VERSION ""

NS_ :

BS_:

BU_: ETH

BO_ 691 VCRIGHT_logging1Hz: 8 Vector__XXX
 SG_ VCRIGHT_logging1HzIndex M : 0|5@1+ (1,0) [0|0] "" Vector__XXX
 SG_ VCRIGHT_cabinOverheatProtectNotRunningReasonRaw m15 : 5|14@1+ (1,0) [0|0] "" Vector__XXX
 SG_ VCRIGHT_convectionTargetLeft m4 : 5|9@1+ (4,-1000) [0|0] "" Vector__XXX
 SG_ VCRIGHT_hvacCabOvrheatProtActive m8 : 5|1@1+ (1,0) [0|0] "" Vector__XXX
 SG_ VCRIGHT_hvacFoggingRiskLevelFeedforwardConservativeEst m5 : 5|6@1+ (1.6,0) [0|0] "" Vector__XXX
 SG_ VCRIGHT_hvacMassflowTargetLeft m12 : 5|8@1+ (1,0) [0|0] "" Vector__XXX
 SG_ VCRIGHT_leftHeatOvertempProtect m9 : 5|1@1+ (1,0) [0|0] "" Vector__XXX
 SG_ VCRIGHT_lumbarCurrent m10 : 5|4@1+ (0.2,0) [0|0] "" Vector__XXX
 SG_ VCRIGHT_maxMassflowScalar m13 : 5|6@1+ (1,60) [0|0] "" Vector__XXX
 SG_ VCRIGHT_pcbaTemperature m2 : 5|11@1+ (0.125,-40) [0|0] "" Vector__XXX
 SG_ VCRIGHT_steeringWheelSurfaceTempEst m14 : 5|10@1+ (0.1,-35) [0|0] "" Vector__XXX
 SG_ VCRIGHT_hvacCabinPurgeAllowed m8 : 6|1@1+ (1,0) [0|0] "" Vector__XXX
 SG_ VCRIGHT_rightHeatOvertempProtect m9 : 6|1@1+ (1,0) [0|0] "" Vector__XXX
 SG_ VCRIGHT_CO2ppm m9 : 7|10@1+ (5,0) [0|0] "" Vector__XXX
 SG_ VCRIGHT_hvacCabOvrheatProtAllowed m8 : 7|1@1+ (1,0) [0|0] "" Vector__XXX
 SG_ VCRIGHT_cabinTempBreathLevelFHeating m7 : 8|8@1+ (0.5,-40) [0|0] "" Vector__XXX
 SG_ VCRIGHT_cabinTempGlassRoof m1 : 8|8@1+ (0.5,-40) [0|0] "" Vector__XXX
 SG_ VCRIGHT_filterLifeBlowerTorque m8 : 8|10@1+ (0.006,-1.5) [0|0] "" Vector__XXX
 SG_ VCRIGHT_hvacEstimatedCameraWindshieldRH m16 : 8|8@1+ (1,0) [0|0] "" Vector__XXX
 SG_ VCRIGHT_hvacLHBleedVoltage m6 : 8|8@1+ (0.02,0) [0|0] "" Vector__XXX
 SG_ VCRIGHT_hvacSetTempActualLeft m3 : 8|8@1+ (0.1,15) [0|0] "" Vector__XXX
 SG_ VCRIGHT_tempIncarCabinProbe m0 : 8|8@1+ (0.5,-40) [0|0] "" Vector__XXX
 SG_ VCRIGHT_trunkInteriorLEDCurrent m11 : 8|4@1+ (5,0) [0|0] "" Vector__XXX
 SG_ VCRIGHT_ocsCurrent m10 : 9|3@1+ (0.01,0) [0|0] "" Vector__XXX
 SG_ VCRIGHT_hvacFoggingRiskLevelFeedforwardConservativeTar m5 : 11|6@1+ (1.6,0) [0|0] "" Vector__XXX
 SG_ VCRIGHT_massflowTargetAutoInManualMode m13 : 11|8@1+ (1,0) [0|0] "" Vector__XXX
 SG_ VCRIGHT_mapPocketLEDsCurrent m11 : 12|4@1+ (5,0) [0|0] "" Vector__XXX
 SG_ VCRIGHT_rcmCurrent m10 : 12|5@1+ (0.1,0) [0|0] "" Vector__XXX
 SG_ VCRIGHT_hvacMassflowTargetRight m12 : 13|8@1+ (1,0) [0|0] "" Vector__XXX
 SG_ VCRIGHT_convectionTargetRight m4 : 14|9@1+ (4,-1000) [0|0] "" Vector__XXX
 SG_ VCRIGHT_cabinTempBreathLevelFCooling m7 : 16|8@1+ (0.5,-40) [0|0] "" Vector__XXX
 SG_ VCRIGHT_cabinTempInteriorL2 m0 : 16|8@1+ (0.5,-40) [0|0] "" Vector__XXX
 SG_ VCRIGHT_cabinTempWindshield m1 : 16|8@1+ (0.5,-40) [0|0] "" Vector__XXX
 SG_ VCRIGHT_hvacRHBleedVoltage m6 : 16|8@1+ (0.02,0) [0|0] "" Vector__XXX
 SG_ VCRIGHT_hvacSetTempActualRight m3 : 16|8@1+ (0.1,15) [0|0] "" Vector__XXX
 SG_ VCRIGHT_miscEFuseCurrent m11 : 16|5@1+ (0.05,0) [0|0] "" Vector__XXX
 SG_ VCRIGHT_steeringWheelSurfaceTempTgt m14 : 16|10@1+ (0.1,-35) [0|0] "" Vector__XXX
 SG_ VCRIGHT_wattsHeaterLeftTotal m2 : 16|10@1+ (5,0) [0|0] "" Vector__XXX
 SG_ VCRIGHT_hvacFoggingRiskLevelConservativeTar m5 : 17|6@1+ (1.6,0) [0|0] "" Vector__XXX
 SG_ VCRIGHT_radioTunerCurrent m10 : 17|4@1+ (0.1,0) [0|0] "" Vector__XXX
 SG_ VCRIGHT_timeLeftToCabinModelInit m9 : 17|7@1+ (1,0) [0|0] "" Vector__XXX
 SG_ VCRIGHT_cabinTempFanCurrent m8 : 18|6@1+ (0.001,-0.01) [0|0] "" Vector__XXX
 SG_ VCRIGHT_airflowReasonAutoInManualMode m13 : 19|5@1+ (1,0) [0|0] "" Vector__XXX
 SG_ VCRIGHT_hvacIntakeReason m15 : 19|5@1+ (1,0) [0|0] "" Vector__XXX
 SG_ VCRIGHT_interiorHandleLEDCurrent m11 : 21|4@1+ (2,0) [0|0] "" Vector__XXX
 SG_ VCRIGHT_rearOilPumpCurrent m10 : 21|5@1+ (0.5,0) [0|0] "" Vector__XXX
 SG_ VCRIGHT_solarLoadLeftOccupantFilt m12 : 21|7@1+ (2,0) [0|0] "" Vector__XXX
 SG_ VCRIGHT_convectionDeliveredLeft m4 : 23|9@1+ (4,-1000) [0|0] "" Vector__XXX
 SG_ VCRIGHT_ptcHeaterTempDuctHigh m5 : 23|1@1+ (1,0) [0|0] "" Vector__XXX
 SG_ VCRIGHT_airflowReasonAutoInManualModeLeft m13 : 24|5@1+ (1,0) [0|0] "" Vector__XXX
 SG_ VCRIGHT_cabinTempFanOutput m8 : 24|1@1+ (1,0) [0|0] "" Vector__XXX
 SG_ VCRIGHT_cabinTempInterior m1 : 24|8@1+ (0.5,-40) [0|0] "" Vector__XXX
 SG_ VCRIGHT_cabinTempInteriorFHeating m7 : 24|8@1+ (0.5,-40) [0|0] "" Vector__XXX
 SG_ VCRIGHT_cabinTempInteriorSunnyL2 m0 : 24|8@1+ (0.6,-40) [0|0] "" Vector__XXX
 SG_ VCRIGHT_cabinTempRoofL2 m16 : 24|8@1+ (0.5,-40) [0|0] "" Vector__XXX
 SG_ VCRIGHT_hvacAutoTransitionReason m3 : 24|5@1+ (1,0) [0|0] "" Vector__XXX
 SG_ VCRIGHT_hvacCabinPurgeActive m15 : 24|1@1+ (1,0) [0|0] "" Vector__XXX
 SG_ VCRIGHT_hvacEstimateWindshieldRH m9 : 24|8@1+ (1,0) [0|0] "" Vector__XXX
 SG_ VCRIGHT_hvacLHVaneVoltage m6 : 24|8@1+ (0.02,0) [0|0] "" Vector__XXX
 SG_ VCRIGHT_ptcHeaterTempDuctFault m5 : 24|1@1+ (1,0) [0|0] "" Vector__XXX
 SG_ VCRIGHT_cloudinessEstimatedPct m8 : 25|7@1+ (1,0) [0|0] "" Vector__XXX
 SG_ VCRIGHT_miscInteriorLightsCurrent m11 : 25|3@1+ (5,0) [0|0] "" Vector__XXX
 SG_ VCRIGHT_ptcHeaterNoAirflow m5 : 25|1@1+ (1,0) [0|0] "" Vector__XXX
 SG_ VCRIGHT_solarAzimuthCarRef m15 : 25|11@1- (0.5,0) [0|0] "" Vector__XXX
 SG_ VCRIGHT_ptcHeaterHvacActNotReady m5 : 26|1@1+ (1,0) [0|0] "" Vector__XXX
 SG_ VCRIGHT_rearDefrostCurrent m10 : 26|5@1+ (2,0) [0|0] "" Vector__XXX
 SG_ VCRIGHT_timeToComfortHeating m14 : 26|6@1+ (15,-15) [0|0] "" Vector__XXX
 SG_ VCRIGHT_wattsHeaterRightTotal m2 : 26|10@1+ (5,0) [0|0] "" Vector__XXX
 SG_ VCRIGHT_ptcHeaterNoUiRequest m5 : 27|1@1+ (1,0) [0|0] "" Vector__XXX
 SG_ VCRIGHT_frontPuddleLEDCurrent m11 : 28|3@1+ (0.05,0) [0|0] "" Vector__XXX
 SG_ VCRIGHT_ptcHeaterNoHighVoltage m5 : 28|1@1+ (1,0) [0|0] "" Vector__XXX
 SG_ VCRIGHT_solarLoadRightOccupantFilt m12 : 28|7@1+ (2,0) [0|0] "" Vector__XXX
 SG_ VCRIGHT_airflowReasonAutoInManualModeRight m13 : 29|5@1+ (1,0) [0|0] "" Vector__XXX
 SG_ VCRIGHT_hvacMassflowTarget m3 : 29|8@1+ (1,0) [0|0] "" Vector__XXX
 SG_ VCRIGHT_ptcHeaterLAirPathBlocked m5 : 29|1@1+ (1,0) [0|0] "" Vector__XXX
 SG_ VCRIGHT_ptcHeaterRAirPathBlocked m5 : 30|1@1+ (1,0) [0|0] "" Vector__XXX
 SG_ VCRIGHT_ptcHeaterReqAirpathBlocked m5 : 31|1@1+ (1,0) [0|0] "" Vector__XXX
 SG_ VCRIGHT_rearPuddleLEDCurrent m11 : 31|3@1+ (0.05,0) [0|0] "" Vector__XXX
 SG_ VCRIGHT_tailLightCurrent m10 : 31|4@1+ (0.1,0) [0|0] "" Vector__XXX
 SG_ VCRIGHT_cabinTempInteriorSunny m1 : 32|8@1+ (0.6,-40) [0|0] "" Vector__XXX
 SG_ VCRIGHT_cabinTempRoofL3 m16 : 32|8@1+ (0.5,-40) [0|0] "" Vector__XXX
 SG_ VCRIGHT_convectionDeliveredRight m4 : 32|9@1+ (4,-1000) [0|0] "" Vector__XXX
 SG_ VCRIGHT_hvacFoggingRiskLevel m9 : 32|7@1+ (1,0) [0|0] "" Vector__XXX
 SG_ VCRIGHT_hvacFoggingRiskLevelConservativeEst m7 : 32|6@1+ (1.6,0) [0|0] "" Vector__XXX
 SG_ VCRIGHT_hvacQdotFeedforward m5 : 32|16@1+ (1,-32767) [0|0] "" Vector__XXX
 SG_ VCRIGHT_hvacRHVaneVoltage m6 : 32|8@1+ (0.02,0) [0|0] "" Vector__XXX
 SG_ VCRIGHT_solarLoadOnVehFiltered m8 : 32|8@1+ (4,0) [0|0] "" Vector__XXX
 SG_ VCRIGHT_tempIncarCabinMid m0 : 32|8@1+ (0.5,-40) [0|0] "" Vector__XXX
 SG_ VCRIGHT_timeToComfortCooling m14 : 32|6@1+ (15,-15) [0|0] "" Vector__XXX
 SG_ VCRIGHT_cabinTempInteriorFCooling m13 : 34|8@1+ (0.5,-40) [0|0] "" Vector__XXX
 SG_ VCRIGHT_liftgateShutfaceLEDCurrent m11 : 34|3@1+ (5,0) [0|0] "" Vector__XXX
 SG_ VCRIGHT_turnTailStopLightCurrent m10 : 35|4@1+ (0.1,0) [0|0] "" Vector__XXX
 SG_ VCRIGHT_windshieldRHCapped m12 : 35|8@1+ (1,0) [0|0] "" Vector__XXX
 SG_ VCRIGHT_massflowPulldownBias m15 : 36|4@1+ (7,0) [0|0] "" Vector__XXX
 SG_ VCRIGHT_qdotLeftFFUnsat m2 : 36|9@1- (10,0) [0|0] "" Vector__XXX
 SG_ VCRIGHT_3rSeatTOSCurrent m11 : 37|4@1+ (5,0) [0|0] "" Vector__XXX
 SG_ VCRIGHT_hvacQdotLimitedLeft m3 : 37|1@1+ (1,0) [0|0] "" Vector__XXX
 SG_ VCRIGHT_hvacQdotLimitedRight m3 : 38|1@1+ (1,0) [0|0] "" Vector__XXX
 SG_ VCRIGHT_hvacWindshieldRHConservativeEst m7 : 38|6@1+ (2,0) [0|0] "" Vector__XXX
 SG_ VCRIGHT_LHPanelAirflowBlocked m3 : 39|1@1+ (1,0) [0|0] "" Vector__XXX
 SG_ VCRIGHT_hvacCabinHumidityLevel m9 : 39|7@1+ (1,0) [0|0] "" Vector__XXX
 SG_ VCRIGHT_reverseFogLightsCurrent m10 : 39|4@1+ (0.1,0) [0|0] "" Vector__XXX
 SG_ VCRIGHT_RHPanelAirflowBlocked m3 : 40|1@1+ (1,0) [0|0] "" Vector__XXX
 SG_ VCRIGHT_cabinTempInteriorL3 m0 : 40|8@1+ (0.5,-40) [0|0] "" Vector__XXX
 SG_ VCRIGHT_cabinTempProbeEstimate m8 : 40|8@1+ (0.5,-40) [0|0] "" Vector__XXX
 SG_ VCRIGHT_cabinTempSideGlassLeft m1 : 40|8@1+ (0.5,-40) [0|0] "" Vector__XXX
 SG_ VCRIGHT_cabinWaterMassRaw m14 : 40|8@1+ (0.1,0) [0|0] "" Vector__XXX
 SG_ VCRIGHT_evapPulldownBias m15 : 40|4@1+ (7,0) [0|0] "" Vector__XXX
 SG_ VCRIGHT_hvacUpperModeVoltage m6 : 40|8@1+ (0.02,0) [0|0] "" Vector__XXX
 SG_ VCRIGHT_floorAirflowBlocked m3 : 41|1@1+ (1,0) [0|0] "" Vector__XXX
 SG_ VCRIGHT_solarLoadRightOccupant m4 : 41|7@1+ (2,0) [0|0] "" Vector__XXX
 SG_ VCRIGHT_vbatFusedCurrent m11 : 41|4@1+ (0.1,0) [0|0] "" Vector__XXX
 SG_ VCRIGHT_averageDuctTempFHeating m13 : 42|8@1+ (0.5,-40) [0|0] "" Vector__XXX
 SG_ VCRIGHT_defrostAirflowBlocked m3 : 42|1@1+ (1,0) [0|0] "" Vector__XXX
 SG_ VCRIGHT_feedbackWarmUpScalar m12 : 43|2@1+ (16,84) [0|0] "" Vector__XXX
 SG_ VCRIGHT_hvacFilterLifeDetectActive m3 : 43|1@1+ (1,0) [0|0] "" Vector__XXX
 SG_ VCRIGHT_stopReverseTurnLightCurrent m10 : 43|4@1+ (0.1,0) [0|0] "" Vector__XXX
 SG_ VCRIGHT_hvacFoggingRiskLevelFeedback m7 : 44|7@1- (1.6,0) [0|0] "" Vector__XXX
 SG_ VCRIGHT_hvacLHBleedOperationMode m3 : 44|1@1+ (1,0) [0|0] "" Vector__XXX
 SG_ VCRIGHT_modeledMassflowFresh m15 : 44|8@1+ (1,0) [0|0] "" Vector__XXX
 SG_ VCRIGHT_cabinTempGlassGridHeater m11 : 45|8@1+ (0.5,-40) [0|0] "" Vector__XXX
 SG_ VCRIGHT_hvacRHBleedOperationMode m3 : 45|1@1+ (1,0) [0|0] "" Vector__XXX
 SG_ VCRIGHT_maxMassflowScalarWarmUp m12 : 45|5@1+ (1,74) [0|0] "" Vector__XXX
 SG_ VCRIGHT_qdotRightFFUnsat m2 : 45|9@1- (10,0) [0|0] "" Vector__XXX
 SG_ VCRIGHT_hvacLHVaneOperationMode m3 : 46|1@1+ (1,0) [0|0] "" Vector__XXX
 SG_ VCRIGHT_hvacFlashFoggingDetected m9 : 47|1@1+ (1,0) [0|0] "" Vector__XXX
 SG_ VCRIGHT_hvacRHVaneOperationMode m3 : 47|1@1+ (1,0) [0|0] "" Vector__XXX
 SG_ VCRIGHT_sideMirrorCurrent m10 : 47|5@1+ (0.2,0) [0|0] "" Vector__XXX
 SG_ VCRIGHT_cabinTempInteriorSunnyL3 m0 : 48|8@1+ (0.6,-40) [0|0] "" Vector__XXX
 SG_ VCRIGHT_cabinTempSideGlassRight m1 : 48|8@1+ (0.5,-40) [0|0] "" Vector__XXX
 SG_ VCRIGHT_cabinTempThs m8 : 48|8@1+ (0.5,-40) [0|0] "" Vector__XXX
 SG_ VCRIGHT_cabinTempWshldDefog m5 : 48|8@1+ (0.5,-40) [0|0] "" Vector__XXX
 SG_ VCRIGHT_hvacLowerModeVoltage m6 : 48|8@1+ (0.02,0) [0|0] "" Vector__XXX
 SG_ VCRIGHT_hvacUpperModeOpMode m3 : 48|1@1+ (1,0) [0|0] "" Vector__XXX
 SG_ VCRIGHT_massflowSingleZoneSplit m14 : 48|7@1+ (1,0) [0|0] "" Vector__XXX
 SG_ VCRIGHT_solarLoadLeftOccupant m4 : 48|7@1+ (2,0) [0|0] "" Vector__XXX
 SG_ VCRIGHT_solarSensitivityInfr m9 : 48|7@1+ (1,0) [0|0] "" Vector__XXX
 SG_ VCRIGHT_hvacLowerModeOpMode m3 : 49|1@1+ (1,0) [0|0] "" Vector__XXX
 SG_ VCRIGHT_averageDuctTempFCooling m13 : 50|8@1+ (0.5,-40) [0|0] "" Vector__XXX
 SG_ VCRIGHT_feedforwardWarmUpScalar m12 : 50|6@1+ (1,80) [0|0] "" Vector__XXX
 SG_ VCRIGHT_hvacIntakeOperationMode m3 : 50|1@1+ (1,0) [0|0] "" Vector__XXX
 SG_ VCRIGHT_hvacFoggingRiskLevelIntegral m7 : 51|7@1- (1.6,0) [0|0] "" Vector__XXX
 SG_ VCRIGHT_isProbeFeedbackApplied m3 : 52|3@1+ (1,0) [0|0] "" Vector__XXX
 SG_ VCRIGHT_modeledMassflowRecirc m15 : 52|8@1+ (1,0) [0|0] "" Vector__XXX
 SG_ VCRIGHT_sideMirrorHeaterCurrent m10 : 52|5@1+ (0.2,0) [0|0] "" Vector__XXX
 SG_ VCRIGHT_hvacAirflowReasonRight m11 : 53|5@1+ (1,0) [0|0] "" Vector__XXX
 SG_ VCRIGHT_nvhLevelDb m2 : 54|9@1+ (0.1,30) [0|0] "" Vector__XXX
 SG_ VCRIGHT_feedbackPullDownScalar m3 : 55|2@1+ (30,70) [0|0] "" Vector__XXX
 SG_ VCRIGHT_ptcShutOutletMitigationActive m4 : 55|1@1+ (1,0) [0|0] "" Vector__XXX
 SG_ VCRIGHT_solarSensitivityInfrCorr m9 : 55|7@1+ (1,0) [0|0] "" Vector__XXX
 SG_ VCRIGHT_VOCPurgeState m14 : 56|3@1+ (1,0) [0|0] "" Vector__XXX
 SG_ VCRIGHT_cabinTempBreathLevel m1 : 56|8@1+ (0.5,-40) [0|0] "" Vector__XXX
 SG_ VCRIGHT_cabinTempThsBracket m8 : 56|8@1+ (0.5,-40) [0|0] "" Vector__XXX
 SG_ VCRIGHT_cabinTempWshldDefogTop m5 : 56|8@1+ (0.5,-40) [0|0] "" Vector__XXX
 SG_ VCRIGHT_frontSeatHeatBackrestPwr m12 : 56|7@1+ (1,0) [0|0] "" Vector__XXX
 SG_ VCRIGHT_hvacIntakeVoltage m6 : 56|8@1+ (0.02,0) [0|0] "" Vector__XXX
 SG_ VCRIGHT_solarLoadFromThsTemp m4 : 56|8@1+ (8,-1020) [0|0] "" Vector__XXX
 SG_ VCRIGHT_tempWetBulb m0 : 56|8@1+ (0.5,-40) [0|0] "" Vector__XXX
 SG_ VCRIGHT_feedForwardPullDownScalar m3 : 57|6@1+ (1,70) [0|0] "" Vector__XXX
 SG_ VCRIGHT_frontSeatHeatCushionPwr m10 : 57|7@1+ (1,0) [0|0] "" Vector__XXX
 SG_ VCRIGHT_hvacAirflowReasonLeft m11 : 58|5@1+ (1,0) [0|0] "" Vector__XXX
 SG_ VCRIGHT_hvacBiLevelWhsldRhEst m13 : 58|6@1+ (2,20) [0|0] "" Vector__XXX
 SG_ VCRIGHT_hvacFoggingRiskLevelFeedforward m7 : 58|6@1+ (1.6,0) [0|0] "" Vector__XXX
 SG_ VCRIGHT_cameraFoggingMonitorState m14 : 59|3@1+ (1,0) [0|0] "" Vector__XXX
 SG_ VCRIGHT_hvacLimpModeStatus m15 : 60|3@1+ (1,0) [0|0] "" Vector__XXX

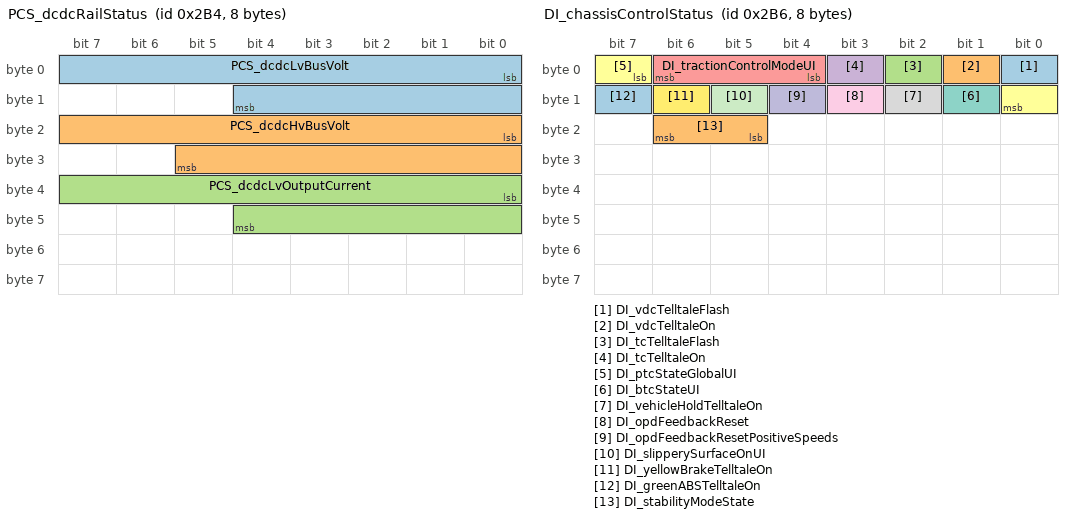
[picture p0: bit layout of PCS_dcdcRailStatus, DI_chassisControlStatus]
BO_ 692 PCS_dcdcRailStatus: 8 Vector__XXX
 SG_ PCS_dcdcLvBusVolt : 0|13@1+ (0.01,0) [0|0] "" Vector__XXX
 SG_ PCS_dcdcHvBusVolt : 16|14@1+ (0.1,0) [0|0] "" Vector__XXX
 SG_ PCS_dcdcLvOutputCurrent : 32|13@1- (0.1,0) [0|0] "" Vector__XXX

BO_ 694 DI_chassisControlStatus: 8 Vector__XXX
 SG_ DI_vdcTelltaleFlash : 0|1@1+ (1,0) [0|0] "" Vector__XXX
 SG_ DI_vdcTelltaleOn : 1|1@1+ (1,0) [0|0] "" Vector__XXX
 SG_ DI_tcTelltaleFlash : 2|1@1+ (1,0) [0|0] "" Vector__XXX
 SG_ DI_tcTelltaleOn : 3|1@1+ (1,0) [0|0] "" Vector__XXX
 SG_ DI_tractionControlModeUI : 4|3@1+ (1,0) [0|0] "" Vector__XXX
 SG_ DI_ptcStateGlobalUI : 7|2@1+ (1,0) [0|0] "" Vector__XXX
 SG_ DI_btcStateUI : 9|1@1+ (1,0) [0|0] "" Vector__XXX
 SG_ DI_vehicleHoldTelltaleOn : 10|1@1+ (1,0) [0|0] "" Vector__XXX
 SG_ DI_opdFeedbackReset : 11|1@1+ (1,0) [0|0] "" Vector__XXX
 SG_ DI_opdFeedbackResetPositiveSpeeds : 12|1@1+ (1,0) [0|0] "" Vector__XXX
 SG_ DI_slipperySurfaceOnUI : 13|1@1+ (1,0) [0|0] "" Vector__XXX
 SG_ DI_yellowBrakeTelltaleOn : 14|1@1+ (1,0) [0|0] "" Vector__XXX
 SG_ DI_greenABSTelltaleOn : 15|1@1+ (1,0) [0|0] "" Vector__XXX
 SG_ DI_stabilityModeState : 21|2@1+ (1,0) [0|0] "" Vector__XXX

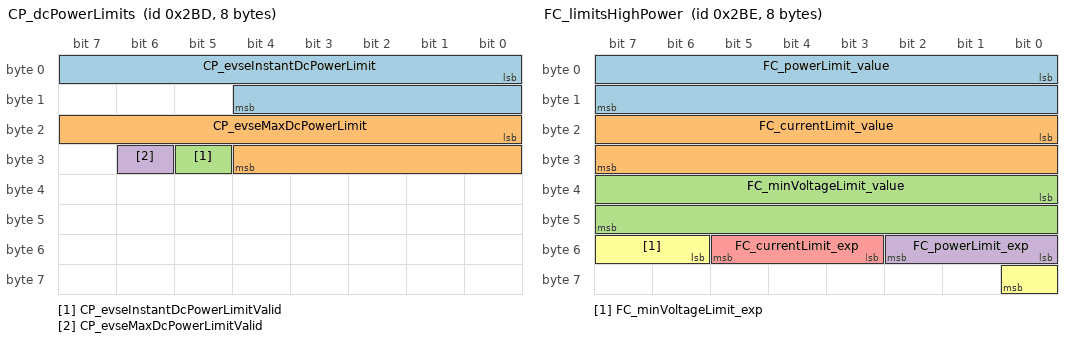
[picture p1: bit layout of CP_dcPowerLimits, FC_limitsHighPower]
BO_ 701 CP_dcPowerLimits: 8 Vector__XXX
 SG_ CP_evseInstantDcPowerLimit : 0|13@1+ (0.25,0) [0|0] "" Vector__XXX
 SG_ CP_evseMaxDcPowerLimit : 16|13@1+ (0.25,0) [0|0] "" Vector__XXX
 SG_ CP_evseInstantDcPowerLimitValid : 29|1@1+ (1,0) [0|0] "" Vector__XXX
 SG_ CP_evseMaxDcPowerLimitValid : 30|1@1+ (1,0) [0|0] "" Vector__XXX

BO_ 702 FC_limitsHighPower: 8 Vector__XXX
 SG_ FC_powerLimit_value : 0|16@1- (1,0) [0|0] "" Vector__XXX
 SG_ FC_currentLimit_value : 16|16@1- (1,0) [0|0] "" Vector__XXX
 SG_ FC_minVoltageLimit_value : 32|16@1- (1,0) [0|0] "" Vector__XXX
 SG_ FC_powerLimit_exp : 48|3@1- (1,0) [0|0] "" Vector__XXX
 SG_ FC_currentLimit_exp : 51|3@1- (1,0) [0|0] "" Vector__XXX
 SG_ FC_minVoltageLimit_exp : 54|3@1- (1,0) [0|0] "" Vector__XXX

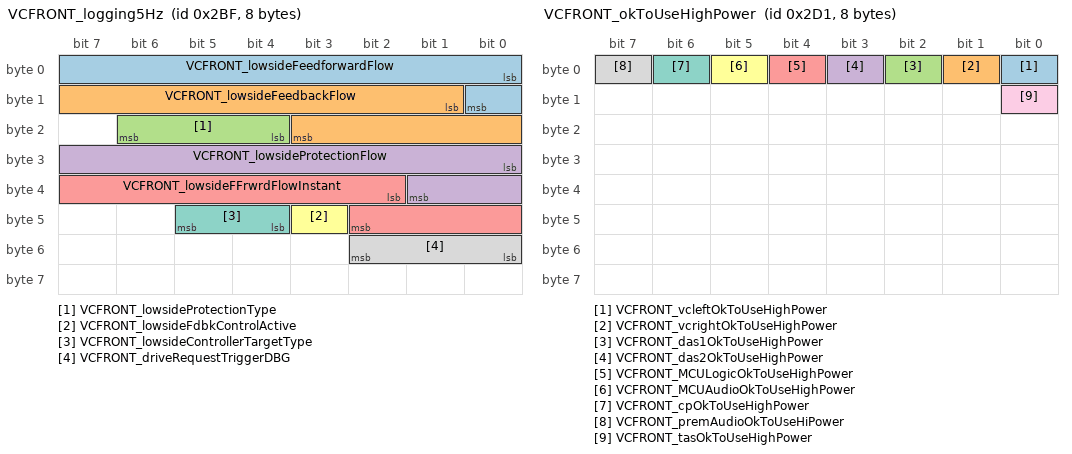
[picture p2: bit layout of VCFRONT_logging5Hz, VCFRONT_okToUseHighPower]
BO_ 703 VCFRONT_logging5Hz: 8 Vector__XXX
 SG_ VCFRONT_lowsideFeedforwardFlow : 0|9@1+ (0.2,0) [0|0] "" Vector__XXX
 SG_ VCFRONT_lowsideFeedbackFlow : 9|11@1- (0.1,0) [0|0] "" Vector__XXX
 SG_ VCFRONT_lowsideProtectionType : 20|3@1+ (1,0) [0|0] "" Vector__XXX
 SG_ VCFRONT_lowsideProtectionFlow : 24|10@1+ (0.1,0) [0|0] "" Vector__XXX
 SG_ VCFRONT_lowsideFFrwrdFlowInstant : 34|9@1+ (0.2,0) [0|0] "" Vector__XXX
 SG_ VCFRONT_lowsideFdbkControlActive : 43|1@1+ (1,0) [0|0] "" Vector__XXX
 SG_ VCFRONT_lowsideControllerTargetType : 44|2@1+ (1,0) [0|0] "" Vector__XXX
 SG_ VCFRONT_driveRequestTriggerDBG : 48|3@1+ (1,0) [0|0] "" Vector__XXX

BO_ 705 VCFRONT_logging10Hz: 8 Vector__XXX
 SG_ VCFRONT_logging10HzIndex M : 0|3@1+ (1,0) [0|0] "" Vector__XXX
 SG_ VCFRONT_activeLouverMotorCounts m3 : 3|11@1+ (1,-100) [0|0] "" Vector__XXX
 SG_ VCFRONT_chillerExvTorqueCountAvailable m4 : 3|1@1+ (1,0) [0|0] "" Vector__XXX
 SG_ VCFRONT_pumpBatteryOutVoltage m0 : 3|7@1+ (0.2,0) [0|0] "" Vector__XXX
 SG_ VCFRONT_radiatorFanDemandLimit m1 : 3|7@1+ (1,0) [0|0] "" Vector__XXX
 SG_ VCFRONT_evapExvTorqueCountAvailable m4 : 4|1@1+ (1,0) [0|0] "" Vector__XXX
 SG_ VCFRONT_recircExvTorqueCountAvailable m4 : 5|1@1+ (1,0) [0|0] "" Vector__XXX
 SG_ VCFRONT_lccExvTorqueCountAvailable m4 : 6|1@1+ (1,0) [0|0] "" Vector__XXX
 SG_ VCFRONT_ccLeftExvTorqueCountAvailable m4 : 7|1@1+ (1,0) [0|0] "" Vector__XXX
 SG_ VCFRONT_ccRightExvTorqueCountAvailable m4 : 8|1@1+ (1,0) [0|0] "" Vector__XXX
 SG_ VCFRONT_compRampRateUpMax m2 : 8|7@1+ (0.2,0) [0|0] "" Vector__XXX
 SG_ VCFRONT_pumpPowertrainOutVoltage m0 : 10|7@1+ (0.2,0) [0|0] "" Vector__XXX
 SG_ VCFRONT_radiatorFanDemandLimited m1 : 10|1@1+ (1,0) [0|0] "" Vector__XXX
 SG_ VCFRONT_coolantValveAngleActual m1 : 11|11@1+ (0.25,-100) [0|0] "" Vector__XXX
 SG_ VCFRONT_refrigerantValvesClosed m2 : 15|1@1+ (1,0) [0|0] "" Vector__XXX
 SG_ VCFRONT_activeLouverCalibRange m3 : 16|8@1+ (1,630) [0|0] "" Vector__XXX
 SG_ VCFRONT_chillerExvTorqueCount m4 : 16|8@1+ (1,0) [0|0] "" Vector__XXX
 SG_ VCFRONT_exvMotorState m2 : 16|4@1+ (1,0) [0|0] "" Vector__XXX
 SG_ VCFRONT_pumpBatteryInitd m0 : 17|1@1+ (1,0) [0|0] "" Vector__XXX
 SG_ VCFRONT_pumpPowertrainInitd m0 : 18|1@1+ (1,0) [0|0] "" Vector__XXX
 SG_ VCFRONT_pumpBatteryEnabled m0 : 19|1@1+ (1,0) [0|0] "" Vector__XXX
 SG_ VCFRONT_exvFlow m2 : 20|8@1+ (0.5,0) [0|0] "" Vector__XXX
 SG_ VCFRONT_pumpPowertrainEnabled m0 : 20|1@1+ (1,0) [0|0] "" Vector__XXX
 SG_ VCFRONT_pumpBatteryPowerOn m0 : 21|1@1+ (1,0) [0|0] "" Vector__XXX
 SG_ VCFRONT_coolantValveAngleTarget m1 : 22|10@1+ (0.25,-5) [0|0] "" Vector__XXX
 SG_ VCFRONT_pumpPowertrainPowerOn m0 : 22|1@1+ (1,0) [0|0] "" Vector__XXX
 SG_ VCFRONT_pumpsWake m0 : 23|1@1+ (1,0) [0|0] "" Vector__XXX
 SG_ VCFRONT_evapExvTorqueCount m4 : 24|8@1+ (1,0) [0|0] "" Vector__XXX
 SG_ VCFRONT_pumpBatSpiError m0 : 24|1@1+ (1,0) [0|0] "" Vector__XXX
 SG_ VCFRONT_radarHeaterCurrent m3 : 24|8@1+ (0.1,0) [0|0] "" Vector__XXX
 SG_ VCFRONT_pumpPtSpiError m0 : 25|1@1+ (1,0) [0|0] "" Vector__XXX
 SG_ VCFRONT_coolantFlowChillerActual m0 : 26|8@1+ (0.1,0) [0|0] "" Vector__XXX
 SG_ VCFRONT_exvIsFlooding m2 : 28|1@1+ (1,0) [0|0] "" Vector__XXX
 SG_ VCFRONT_exvPrechillActive m2 : 29|1@1+ (1,0) [0|0] "" Vector__XXX
 SG_ VCFRONT_usingSimulatedSuctTemp m2 : 30|1@1+ (1,0) [0|0] "" Vector__XXX
 SG_ VCFRONT_usingSimulatedDischTemp m2 : 31|1@1+ (1,0) [0|0] "" Vector__XXX
 SG_ VCFRONT_coolantValveState m1 : 32|2@1+ (1,0) [0|0] "" Vector__XXX
 SG_ VCFRONT_radarHeaterDuty m3 : 32|7@1+ (1,0) [0|0] "" Vector__XXX
 SG_ VCFRONT_recircExvTorqueCount m4 : 32|8@1+ (1,0) [0|0] "" Vector__XXX
 SG_ VCFRONT_usingSimulatedAmbTemp m2 : 32|1@1+ (1,0) [0|0] "" Vector__XXX
 SG_ VCFRONT_solenoidEvapCurrent m2 : 33|6@1+ (0.04,0) [0|0] "" Vector__XXX
 SG_ VCFRONT_coolantValveDuty m1 : 34|8@1- (1,0) [0|0] "" Vector__XXX
 SG_ VCFRONT_radiatorFanOutVoltage m0 : 34|7@1+ (0.2,0) [0|0] "" Vector__XXX
 SG_ VCFRONT_activeLouverAbnormalKT m2 : 39|1@1+ (1,0) [0|0] "" Vector__XXX
 SG_ VCFRONT_activeLouverOverCurrent m2 : 40|1@1+ (1,0) [0|0] "" Vector__XXX
 SG_ VCFRONT_lccExvTorqueCount m4 : 40|8@1+ (1,0) [0|0] "" Vector__XXX
 SG_ VCFRONT_radarHeaterTargetVoltage m3 : 40|8@1+ (0.1,0) [0|0] "" Vector__XXX
 SG_ VCFRONT_activeLouverOverTemp m2 : 41|1@1+ (1,0) [0|0] "" Vector__XXX
 SG_ VCFRONT_radiatorFanInitd m0 : 41|1@1+ (1,0) [0|0] "" Vector__XXX
 SG_ VCFRONT_activeLouverDisconnect m2 : 42|1@1+ (1,0) [0|0] "" Vector__XXX
 SG_ VCFRONT_coolantValveISense m1 : 42|5@1+ (0.05,0) [0|0] "" Vector__XXX
 SG_ VCFRONT_radiatorFanEnabled m0 : 42|1@1+ (1,0) [0|0] "" Vector__XXX
 SG_ VCFRONT_activeLouverStalled m2 : 43|1@1+ (1,0) [0|0] "" Vector__XXX
 SG_ VCFRONT_radiatorFanPowerOn m0 : 43|1@1+ (1,0) [0|0] "" Vector__XXX
 SG_ VCFRONT_activeLouverMotorState m2 : 44|3@1+ (1,0) [0|0] "" Vector__XXX
 SG_ VCFRONT_radiatorFanPhaseCurrent m0 : 44|8@1+ (0.25,-10) [0|0] "" Vector__XXX
 SG_ VCFRONT_activeLouverCommSuccess m2 : 47|1@1+ (1,0) [0|0] "" Vector__XXX
 SG_ VCFRONT_compLimitPresDischargeHi m1 : 47|1@1+ (1,0) [0|0] "" Vector__XXX
 SG_ VCFRONT_COP1PdOscillationDetected m3 : 48|1@1+ (1,0) [0|0] "" Vector__XXX
 SG_ VCFRONT_activeLouverStallOL m2 : 48|1@1+ (1,0) [0|0] "" Vector__XXX
 SG_ VCFRONT_ccLeftExvTorqueCount m4 : 48|8@1+ (1,0) [0|0] "" Vector__XXX
 SG_ VCFRONT_compLimitTempDischargeHi m1 : 48|1@1+ (1,0) [0|0] "" Vector__XXX
 SG_ VCFRONT_COP1PdOscillationPurge m3 : 49|1@1+ (1,0) [0|0] "" Vector__XXX
 SG_ VCFRONT_activeLouverIsCalibrated m2 : 49|1@1+ (1,0) [0|0] "" Vector__XXX
 SG_ VCFRONT_compLimitScrollSepRegion m1 : 49|1@1+ (1,0) [0|0] "" Vector__XXX
 SG_ VCFRONT_activeLouverDemand m2 : 50|7@1+ (1,0) [0|0] "" Vector__XXX
 SG_ VCFRONT_compLimitNvh m1 : 50|1@1+ (1,0) [0|0] "" Vector__XXX
 SG_ VCFRONT_wiperHeaterCurrent m3 : 50|9@1+ (0.032,0) [0|0] "" Vector__XXX
 SG_ VCFRONT_compLimitScrollSepRamp m1 : 51|1@1+ (1,0) [0|0] "" Vector__XXX
 SG_ VCFRONT_compLimitDeadband m1 : 52|1@1+ (1,0) [0|0] "" Vector__XXX
 SG_ VCFRONT_radiatorFanPhaseIMax m0 : 52|7@1+ (0.25,5) [0|0] "" Vector__XXX
 SG_ VCFRONT_compStandbySelfNotReady m1 : 53|1@1+ (1,0) [0|0] "" Vector__XXX
 SG_ VCFRONT_compStandbyCommunication m1 : 54|1@1+ (1,0) [0|0] "" Vector__XXX
 SG_ VCFRONT_compStandbyHVNotReady m1 : 55|1@1+ (1,0) [0|0] "" Vector__XXX
 SG_ VCFRONT_ccRightExvTorqueCount m4 : 56|8@1+ (1,0) [0|0] "" Vector__XXX
 SG_ VCFRONT_compStandbyLowAmbient m1 : 56|1@1+ (1,0) [0|0] "" Vector__XXX
 SG_ VCFRONT_activeLouverFalsStallRun m2 : 57|1@1+ (1,0) [0|0] "" Vector__XXX
 SG_ VCFRONT_compStandbyLowDischPress m1 : 57|1@1+ (1,0) [0|0] "" Vector__XXX
 SG_ VCFRONT_activeLouverFalsStallCal m2 : 58|1@1+ (1,0) [0|0] "" Vector__XXX
 SG_ VCFRONT_compStandbyRefrigNotOk m1 : 58|1@1+ (1,0) [0|0] "" Vector__XXX
 SG_ VCFRONT_activeLouverStallCounter m2 : 59|3@1+ (1,0) [0|0] "" Vector__XXX
 SG_ VCFRONT_compStandbyMultiplePdCutouts m1 : 59|1@1+ (1,0) [0|0] "" Vector__XXX
 SG_ VCFRONT_thmlFanSpiError m0 : 59|1@1+ (1,0) [0|0] "" Vector__XXX
 SG_ VCFRONT_chargeTrapNominalCOP1BattHeat m0 : 60|1@1+ (1,0) [0|0] "" Vector__XXX
 SG_ VCFRONT_compStandbyMultipleTdCutouts m1 : 60|1@1+ (1,0) [0|0] "" Vector__XXX
 SG_ VCFRONT_chargeTrapNominalCOP1ChillerBattHeat m0 : 61|1@1+ (1,0) [0|0] "" Vector__XXX
 SG_ VCFRONT_compLimitTempDischargeSim m1 : 61|1@1+ (1,0) [0|0] "" Vector__XXX
 SG_ VCFRONT_COP1OilWarmingActive m1 : 62|1@1+ (1,0) [0|0] "" Vector__XXX
 SG_ VCFRONT_COP1OilWarmingNeeded m0 : 62|1@1+ (1,0) [0|0] "" Vector__XXX
 SG_ VCFRONT_compressorDelayEnabled m2 : 62|1@1+ (1,0) [0|0] "" Vector__XXX
 SG_ VCFRONT_compLimitHvPowerBudget m1 : 63|1@1+ (1,0) [0|0] "" Vector__XXX
 SG_ VCFRONT_compressorDwellEnabled m2 : 63|1@1+ (1,0) [0|0] "" Vector__XXX

BO_ 706 VCLEFT_windowStatus: 8 Vector__XXX
 SG_ VCLEFT_windowStatusIndex M : 0|1@1+ (1,0) [0|0] "" Vector__XXX
 SG_ VCLEFT_windowStateLF m0 : 1|4@1+ (1,0) [0|0] "" Vector__XXX
 SG_ VCLEFT_windowThermalTCLF m1 : 1|8@1+ (1,0) [0|0] "" Vector__XXX
 SG_ VCLEFT_windowTrimClearMoveRequest m0 : 5|2@1+ (1,0) [0|0] "" Vector__XXX
 SG_ VCLEFT_windowDutyLF m0 : 8|6@1- (5,0) [0|0] "" Vector__XXX
 SG_ VCLEFT_windowThermalModeLF m1 : 9|2@1+ (1,0) [0|0] "" Vector__XXX
 SG_ VCLEFT_windowStopReasonLF m1 : 11|3@1+ (1,0) [0|0] "" Vector__XXX
 SG_ VCLEFT_windowStopReqReasonLF m1 : 14|4@1+ (1,0) [0|0] "" Vector__XXX
 SG_ VCLEFT_windowTrimClearActiveRequest m0 : 14|2@1+ (1,0) [0|0] "" Vector__XXX
 SG_ VCLEFT_windowCurrentLF m0 : 16|6@1- (0.5,0) [0|0] "" Vector__XXX
 SG_ VCLEFT_windowThermalTCLR m1 : 18|8@1+ (1,0) [0|0] "" Vector__XXX
 SG_ VCLEFT_windowPositionLF m0 : 22|9@1- (1.25,265) [0|0] "" Vector__XXX
 SG_ VCLEFT_windowThermalModeLR m1 : 26|2@1+ (1,0) [0|0] "" Vector__XXX
 SG_ VCLEFT_windowStopReasonLR m1 : 28|3@1+ (1,0) [0|0] "" Vector__XXX
 SG_ VCLEFT_windowStopReqReasonLR m1 : 31|4@1+ (1,0) [0|0] "" Vector__XXX
 SG_ VCLEFT_windowCalibratedLF m0 : 32|1@1+ (1,0) [0|0] "" Vector__XXX
 SG_ VCLEFT_windowStateLR m0 : 33|4@1+ (1,0) [0|0] "" Vector__XXX
 SG_ VCLEFT_windowControlStateLF m1 : 35|2@1+ (1,0) [0|0] "" Vector__XXX
 SG_ VCLEFT_windowCtrlUnavailableLF m1 : 38|3@1+ (1,0) [0|0] "" Vector__XXX
 SG_ VCLEFT_windowDutyLR m0 : 40|6@1- (5,0) [0|0] "" Vector__XXX
 SG_ VCLEFT_windowControlStateLR m1 : 42|2@1+ (1,0) [0|0] "" Vector__XXX
 SG_ VCLEFT_windowCtrlUnavailableLR m1 : 45|3@1+ (1,0) [0|0] "" Vector__XXX
 SG_ VCLEFT_windowCurrentLR m0 : 48|6@1- (0.5,0) [0|0] "" Vector__XXX
 SG_ VCLEFT_windowPositionStateLF m1 : 49|3@1+ (1,0) [0|0] "" Vector__XXX
 SG_ VCLEFT_windowPositionStateLR m1 : 52|3@1+ (1,0) [0|0] "" Vector__XXX
 SG_ VCLEFT_windowPositionLR m0 : 54|9@1- (1.25,265) [0|0] "" Vector__XXX
 SG_ VCLEFT_windowVehGearStateLF m1 : 56|2@1+ (1,0) [0|0] "" Vector__XXX
 SG_ VCLEFT_windowVehGearStateLR m1 : 58|2@1+ (1,0) [0|0] "" Vector__XXX
 SG_ VCLEFT_windowSpeedTableStatusLF m1 : 60|2@1+ (1,0) [0|0] "" Vector__XXX
 SG_ VCLEFT_windowSpeedTableStatusLR m1 : 62|2@1+ (1,0) [0|0] "" Vector__XXX
 SG_ VCLEFT_windowCalibratedLR m0 : 63|1@1+ (1,0) [0|0] "" Vector__XXX

BO_ 707 VCRIGHT_windowStatus: 8 Vector__XXX
 SG_ VCRIGHT_windowStatusIndex M : 0|1@1+ (1,0) [0|0] "" Vector__XXX
 SG_ VCRIGHT_windowStateRF m0 : 1|4@1+ (1,0) [0|0] "" Vector__XXX
 SG_ VCRIGHT_windowThermalTCRF m1 : 1|8@1+ (1,0) [0|0] "" Vector__XXX
 SG_ VCRIGHT_windowTrimClearMoveRequest m0 : 5|2@1+ (1,0) [0|0] "" Vector__XXX
 SG_ VCRIGHT_windowDutyRF m0 : 8|6@1- (5,0) [0|0] "" Vector__XXX
 SG_ VCRIGHT_windowThermalModeRF m1 : 9|2@1+ (1,0) [0|0] "" Vector__XXX
 SG_ VCRIGHT_windowStopReasonRF m1 : 11|3@1+ (1,0) [0|0] "" Vector__XXX
 SG_ VCRIGHT_windowStopReqReasonRF m1 : 14|4@1+ (1,0) [0|0] "" Vector__XXX
 SG_ VCRIGHT_windowTrimClearActiveRequest m0 : 14|2@1+ (1,0) [0|0] "" Vector__XXX
 SG_ VCRIGHT_windowCurrentRF m0 : 16|6@1- (0.5,0) [0|0] "" Vector__XXX
 SG_ VCRIGHT_windowThermalTCRR m1 : 18|8@1+ (1,0) [0|0] "" Vector__XXX
 SG_ VCRIGHT_windowPositionRF m0 : 22|9@1- (1.25,265) [0|0] "" Vector__XXX
 SG_ VCRIGHT_windowThermalModeRR m1 : 26|2@1+ (1,0) [0|0] "" Vector__XXX
 SG_ VCRIGHT_windowStopReasonRR m1 : 28|3@1+ (1,0) [0|0] "" Vector__XXX
 SG_ VCRIGHT_windowStopReqReasonRR m1 : 31|4@1+ (1,0) [0|0] "" Vector__XXX
 SG_ VCRIGHT_windowCalibratedRF m0 : 32|1@1+ (1,0) [0|0] "" Vector__XXX
 SG_ VCRIGHT_windowStateRR m0 : 33|4@1+ (1,0) [0|0] "" Vector__XXX
 SG_ VCRIGHT_windowControlStateRF m1 : 35|2@1+ (1,0) [0|0] "" Vector__XXX
 SG_ VCRIGHT_windowCtrlUnavailableRF m1 : 38|3@1+ (1,0) [0|0] "" Vector__XXX
 SG_ VCRIGHT_windowDutyRR m0 : 40|6@1- (5,0) [0|0] "" Vector__XXX
 SG_ VCRIGHT_windowControlStateRR m1 : 42|2@1+ (1,0) [0|0] "" Vector__XXX
 SG_ VCRIGHT_windowCtrlUnavailableRR m1 : 45|3@1+ (1,0) [0|0] "" Vector__XXX
 SG_ VCRIGHT_windowCurrentRR m0 : 48|6@1- (0.5,0) [0|0] "" Vector__XXX
 SG_ VCRIGHT_windowPositionStateRF m1 : 49|3@1+ (1,0) [0|0] "" Vector__XXX
 SG_ VCRIGHT_windowPositionStateRR m1 : 52|3@1+ (1,0) [0|0] "" Vector__XXX
 SG_ VCRIGHT_windowPositionRR m0 : 54|9@1- (1.25,265) [0|0] "" Vector__XXX
 SG_ VCRIGHT_windowVehGearStateRF m1 : 56|2@1+ (1,0) [0|0] "" Vector__XXX
 SG_ VCRIGHT_windowVehGearStateRR m1 : 58|2@1+ (1,0) [0|0] "" Vector__XXX
 SG_ VCRIGHT_windowSpeedTableStatusRF m1 : 60|2@1+ (1,0) [0|0] "" Vector__XXX
 SG_ VCRIGHT_windowSpeedTableStatusRR m1 : 62|2@1+ (1,0) [0|0] "" Vector__XXX
 SG_ VCRIGHT_windowCalibratedRR m0 : 63|1@1+ (1,0) [0|0] "" Vector__XXX

BO_ 708 PCS_logging: 8 Vector__XXX
 SG_ PCS_logMessageSelect M : 0|5@1+ (1,0) [0|0] "" Vector__XXX
 SG_ PCS_chgInputFrequencyL1N m4 : 5|12@1+ (0.01,40) [0|0] "" Vector__XXX
 SG_ PCS_chgInputL1NVdc m21 : 5|10@1- (1,0) [0|0] "" Vector__XXX
 SG_ PCS_chgInputL1NVrms m3 : 5|12@1+ (0.2,0) [0|0] "" Vector__XXX
 SG_ PCS_chgPHAInputVPeak10s m13 : 5|9@1+ (1,0) [0|0] "" Vector__XXX
 SG_ PCS_chgPhAInputIrms m0 : 5|9@1+ (0.1,0) [0|0] "" Vector__XXX
 SG_ PCS_chgPhAIntBusVMin10s m10 : 5|9@1+ (1,0) [0|0] "" Vector__XXX
 SG_ PCS_chgPhAMachineEnabled m23 : 5|1@1+ (1,0) [0|0] "" Vector__XXX
 SG_ PCS_chgPhANoFlowBucket m20 : 5|9@1+ (0.01,0) [0|0] "" Vector__XXX
 SG_ PCS_chgPhAState m5 : 5|4@1+ (1,0) [0|0] "" Vector__XXX
 SG_ PCS_chgPhBInputIrms m1 : 5|9@1+ (0.1,0) [0|0] "" Vector__XXX
 SG_ PCS_chgPhBIntBusVMin10s m11 : 5|9@1+ (1,0) [0|0] "" Vector__XXX
 SG_ PCS_chgPhCInputIrms m2 : 5|9@1+ (0.1,0) [0|0] "" Vector__XXX
 SG_ PCS_chgPhCIntBusVMin10s m12 : 5|9@1+ (1,0) [0|0] "" Vector__XXX
 SG_ PCS_cpu2BootState m9 : 5|2@1+ (1,0) [0|0] "" Vector__XXX
 SG_ PCS_dLogPhAChannel1Content m14 : 5|2@1+ (1,0) [0|0] "" Vector__XXX
 SG_ PCS_dLogPhAChannel2Content m15 : 5|2@1+ (1,0) [0|0] "" Vector__XXX
 SG_ PCS_dLogPhAChannel3Content m16 : 5|2@1+ (1,0) [0|0] "" Vector__XXX
 SG_ PCS_dLogPhAChannel4Content m17 : 5|2@1+ (1,0) [0|0] "" Vector__XXX
 SG_ PCS_dcdcPchgStartLvBusVolt m24 : 5|10@1+ (0.0390625,0) [0|0] "" Vector__XXX
 SG_ PCS_dcdcTCommMeasured m8 : 5|16@1- (0.001953125,0) [0|0] "" Vector__XXX
 SG_ PCS_dcdcUnifiedCommand m7 : 5|10@1+ (0.001,0) [0|0] "" Vector__XXX
 SG_ PCS_chgPhAMachineRotorFreqDroop m23 : 6|10@1- (0.01,0) [0|0] "" Vector__XXX
 SG_ PCS_acChargeSelfTestState m9 : 7|1@1+ (1,0) [0|0] "" Vector__XXX
 SG_ PCS_1V5Min10s m9 : 8|11@1+ (0.001,0) [0|0] "" Vector__XXX
 SG_ PCS_dLogPhBChannel1Content m14 : 8|2@1+ (1,0) [0|0] "" Vector__XXX
 SG_ PCS_dLogPhBChannel2Content m15 : 8|2@1+ (1,0) [0|0] "" Vector__XXX
 SG_ PCS_dLogPhBChannel3Content m16 : 8|2@1+ (1,0) [0|0] "" Vector__XXX
 SG_ PCS_dLogPhBChannel4Content m17 : 8|2@1+ (1,0) [0|0] "" Vector__XXX
 SG_ PCS_dcdcIntervalMaxFrequency m18 : 8|12@1+ (1,0) [0|0] "" Vector__XXX
 SG_ PCS_dcdcIntervalMinFrequency m19 : 8|12@1+ (1,0) [0|0] "" Vector__XXX
 SG_ PCS_dcdcLvSupportLifetimekWh m22 : 8|24@1+ (0.01,0) [0|0] "" Vector__XXX
 SG_ PCS_dcdcMaxLvOutputCurrent m6 : 8|12@1+ (0.1,0) [0|0] "" Vector__XXX
 SG_ PCS_processorDieIdLot m25 : 8|24@1+ (1,0) [0|0] "" Vector__XXX
 SG_ PCS_chgPhBState m5 : 9|4@1+ (1,0) [0|0] "" Vector__XXX
 SG_ PCS_dLogPhCChannel1Content m14 : 10|2@1+ (1,0) [0|0] "" Vector__XXX
 SG_ PCS_dLogPhCChannel2Content m15 : 10|2@1+ (1,0) [0|0] "" Vector__XXX
 SG_ PCS_dLogPhCChannel3Content m16 : 10|2@1+ (1,0) [0|0] "" Vector__XXX
 SG_ PCS_dLogPhCChannel4Content m17 : 10|2@1+ (1,0) [0|0] "" Vector__XXX
 SG_ PCS_chgPhCState m5 : 13|4@1+ (1,0) [0|0] "" Vector__XXX
 SG_ PCS_chgPHBInputVPeak10s m13 : 14|9@1+ (1,0) [0|0] "" Vector__XXX
 SG_ PCS_chgPhAIntBusV m0 : 14|9@1+ (1,0) [0|0] "" Vector__XXX
 SG_ PCS_chgPhAIntBusVMax10s m10 : 14|9@1+ (1,0) [0|0] "" Vector__XXX
 SG_ PCS_chgPhBIntBusV m1 : 14|9@1+ (1,0) [0|0] "" Vector__XXX
 SG_ PCS_chgPhBIntBusVMax10s m11 : 14|9@1+ (1,0) [0|0] "" Vector__XXX
 SG_ PCS_chgPhBNoFlowBucket m20 : 14|9@1+ (0.01,0) [0|0] "" Vector__XXX
 SG_ PCS_chgPhCIntBusV m2 : 14|9@1+ (1,0) [0|0] "" Vector__XXX
 SG_ PCS_chgPhCIntBusVMax10s m12 : 14|9@1+ (1,0) [0|0] "" Vector__XXX
 SG_ PCS_chgInputL2NVdc m21 : 16|10@1- (1,0) [0|0] "" Vector__XXX
 SG_ PCS_chgPhAMachineStatorCurrent m23 : 16|8@1- (0.2,0) [0|0] "" Vector__XXX
 SG_ PCS_dLogPhAChannel1Data m14 : 16|16@1- (0.02,0) [0|0] "" Vector__XXX
 SG_ PCS_dLogPhAChannel2Data m15 : 16|16@1- (0.02,0) [0|0] "" Vector__XXX
 SG_ PCS_dLogPhAChannel3Data m16 : 16|16@1- (0.02,0) [0|0] "" Vector__XXX
 SG_ PCS_dLogPhAChannel4Data m17 : 16|16@1- (0.02,0) [0|0] "" Vector__XXX
 SG_ PCS_dcdcCLAControllerOutput m7 : 16|10@1+ (0.001,0) [0|0] "" Vector__XXX
 SG_ PCS_dcdcPchgStartHvBusVolt m24 : 16|12@1+ (0.146484375,0) [0|0] "" Vector__XXX
 SG_ PCS_chgInputFrequencyL2N m4 : 17|12@1+ (0.01,40) [0|0] "" Vector__XXX
 SG_ PCS_chgInputL2NVrms m3 : 17|12@1+ (0.2,0) [0|0] "" Vector__XXX
 SG_ PCS_chgPhALastShutdownReason m5 : 17|5@1+ (1,0) [0|0] "" Vector__XXX
 SG_ PCS_1V5Max10s m9 : 19|11@1+ (0.001,0) [0|0] "" Vector__XXX
 SG_ PCS_dcdcCurrentLimit m6 : 20|12@1+ (0.1,0) [0|0] "" Vector__XXX
 SG_ PCS_dcdcShortTimeUs m8 : 21|16@1+ (0.00048828125,0) [0|0] "" Vector__XXX
 SG_ PCS_chgPhBLastShutdownReason m5 : 22|5@1+ (1,0) [0|0] "" Vector__XXX
 SG_ PCS_chgPHCInputVPeak10s m13 : 23|9@1+ (1,0) [0|0] "" Vector__XXX
 SG_ PCS_chgPhAIntBusVTarget m0 : 23|9@1+ (1,0) [0|0] "" Vector__XXX
 SG_ PCS_chgPhAPchgVoltDeltaMax10s m10 : 23|8@1+ (0.5,0) [0|0] "" Vector__XXX
 SG_ PCS_chgPhBIntBusVTarget m1 : 23|9@1+ (1,0) [0|0] "" Vector__XXX
 SG_ PCS_chgPhBPchgVoltDeltaMax10s m11 : 23|8@1+ (0.5,0) [0|0] "" Vector__XXX
 SG_ PCS_chgPhCIntBusVTarget m2 : 23|9@1+ (1,0) [0|0] "" Vector__XXX
 SG_ PCS_chgPhCNoFlowBucket m20 : 23|9@1+ (0.01,0) [0|0] "" Vector__XXX
 SG_ PCS_chgPhCPchgVoltDeltaMax10s m12 : 23|8@1+ (0.5,0) [0|0] "" Vector__XXX
 SG_ PCS_chgPhBMachineEnabled m23 : 24|1@1+ (1,0) [0|0] "" Vector__XXX
 SG_ PCS_dcdcIntervalMaxHvBusVolt m18 : 24|13@1+ (0.1,0) [0|0] "" Vector__XXX
 SG_ PCS_dcdcIntervalMinHvBusVolt m19 : 24|13@1+ (0.1,0) [0|0] "" Vector__XXX
 SG_ PCS_chgPhBMachineRotorFreqDroop m23 : 25|10@1- (0.01,0) [0|0] "" Vector__XXX
 SG_ PCS_chgInputL3NVdc m21 : 26|10@1- (1,0) [0|0] "" Vector__XXX
 SG_ PCS_dcdcTankVoltage m7 : 26|11@1- (1,0) [0|0] "" Vector__XXX
 SG_ PCS_chgPhCLastShutdownReason m5 : 27|5@1+ (1,0) [0|0] "" Vector__XXX
 SG_ PCS_dcdcHvBusEstimated_C_uF m24 : 28|10@1+ (7.820136852394917,0) [0|0] "" Vector__XXX
 SG_ PCS_chgInputFrequencyL3N m4 : 29|12@1+ (0.01,40) [0|0] "" Vector__XXX
 SG_ PCS_chgInputL3NVrms m3 : 29|12@1+ (0.2,0) [0|0] "" Vector__XXX
 SG_ PCS_chgPhALifetimekWh m10 : 31|24@1+ (0.01,0) [0|0] "" Vector__XXX
 SG_ PCS_chgPhBLifetimekWh m11 : 31|24@1+ (0.01,0) [0|0] "" Vector__XXX
 SG_ PCS_chgPhCLifetimekWh m12 : 31|24@1+ (0.01,0) [0|0] "" Vector__XXX
 SG_ PCS_1V2Min10s m9 : 32|11@1+ (0.001,0) [0|0] "" Vector__XXX
 SG_ PCS_chgCurrentSensorOutOfBandUs m20 : 32|10@1+ (0.01,0) [0|0] "" Vector__XXX
 SG_ PCS_chgPhAInputFreqWobbleCnt m13 : 32|7@1- (1,0) [0|0] "" Vector__XXX
 SG_ PCS_chgPhAOutputI m0 : 32|8@1+ (0.1,0) [0|0] "" Vector__XXX
 SG_ PCS_chgPhARetryCount m5 : 32|3@1+ (1,0) [0|0] "" Vector__XXX
 SG_ PCS_chgPhBOutputI m1 : 32|8@1+ (0.1,0) [0|0] "" Vector__XXX
 SG_ PCS_chgPhCOutputI m2 : 32|8@1+ (0.1,0) [0|0] "" Vector__XXX
 SG_ PCS_chgPwmEnableLineErrorCount m22 : 32|10@1+ (1,0) [0|0] "" Vector__XXX
 SG_ PCS_dLogPhBChannel1Data m14 : 32|16@1- (0.02,0) [0|0] "" Vector__XXX
 SG_ PCS_dLogPhBChannel2Data m15 : 32|16@1- (0.02,0) [0|0] "" Vector__XXX
 SG_ PCS_dLogPhBChannel3Data m16 : 32|16@1- (0.02,0) [0|0] "" Vector__XXX
 SG_ PCS_dLogPhBChannel4Data m17 : 32|16@1- (0.02,0) [0|0] "" Vector__XXX
 SG_ PCS_dcdcLvOutputCurrentTempLimit m6 : 32|12@1+ (0.1,0) [0|0] "" Vector__XXX
 SG_ PCS_processorDieIdWafer m25 : 32|8@1+ (1,0) [0|0] "" Vector__XXX
 SG_ PCS_chgPhBMachineStatorCurrent m23 : 35|8@1- (0.2,0) [0|0] "" Vector__XXX
 SG_ PCS_chgPhBRetryCount m5 : 35|3@1+ (1,0) [0|0] "" Vector__XXX
 SG_ PCS_chgInputL1L2Vdc m21 : 36|10@1- (1,0) [0|0] "" Vector__XXX
 SG_ PCS_dcdcHalfPeriodUs m8 : 37|16@1+ (0.00048828125,0) [0|0] "" Vector__XXX
 SG_ PCS_dcdcTankVoltageTarget m7 : 37|10@1+ (1,0) [0|0] "" Vector__XXX
 SG_ PCS_chgPhCRetryCount m5 : 38|3@1+ (1,0) [0|0] "" Vector__XXX
 SG_ PCS_dcdcHvBusEstimated_R_kOhm m24 : 38|10@1+ (0.04887585532746823,0) [0|0] "" Vector__XXX
 SG_ PCS_chgPhBInputFreqWobbleCnt m13 : 39|7@1- (1,0) [0|0] "" Vector__XXX
 SG_ PCS_chgPhAInputCurrentLimitReason m0 : 40|3@1+ (1,0) [0|0] "" Vector__XXX
 SG_ PCS_chgPhBInputCurrentLimitReason m1 : 40|3@1+ (1,0) [0|0] "" Vector__XXX
 SG_ PCS_chgPhCInputCurrentLimitReason m2 : 40|3@1+ (1,0) [0|0] "" Vector__XXX
 SG_ PCS_dcdcIntervalMaxLvBusVolt m18 : 40|12@1+ (0.01,0) [0|0] "" Vector__XXX
 SG_ PCS_dcdcIntervalMinLvBusVolt m19 : 40|12@1+ (0.01,0) [0|0] "" Vector__XXX
 SG_ PCS_processorDieIdX m25 : 40|12@1+ (1,0) [0|0] "" Vector__XXX
 SG_ PCS_chgInputL1L2Vrms m3 : 41|12@1+ (0.2,0) [0|0] "" Vector__XXX
 SG_ PCS_chgInternalPhaseConfig m4 : 41|4@1+ (1,0) [0|0] "" Vector__XXX
 SG_ PCS_chgRetryCount m5 : 41|3@1+ (1,0) [0|0] "" Vector__XXX
 SG_ PCS_chgAcpwHeartbeatState m20 : 42|3@1+ (1,0) [0|0] "" Vector__XXX
 SG_ PCS_dcdcPwmEnableLineErrorCount m22 : 42|10@1+ (1,0) [0|0] "" Vector__XXX
 SG_ PCS_1V2Max10s m9 : 43|11@1+ (0.001,0) [0|0] "" Vector__XXX
 SG_ PCS_chgPhCMachineEnabled m23 : 43|1@1+ (1,0) [0|0] "" Vector__XXX
 SG_ PCS_chgPhCMachineRotorFreqDroop m23 : 44|10@1- (0.01,0) [0|0] "" Vector__XXX
 SG_ PCS_chgPhManCurrentToDist m5 : 44|10@1+ (0.1,0) [0|0] "" Vector__XXX
 SG_ PCS_dcdcLvOutputCurrentFiltered m6 : 44|12@1+ (0.1,0) [0|0] "" Vector__XXX
 SG_ PCS_chgPhasesPriority m4 : 45|6@1+ (1,0) [0|0] "" Vector__XXX
 SG_ PCS_chgInputNGVdc m21 : 46|10@1- (1,0) [0|0] "" Vector__XXX
 SG_ PCS_chgPhCInputFreqWobbleCnt m13 : 46|7@1- (1,0) [0|0] "" Vector__XXX
 SG_ PCS_chgKwhLostByFreqDroop m20 : 48|8@1+ (0.1,0) [0|0] "" Vector__XXX
 SG_ PCS_dLogPhCChannel1Data m14 : 48|16@1- (0.02,0) [0|0] "" Vector__XXX
 SG_ PCS_dLogPhCChannel2Data m15 : 48|16@1- (0.02,0) [0|0] "" Vector__XXX
 SG_ PCS_dLogPhCChannel3Data m16 : 48|16@1- (0.02,0) [0|0] "" Vector__XXX
 SG_ PCS_dLogPhCChannel4Data m17 : 48|16@1- (0.02,0) [0|0] "" Vector__XXX
 SG_ PCS_dcdcClaCurrentFreq m7 : 48|12@1+ (0.09765625,0) [0|0] "" Vector__XXX
 SG_ PCS_chgOutputV m4 : 51|12@1+ (0.146484375,0) [0|0] "" Vector__XXX
 SG_ PCS_dcdcIntervalMaxLvOutputCurr m18 : 52|12@1+ (1,0) [0|0] "" Vector__XXX
 SG_ PCS_dcdcIntervalMinLvOutputCurr m19 : 52|12@1+ (1,0) [0|0] "" Vector__XXX
 SG_ PCS_processorDieIdY m25 : 52|12@1+ (1,0) [0|0] "" Vector__XXX
 SG_ PCS_chgInputNGVrms m3 : 53|9@1+ (1,0) [0|0] "" Vector__XXX
 SG_ PCS_chgLineVoltagePresenceDelay m13 : 53|11@1+ (20,0) [0|0] "" Vector__XXX
 SG_ PCS_dcdcLvBusVoltTargetWithOffset m8 : 53|11@1+ (0.01,0) [0|0] "" Vector__XXX
 SG_ PCS_5VNMax10s m9 : 54|10@1+ (0.01,0) [0|0] "" Vector__XXX
 SG_ PCS_chgL1NPllLocked m5 : 54|1@1+ (1,0) [0|0] "" Vector__XXX
 SG_ PCS_chgPhCMachineStatorCurrent m23 : 54|8@1- (0.2,0) [0|0] "" Vector__XXX
 SG_ PCS_chgL2NPllLocked m5 : 55|1@1+ (1,0) [0|0] "" Vector__XXX
 SG_ PCS_chgPhATransientRetryCount m10 : 55|9@1+ (0.1,0) [0|0] "" Vector__XXX
 SG_ PCS_chgPhBTransientRetryCount m11 : 55|9@1+ (0.1,0) [0|0] "" Vector__XXX
 SG_ PCS_chgPhCTransientRetryCount m12 : 55|9@1+ (0.1,0) [0|0] "" Vector__XXX
 SG_ PCS_chgL3NPllLocked m5 : 56|1@1+ (1,0) [0|0] "" Vector__XXX
 SG_ PCS_chgReqKwhLostByFreqDroop m20 : 56|8@1+ (0.1,0) [0|0] "" Vector__XXX
 SG_ PCS_numAlertsSet m22 : 56|7@1+ (1,0) [0|0] "" Vector__XXX
 SG_ PCS_chgL1L2PllLocked m5 : 57|1@1+ (1,0) [0|0] "" Vector__XXX
 SG_ PCS_chgNgPllLocked m5 : 58|1@1+ (1,0) [0|0] "" Vector__XXX
 SG_ PCS_chgPhManOptimalPhsToUse m5 : 59|2@1+ (1,0) [0|0] "" Vector__XXX
 SG_ PCS_chg5VL1Enable m5 : 61|1@1+ (1,0) [0|0] "" Vector__XXX

BO_ 711 CMPD_faultsAndExtras: 8 Vector__XXX
 SG_ CMPD_limitUnderVoltage : 0|1@1+ (1,0) [0|0] "" Vector__XXX
 SG_ CMPD_limitOverCurrentPhase : 1|1@1+ (1,0) [0|0] "" Vector__XXX
 SG_ CMPD_limitOverCurrentHVDC : 2|1@1+ (1,0) [0|0] "" Vector__XXX
 SG_ CMPD_VCFRONTCANTimeout : 8|1@1+ (1,0) [0|0] "" Vector__XXX
 SG_ CMPD_LVUnderVoltage : 9|1@1+ (1,0) [0|0] "" Vector__XXX
 SG_ CMPD_LVOverVoltage : 10|1@1+ (1,0) [0|0] "" Vector__XXX
 SG_ CMPD_HVOverVoltage : 11|1@1+ (1,0) [0|0] "" Vector__XXX
 SG_ CMPD_HVUnderVoltage : 12|1@1+ (1,0) [0|0] "" Vector__XXX
 SG_ CMPD_tempSnsFaultIPM1 : 13|1@1+ (1,0) [0|0] "" Vector__XXX
 SG_ CMPD_tempSnsFaultIPM2 : 14|1@1+ (1,0) [0|0] "" Vector__XXX
 SG_ CMPD_tempSnsFaultCPU : 15|1@1+ (1,0) [0|0] "" Vector__XXX
 SG_ CMPD_currentSnsError : 16|1@1+ (1,0) [0|0] "" Vector__XXX
 SG_ CMPD_selfTestFailCPU : 17|1@1+ (1,0) [0|0] "" Vector__XXX
 SG_ CMPD_internalPowerSupplyFault : 18|1@1+ (1,0) [0|0] "" Vector__XXX
 SG_ CMPD_inverterOpenCircuit : 19|1@1+ (1,0) [0|0] "" Vector__XXX
 SG_ CMPD_shortCircuit : 20|1@1+ (1,0) [0|0] "" Vector__XXX
 SG_ CMPD_warnOverTemperature : 21|1@1+ (1,0) [0|0] "" Vector__XXX
 SG_ CMPD_overTemperature : 22|1@1+ (1,0) [0|0] "" Vector__XXX
 SG_ CMPD_underTemperature : 23|1@1+ (1,0) [0|0] "" Vector__XXX
 SG_ CMPD_failedStart : 24|1@1+ (1,0) [0|0] "" Vector__XXX
 SG_ CMPD_failedStartRepeated : 25|1@1+ (1,0) [0|0] "" Vector__XXX
 SG_ CMPD_overCurrent : 26|1@1+ (1,0) [0|0] "" Vector__XXX
 SG_ CMPD_overloadStatus : 27|2@1+ (1,0) [0|0] "" Vector__XXX
 SG_ CMPD_overloadStartFaultDetection : 29|1@1+ (1,0) [0|0] "" Vector__XXX
 SG_ CMPD_overloadLossOfSync : 30|1@1+ (1,0) [0|0] "" Vector__XXX
 SG_ CMPD_overloadRestrictionCurrent : 31|1@1+ (1,0) [0|0] "" Vector__XXX
 SG_ CMPD_overloadDetectionOfSpeed : 32|1@1+ (1,0) [0|0] "" Vector__XXX
 SG_ CMPD_IGBTTemperature : 40|8@1+ (1,-40) [0|0] "" Vector__XXX
 SG_ CMPD_inverterTemperature : 48|8@1+ (1,-40) [0|0] "" Vector__XXX
 SG_ CMPD_inputLVVoltage : 56|8@1+ (0.1,0) [0|0] "" Vector__XXX

BO_ 721 VCFRONT_okToUseHighPower: 8 Vector__XXX
 SG_ VCFRONT_vcleftOkToUseHighPower : 0|1@1+ (1,0) [0|0] "" Vector__XXX
 SG_ VCFRONT_vcrightOkToUseHighPower : 1|1@1+ (1,0) [0|0] "" Vector__XXX
 SG_ VCFRONT_das1OkToUseHighPower : 2|1@1+ (1,0) [0|0] "" Vector__XXX
 SG_ VCFRONT_das2OkToUseHighPower : 3|1@1+ (1,0) [0|0] "" Vector__XXX
 SG_ VCFRONT_MCULogicOkToUseHighPower : 4|1@1+ (1,0) [0|0] "" Vector__XXX
 SG_ VCFRONT_MCUAudioOkToUseHighPower : 5|1@1+ (1,0) [0|0] "" Vector__XXX
 SG_ VCFRONT_cpOkToUseHighPower : 6|1@1+ (1,0) [0|0] "" Vector__XXX
 SG_ VCFRONT_premAudioOkToUseHiPower : 7|1@1+ (1,0) [0|0] "" Vector__XXX
 SG_ VCFRONT_tasOkToUseHighPower : 8|1@1+ (1,0) [0|0] "" Vector__XXX

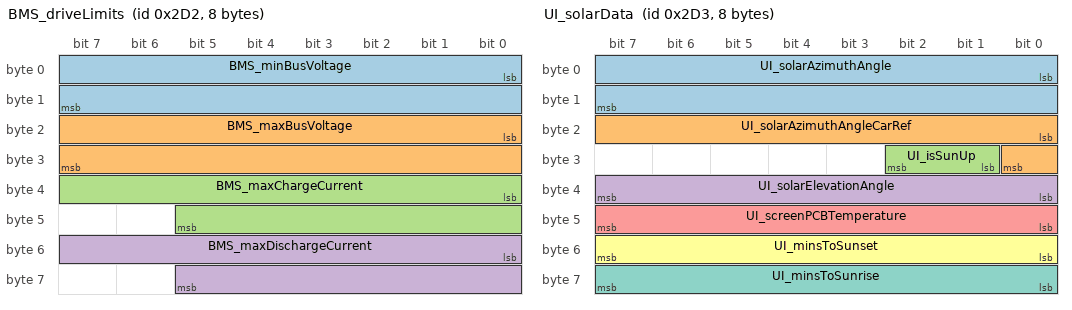
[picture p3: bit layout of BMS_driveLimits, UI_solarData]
BO_ 722 BMS_driveLimits: 8 Vector__XXX
 SG_ BMS_minBusVoltage : 0|16@1+ (0.02,0) [0|0] "" Vector__XXX
 SG_ BMS_maxBusVoltage : 16|16@1+ (0.02,0) [0|0] "" Vector__XXX
 SG_ BMS_maxChargeCurrent : 32|14@1+ (0.1,0) [0|0] "" Vector__XXX
 SG_ BMS_maxDischargeCurrent : 48|14@1+ (0.15,0) [0|0] "" Vector__XXX

BO_ 723 UI_solarData: 8 Vector__XXX
 SG_ UI_solarAzimuthAngle : 0|16@1- (1,0) [0|0] "" Vector__XXX
 SG_ UI_solarAzimuthAngleCarRef : 16|9@1- (1,0) [0|0] "" Vector__XXX
 SG_ UI_isSunUp : 25|2@1+ (1,0) [0|0] "" Vector__XXX
 SG_ UI_solarElevationAngle : 32|8@1- (1,0) [0|0] "" Vector__XXX
 SG_ UI_screenPCBTemperature : 40|8@1- (0.5,40) [0|0] "" Vector__XXX
 SG_ UI_minsToSunset : 48|8@1+ (10,0) [0|0] "" Vector__XXX
 SG_ UI_minsToSunrise : 56|8@1+ (10,0) [0|0] "" Vector__XXX

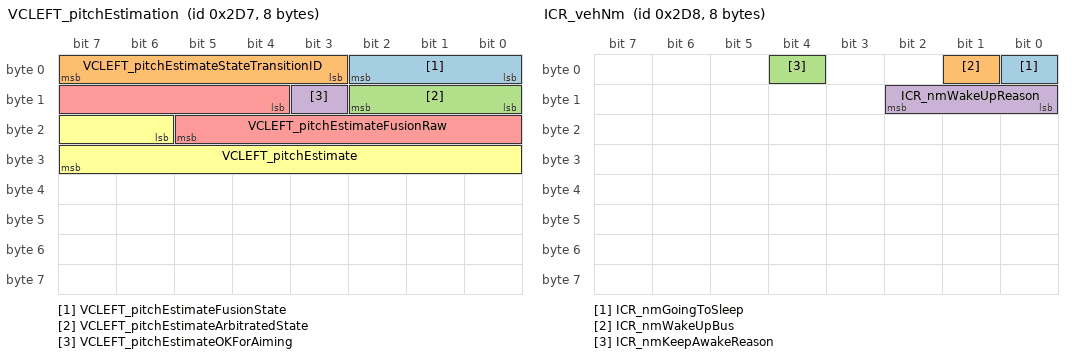
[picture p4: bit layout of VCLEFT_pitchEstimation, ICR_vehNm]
BO_ 727 VCLEFT_pitchEstimation: 8 Vector__XXX
 SG_ VCLEFT_pitchEstimateFusionState : 0|3@1+ (1,0) [0|0] "" Vector__XXX
 SG_ VCLEFT_pitchEstimateStateTransitionID : 3|5@1+ (1,0) [0|0] "" Vector__XXX
 SG_ VCLEFT_pitchEstimateArbitratedState : 8|3@1+ (1,0) [0|0] "" Vector__XXX
 SG_ VCLEFT_pitchEstimateOKForAiming : 11|1@1+ (1,0) [0|0] "" Vector__XXX
 SG_ VCLEFT_pitchEstimateFusionRaw : 12|10@1- (0.0002,0) [0|0] "" Vector__XXX
 SG_ VCLEFT_pitchEstimate : 22|10@1- (0.0002,0) [0|0] "" Vector__XXX

BO_ 728 ICR_vehNm: 8 Vector__XXX
 SG_ ICR_nmGoingToSleep : 0|1@1+ (1,0) [0|0] "" Vector__XXX
 SG_ ICR_nmWakeUpBus : 1|1@1+ (1,0) [0|0] "" Vector__XXX
 SG_ ICR_nmKeepAwakeReason : 4|1@1+ (1,0) [0|0] "" Vector__XXX
 SG_ ICR_nmWakeUpReason : 8|3@1+ (1,0) [0|0] "" Vector__XXX

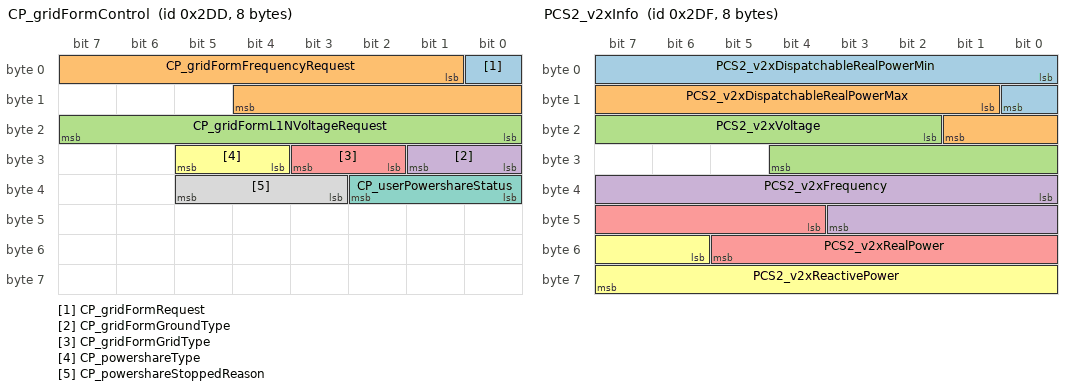
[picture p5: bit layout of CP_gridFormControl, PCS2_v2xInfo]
BO_ 733 CP_gridFormControl: 8 Vector__XXX
 SG_ CP_gridFormRequest : 0|1@1+ (1,0) [0|0] "" Vector__XXX
 SG_ CP_gridFormFrequencyRequest : 1|12@1+ (0.01,40) [0|0] "" Vector__XXX
 SG_ CP_gridFormL1NVoltageRequest : 16|8@1+ (1,40) [0|0] "" Vector__XXX
 SG_ CP_gridFormGroundType : 24|2@1+ (1,0) [0|0] "" Vector__XXX
 SG_ CP_gridFormGridType : 26|2@1+ (1,0) [0|0] "" Vector__XXX
 SG_ CP_powershareType : 28|2@1+ (1,0) [0|0] "" Vector__XXX
 SG_ CP_userPowershareStatus : 32|3@1+ (1,0) [0|0] "" Vector__XXX
 SG_ CP_powershareStoppedReason : 35|3@1+ (1,0) [0|0] "" Vector__XXX

BO_ 735 PCS2_v2xInfo: 8 Vector__XXX
 SG_ PCS2_v2xDispatchableRealPowerMin : 0|9@1- (0.05,-9.95) [0|0] "" Vector__XXX
 SG_ PCS2_v2xDispatchableRealPowerMax : 9|9@1+ (0.05,0) [0|0] "" Vector__XXX
 SG_ PCS2_v2xVoltage : 18|11@1+ (0.2,0) [0|0] "" Vector__XXX
 SG_ PCS2_v2xFrequency : 32|12@1+ (0.01,40) [0|0] "" Vector__XXX
 SG_ PCS2_v2xRealPower : 44|10@1- (0.05,0) [0|0] "" Vector__XXX
 SG_ PCS2_v2xReactivePower : 54|10@1- (0.05,0) [0|0] "" Vector__XXX

BO_ 737 VCFRONT_status: 8 Vector__XXX
 SG_ VCFRONT_statusIndex M : 0|3@1+ (1,0) [0|0] "" Vector__XXX
 SG_ VCFRONT_5VARailStable m3 : 3|1@1+ (1,0) [0|0] "" Vector__XXX
 SG_ VCFRONT_frunkLatchStatus m0 : 3|4@1+ (1,0) [0|0] "" Vector__XXX
 SG_ VCFRONT_iBoosterWakeLine m1 : 3|1@1+ (1,0) [0|0] "" Vector__XXX
 SG_ VCFRONT_5VBRailStable m3 : 4|1@1+ (1,0) [0|0] "" Vector__XXX
 SG_ VCFRONT_epasWakeLine m1 : 4|1@1+ (1,0) [0|0] "" Vector__XXX
 SG_ VCFRONT_12VARailStable m3 : 5|1@1+ (1,0) [0|0] "" Vector__XXX
 SG_ VCFRONT_UP_inDriveState m5 : 5|1@1+ (1,0) [0|0] "" Vector__XXX
 SG_ VCFRONT_iBoosterStateDBG m1 : 5|3@1+ (1,0) [0|0] "" Vector__XXX
 SG_ VCFRONT_12VBRailStable m3 : 6|1@1+ (1,0) [0|0] "" Vector__XXX
 SG_ VCFRONT_UP_UIDisplayOnForUser m5 : 6|1@1+ (1,0) [0|0] "" Vector__XXX
 SG_ VCFRONT_cabinCoolingCapacityLimited m4 : 6|1@1+ (1,0) [0|0] "" Vector__XXX
 SG_ VCFRONT_UP_steeringWheelButtonInteraction m5 : 7|1@1+ (1,0) [0|0] "" Vector__XXX
 SG_ VCFRONT_cabinHeatingCapacityLimited m4 : 7|1@1+ (1,0) [0|0] "" Vector__XXX
 SG_ VCFRONT_railAState m3 : 7|1@1+ (1,0) [0|0] "" Vector__XXX
 SG_ VCFRONT_UP_frontDriverDoorOpen m5 : 8|1@1+ (1,0) [0|0] "" Vector__XXX
 SG_ VCFRONT_compPowerSupportingHvac m4 : 8|11@1+ (10,0) [0|0] "" Vector__XXX
 SG_ VCFRONT_maxEvapHeatRejection m2 : 8|8@1+ (65,0) [0|0] "" Vector__XXX
 SG_ VCFRONT_railBState m3 : 8|1@1+ (1,0) [0|0] "" Vector__XXX
 SG_ VCFRONT_vehicleStatusDBG m1 : 8|5@1+ (1,0) [0|0] "" Vector__XXX
 SG_ VCFRONT_wiperSpeed m0 : 8|4@1+ (1,0) [0|0] "" Vector__XXX
 SG_ VCFRONT_ChargePumpVoltageStable m3 : 9|1@1+ (1,0) [0|0] "" Vector__XXX
 SG_ VCFRONT_UP_frontPassengerDoorOpen m5 : 9|1@1+ (1,0) [0|0] "" Vector__XXX
 SG_ VCFRONT_PEResetLineState m3 : 10|1@1+ (1,0) [0|0] "" Vector__XXX
 SG_ VCFRONT_UP_rearDriverDoorOpen m5 : 10|1@1+ (1,0) [0|0] "" Vector__XXX
 SG_ VCFRONT_HSDInitCompleteU13 m3 : 11|1@1+ (1,0) [0|0] "" Vector__XXX
 SG_ VCFRONT_UP_rearPassengerDoorOpen m5 : 11|1@1+ (1,0) [0|0] "" Vector__XXX
 SG_ VCFRONT_HSDInitCompleteU16 m3 : 12|1@1+ (1,0) [0|0] "" Vector__XXX
 SG_ VCFRONT_UP_trunkOpen m5 : 12|1@1+ (1,0) [0|0] "" Vector__XXX
 SG_ VCFRONT_wiperPosition m0 : 12|3@1+ (1,0) [0|0] "" Vector__XXX
 SG_ VCFRONT_UP_inTransportMode m5 : 13|1@1+ (1,0) [0|0] "" Vector__XXX
 SG_ VCFRONT_timeSpentSleeping m1 : 13|10@1+ (1,0) [0|0] "" Vector__XXX
 SG_ VCFRONT_UP_anyClosureIsOpen m5 : 14|1@1+ (1,0) [0|0] "" Vector__XXX
 SG_ VCFRONT_UP_driverPresent m5 : 15|1@1+ (1,0) [0|0] "" Vector__XXX
 SG_ VCFRONT_wiperBlocked m0 : 15|1@1+ (1,0) [0|0] "" Vector__XXX
 SG_ VCFRONT_UP_brakePressed m5 : 16|1@1+ (1,0) [0|0] "" Vector__XXX
 SG_ VCFRONT_minEvapHeatRejection m2 : 16|8@1+ (15,0) [0|0] "" Vector__XXX
 SG_ VCFRONT_vbatMonitorVoltage m3 : 16|12@1+ (0.005443676098,0) [0|0] "" Vector__XXX
 SG_ VCFRONT_wiperState m0 : 16|4@1+ (1,0) [0|0] "" Vector__XXX
 SG_ VCFRONT_UP_chargePortDoorOpen m5 : 17|1@1+ (1,0) [0|0] "" Vector__XXX
 SG_ VCFRONT_UP_UIChargePortDoorRequest m5 : 18|1@1+ (1,0) [0|0] "" Vector__XXX
 SG_ VCFRONT_UP_UIUserActivity m5 : 19|1@1+ (1,0) [0|0] "" Vector__XXX
 SG_ VCFRONT_compPowerSupportingPT m4 : 19|11@1+ (10,0) [0|0] "" Vector__XXX
 SG_ VCFRONT_UP_passengerPresent m5 : 20|1@1+ (1,0) [0|0] "" Vector__XXX
 SG_ VCFRONT_crashDetectedType m0 : 20|2@1+ (1,0) [0|0] "" Vector__XXX
 SG_ VCFRONT_UP_chargeStateTransitioned m5 : 21|1@1+ (1,0) [0|0] "" Vector__XXX
 SG_ VCFRONT_crashState m0 : 22|2@1+ (1,0) [0|0] "" Vector__XXX
 SG_ VCFRONT_crashUnlockOverrideSet m0 : 24|1@1+ (1,0) [0|0] "" Vector__XXX
 SG_ VCFRONT_freezeEvapITerm m2 : 24|1@1+ (1,0) [0|0] "" Vector__XXX
 SG_ VCFRONT_sleepCurrent m1 : 24|12@1+ (0.125,-511.875) [0|0] "" Vector__XXX
 SG_ VCFRONT_isEvapOperationAllowed m2 : 25|1@1+ (1,0) [0|0] "" Vector__XXX
 SG_ VCFRONT_chillerDemandActive m2 : 26|1@1+ (1,0) [0|0] "" Vector__XXX
 SG_ VCFRONT_compPerfRecoveryLimited m2 : 27|1@1+ (1,0) [0|0] "" Vector__XXX
 SG_ VCFRONT_AS8510Voltage m3 : 28|12@1+ (0.005443676098,0) [0|0] "" Vector__XXX
 SG_ VCFRONT_hvacModeNotAttainable m2 : 28|1@1+ (1,0) [0|0] "" Vector__XXX
 SG_ VCFRONT_hasLowRefrigerant m2 : 29|1@1+ (1,0) [0|0] "" Vector__XXX
 SG_ VCFRONT_isColdStartRunning m2 : 30|1@1+ (1,0) [0|0] "" Vector__XXX
 SG_ VCFRONT_maxHeatingPowerLeftCC m4 : 30|7@1+ (100,0) [0|0] "" Vector__XXX
 SG_ VCFRONT_isHeatPumpOilPurgeActive m2 : 31|1@1+ (1,0) [0|0] "" Vector__XXX
 SG_ VCFRONT_lastUserPresenceUpdateEpochTime m5 : 32|32@1+ (1,0) [0|0] "" Vector__XXX
 SG_ VCFRONT_pressureRefrigSuction m2 : 32|7@1+ (0.125,0) [0|0] "" Vector__XXX
 SG_ VCFRONT_wiperHealth m0 : 32|3@1+ (1,0) [0|0] "" Vector__XXX
 SG_ VCFRONT_wiperLINHealth m0 : 35|3@1+ (1,0) [0|0] "" Vector__XXX
 SG_ VCFRONT_hibernationState m1 : 36|3@1+ (1,0) [0|0] "" Vector__XXX
 SG_ VCFRONT_maxHeatingPowerRightCC m4 : 37|7@1+ (100,0) [0|0] "" Vector__XXX
 SG_ VCFRONT_frunkLatchCurrent m0 : 40|8@1- (0.15748031496062992,0) [0|0] "" Vector__XXX
 SG_ VCFRONT_pressureRefrigDischarge m2 : 40|9@1+ (0.08,0) [0|0] "" Vector__XXX
 SG_ VCFRONT_vbatProt m3 : 40|12@1+ (0.005443676098,0) [0|0] "" Vector__XXX
 SG_ VCFRONT_wiperECUType m1 : 40|2@1+ (1,0) [0|0] "" Vector__XXX
 SG_ VCFRONT_wiperHeaterState m1 : 42|3@1+ (1,0) [0|0] "" Vector__XXX
 SG_ VCFRONT_activeLouverOpenPos m4 : 44|7@1+ (1,0) [0|0] "" Vector__XXX
 SG_ VCFRONT_occupantCount m1 : 45|3@1+ (1,0) [0|0] "" Vector__XXX
 SG_ VCFRONT_closureEasterEggState m1 : 48|3@1+ (1,0) [0|0] "" Vector__XXX
 SG_ VCFRONT_frunkInteriorRelSwitch m0 : 48|1@1+ (1,0) [0|0] "" Vector__XXX
 SG_ VCFRONT_anyClosureOpen m0 : 49|1@1+ (1,0) [0|0] "" Vector__XXX
 SG_ VCFRONT_hvacPerfTestCommand m2 : 49|3@1+ (1,0) [0|0] "" Vector__XXX
 SG_ VCFRONT_anyDoorOpen m0 : 50|1@1+ (1,0) [0|0] "" Vector__XXX
 SG_ VCFRONT_activeLouverState m4 : 51|5@1+ (1,0) [0|0] "" Vector__XXX
 SG_ VCFRONT_espWakeLine m1 : 51|1@1+ (1,0) [0|0] "" Vector__XXX
 SG_ VCFRONT_hornOn m0 : 51|1@1+ (1,0) [0|0] "" Vector__XXX
 SG_ VCFRONT_allowEvapInLowAmbient m1 : 52|1@1+ (1,0) [0|0] "" Vector__XXX
 SG_ VCFRONT_coolantFillRoutineStatus m2 : 52|2@1+ (1,0) [0|0] "" Vector__XXX
 SG_ VCFRONT_logVerbosity m3 : 52|3@1+ (1,0) [0|0] "" Vector__XXX
 SG_ VCFRONT_radarHeaterState m0 : 52|3@1+ (1,0) [0|0] "" Vector__XXX
 SG_ VCFRONT_potentialRadiatorSteam m1 : 53|1@1+ (1,0) [0|0] "" Vector__XXX
 SG_ VCFRONT_potentialRadiatorSteamUI m1 : 54|1@1+ (1,0) [0|0] "" Vector__XXX
 SG_ VCFRONT_refrigFillRoutineStatus m2 : 54|2@1+ (1,0) [0|0] "" Vector__XXX
 SG_ VCFRONT_hvacReqOffForFasterCharge m1 : 55|1@1+ (1,0) [0|0] "" Vector__XXX
 SG_ VCFRONT_trunkExteriorWakeSwitch m0 : 55|1@1+ (1,0) [0|0] "" Vector__XXX
 SG_ VCFRONT_isCOP1Running m2 : 56|1@1+ (1,0) [0|0] "" Vector__XXX
 SG_ VCFRONT_limitedSplitTempDeltaEnforced m1 : 56|1@1+ (1,0) [0|0] "" Vector__XXX
 SG_ VCFRONT_windshieldCameraHeaterPower m4 : 56|6@1+ (2.5,0) [0|0] "" Vector__XXX
 SG_ VCFRONT_closeValvesRoutineStatus m2 : 57|2@1+ (1,0) [0|0] "" Vector__XXX
 SG_ VCFRONT_passengerBuckleStatus m0 : 57|1@1+ (1,0) [0|0] "" Vector__XXX
 SG_ VCFRONT_frunkLatchType m0 : 58|2@1+ (1,0) [0|0] "" Vector__XXX
 SG_ VCFRONT_thermalPerfTestRunning m2 : 59|1@1+ (1,0) [0|0] "" Vector__XXX
 SG_ VCFRONT_extendedHvacPerfTestCommand m2 : 60|4@1+ (1,0) [0|0] "" Vector__XXX
 SG_ VCFRONT_headlampLeftFanStatus m0 : 60|1@1+ (1,0) [0|0] "" Vector__XXX
 SG_ VCFRONT_headlampRightFanStatus m0 : 61|1@1+ (1,0) [0|0] "" Vector__XXX
 SG_ VCFRONT_frunkAccessPost m0 : 62|1@1+ (1,0) [0|0] "" Vector__XXX
 SG_ VCFRONT_isActiveHeatingBattery m0 : 63|1@1+ (1,0) [0|0] "" Vector__XXX

BO_ 738 VCLEFT_seatStatus2: 8 Vector__XXX
 SG_ VCLEFT_seatStatus2Index M : 0|4@1+ (1,0) [0|0] "" Vector__XXX
 SG_ VCLEFT_2RowSeatReclineActuatorCurrent m6 : 4|12@1- (0.01,0) [0|0] "" Vector__XXX
 SG_ VCLEFT_2RowSeatTrackActuatorCurrent m9 : 4|12@1- (0.01,0) [0|0] "" Vector__XXX
 SG_ VCLEFT_frontOccupancyVoltage m2 : 4|8@1+ (0.02,0) [0|0] "" Vector__XXX
 SG_ VCLEFT_frontSeatHeatCurrent m0 : 4|12@1+ (0.01,0) [0|0] "" Vector__XXX
 SG_ VCLEFT_frontSeatTrackBackrestSwitchVoltage m7 : 4|10@1+ (0.01,0) [0|0] "" Vector__XXX
 SG_ VCLEFT_rearCHeatCurrent m4 : 4|12@1+ (0.01,0) [0|0] "" Vector__XXX
 SG_ VCLEFT_rearLBackHeatCurrent m1 : 4|12@1+ (0.01,0) [0|0] "" Vector__XXX
 SG_ VCLEFT_rearLHeatCurrent m3 : 4|12@1+ (0.01,0) [0|0] "" Vector__XXX
 SG_ VCLEFT_rearRCushionHeatCurrent m5 : 4|12@1+ (0.01,0) [0|0] "" Vector__XXX
 SG_ VCLEFT_trunkFoldFlatLeftSwitchVoltage m8 : 4|10@1+ (0.004887585532746823,0) [0|0] "" Vector__XXX
 SG_ VCLEFT_frontBuckleVoltage m2 : 12|8@1+ (0.02,0) [0|0] "" Vector__XXX
 SG_ VCLEFT_frontSeatLumbarSwitchVoltage m7 : 14|10@1+ (0.01,0) [0|0] "" Vector__XXX
 SG_ VCLEFT_trunkFoldFlatRightSwitchVoltage m8 : 14|10@1+ (0.01,0) [0|0] "" Vector__XXX
 SG_ VCLEFT_2RowSeatReclineActuatorDuty m6 : 16|12@1- (0.1,0) [0|0] "" Vector__XXX
 SG_ VCLEFT_2RowSeatTrackActuatorDuty m9 : 16|12@1- (0.1,0) [0|0] "" Vector__XXX
 SG_ VCLEFT_frontSeatHeatDuty m0 : 16|8@1+ (1,0) [0|0] "" Vector__XXX
 SG_ VCLEFT_rearCHeatDuty m4 : 16|8@1+ (1,0) [0|0] "" Vector__XXX
 SG_ VCLEFT_rearLBackHeatDuty m1 : 16|8@1+ (1,0) [0|0] "" Vector__XXX
 SG_ VCLEFT_rearLHeatDuty m3 : 16|8@1+ (1,0) [0|0] "" Vector__XXX
 SG_ VCLEFT_rearRCushionHeatDuty m5 : 16|8@1+ (1,0) [0|0] "" Vector__XXX
 SG_ VCLEFT_rearLeftBuckleVoltage m2 : 20|8@1+ (0.02,0) [0|0] "" Vector__XXX
 SG_ VCLEFT_frontSeatHeatTmp m0 : 24|12@1- (0.05,0) [0|0] "" Vector__XXX
 SG_ VCLEFT_frontSeatLiftTiltSwitchVoltage m7 : 24|10@1+ (0.01,0) [0|0] "" Vector__XXX
 SG_ VCLEFT_rearCHeatTmp m4 : 24|12@1- (0.05,0) [0|0] "" Vector__XXX
 SG_ VCLEFT_rearLBackHeatTmp m1 : 24|12@1- (0.05,0) [0|0] "" Vector__XXX
 SG_ VCLEFT_rearLHeatTmp m3 : 24|12@1- (0.05,0) [0|0] "" Vector__XXX
 SG_ VCLEFT_rearRCushionHeatTmp m5 : 24|12@1- (0.05,0) [0|0] "" Vector__XXX
 SG_ VCLEFT_2RowSeatCenterActuatorCurrent m6 : 28|12@1- (0.01,0) [0|0] "" Vector__XXX
 SG_ VCLEFT_2RowSeatEasyEntryState m9 : 28|3@1+ (1,0) [0|0] "" Vector__XXX
 SG_ VCLEFT_rearLeftOccupancyVoltage m2 : 28|8@1+ (0.02,0) [0|0] "" Vector__XXX
 SG_ VCLEFT_2RowSeatTrackPositionSwitch m9 : 31|2@1+ (1,0) [0|0] "" Vector__XXX
 SG_ VCLEFT_2RowSeatReclineSwitchVoltage m7 : 34|10@1+ (0.01,0) [0|0] "" Vector__XXX
 SG_ VCLEFT_frontSeatHeatTmpTarget m0 : 36|8@1- (0.5,0) [0|0] "" Vector__XXX
 SG_ VCLEFT_rearCHeatTmpTarget m4 : 36|8@1- (0.5,0) [0|0] "" Vector__XXX
 SG_ VCLEFT_rearCenterOccupancyVoltage m2 : 36|8@1+ (0.02,0) [0|0] "" Vector__XXX
 SG_ VCLEFT_rearLBackHeatTmpTarget m1 : 36|8@1- (0.5,0) [0|0] "" Vector__XXX
 SG_ VCLEFT_rearLHeatTmpTarget m3 : 36|8@1- (0.5,0) [0|0] "" Vector__XXX
 SG_ VCLEFT_rearRCushionHeatTmpTarget m5 : 36|8@1- (0.5,0) [0|0] "" Vector__XXX
 SG_ VCLEFT_2RowSeatCenterActuatorDuty m6 : 40|12@1- (0.1,0) [0|0] "" Vector__XXX
 SG_ VCLEFT_2RowSeatEasyEntrySwitchVoltage m7 : 44|10@1+ (0.01,0) [0|0] "" Vector__XXX
 SG_ VCLEFT_frontSeatHeatInhibited m0 : 44|1@1+ (1,0) [0|0] "" Vector__XXX
 SG_ VCLEFT_rearCHeatInhibited m4 : 44|1@1+ (1,0) [0|0] "" Vector__XXX
 SG_ VCLEFT_rearLBackHeatInhibited m1 : 44|1@1+ (1,0) [0|0] "" Vector__XXX
 SG_ VCLEFT_rearLHeatInhibited m3 : 44|1@1+ (1,0) [0|0] "" Vector__XXX
 SG_ VCLEFT_rearRCushionHeatInhibited m5 : 44|1@1+ (1,0) [0|0] "" Vector__XXX
 SG_ VCLEFT_rearRightOccupancyVoltage m2 : 44|8@1+ (0.02,0) [0|0] "" Vector__XXX
 SG_ VCLEFT_frontSeatHeatPowered m0 : 45|1@1+ (1,0) [0|0] "" Vector__XXX
 SG_ VCLEFT_rearCHeatPowered m4 : 45|1@1+ (1,0) [0|0] "" Vector__XXX
 SG_ VCLEFT_rearLBackHeatPowered m1 : 45|1@1+ (1,0) [0|0] "" Vector__XXX
 SG_ VCLEFT_rearLHeatPowered m3 : 45|1@1+ (1,0) [0|0] "" Vector__XXX
 SG_ VCLEFT_rearRCushionHeatPowered m5 : 45|1@1+ (1,0) [0|0] "" Vector__XXX
 SG_ VCLEFT_rearCenterBuckleVoltage m2 : 52|8@1+ (0.02,0) [0|0] "" Vector__XXX
 SG_ VCLEFT_2RowSeatCenterSwitchVoltage m7 : 54|10@1+ (0.01,0) [0|0] "" Vector__XXX
 SG_ VC_AH_1RowLeftSeatHeatVentHealth m0 : 62|2@1+ (1,0) [0|0] "" Vector__XXX
 SG_ VC_AH_2RowCenterSeatHeatVentHealth m4 : 62|2@1+ (1,0) [0|0] "" Vector__XXX
 SG_ VC_AH_2RowLeftSeatHeatVentHealth m3 : 62|2@1+ (1,0) [0|0] "" Vector__XXX
 SG_ VC_AH_2RowRightSeatHeatVentHealth m5 : 62|2@1+ (1,0) [0|0] "" Vector__XXX

BO_ 739 VCRIGHT_seatStatus2: 8 Vector__XXX
 SG_ VCRIGHT_seatStatus2Index M : 0|4@1+ (1,0) [0|0] "" Vector__XXX
 SG_ VCRIGHT_2RowSeatReclineActuatorCurrent m6 : 4|12@1- (0.01,0) [0|0] "" Vector__XXX
 SG_ VCRIGHT_2RowSeatTrackActuatorCurrent m9 : 4|12@1- (0.01,0) [0|0] "" Vector__XXX
 SG_ VCRIGHT_3RowSeatLeftReclineSwitchVoltage m8 : 4|10@1+ (0.01,0) [0|0] "" Vector__XXX
 SG_ VCRIGHT_frontOccupancyVoltage m4 : 4|10@1+ (0.01,0) [0|0] "" Vector__XXX
 SG_ VCRIGHT_frontSeatHeatCurrent m0 : 4|12@1+ (0.01,0) [0|0] "" Vector__XXX
 SG_ VCRIGHT_frontSeatTrackBackrestSwitchVoltage m7 : 4|10@1+ (0.01,0) [0|0] "" Vector__XXX
 SG_ VCRIGHT_ocsIEEAirbAllwdSts m10 : 4|2@1+ (1,0) [0|0] "" Vector__XXX
 SG_ VCRIGHT_rearCSeatHeatCurrent m2 : 4|12@1+ (0.01,0) [0|0] "" Vector__XXX
 SG_ VCRIGHT_rearLSeatHeatCurrent m1 : 4|12@1+ (0.01,0) [0|0] "" Vector__XXX
 SG_ VCRIGHT_rearRSeatHeatCurrent m3 : 4|12@1+ (0.01,0) [0|0] "" Vector__XXX
 SG_ VCRIGHT_ocsIEEEcuFailr m10 : 6|1@1+ (1,0) [0|0] "" Vector__XXX
 SG_ VCRIGHT_ocsIEEMIA m10 : 7|1@1+ (1,0) [0|0] "" Vector__XXX
 SG_ VCRIGHT_ocsIEEFltResp1 m10 : 8|1@1+ (1,0) [0|0] "" Vector__XXX
 SG_ VCRIGHT_ocsIEEFltResp2 m10 : 9|1@1+ (1,0) [0|0] "" Vector__XXX
 SG_ VCRIGHT_ocsIEEFltResp3 m10 : 10|1@1+ (1,0) [0|0] "" Vector__XXX
 SG_ VCRIGHT_ocsIEEFltResp4 m10 : 11|1@1+ (1,0) [0|0] "" Vector__XXX
 SG_ VCRIGHT_ocsIEEFltResp5 m10 : 12|1@1+ (1,0) [0|0] "" Vector__XXX
 SG_ VCRIGHT_ocsIEEFltResp6 m10 : 13|1@1+ (1,0) [0|0] "" Vector__XXX
 SG_ VCRIGHT_3RowSeatRightReclineSwitchVoltage m8 : 14|10@1+ (0.01,0) [0|0] "" Vector__XXX
 SG_ VCRIGHT_frontBuckleVoltage m4 : 14|10@1+ (0.01,0) [0|0] "" Vector__XXX
 SG_ VCRIGHT_frontSeatLumbarSwitchVoltage m7 : 14|10@1+ (0.01,0) [0|0] "" Vector__XXX
 SG_ VCRIGHT_ocsIEEFltResp7 m10 : 14|1@1+ (1,0) [0|0] "" Vector__XXX
 SG_ VCRIGHT_ocsIEEFltResp8 m10 : 15|1@1+ (1,0) [0|0] "" Vector__XXX
 SG_ VCRIGHT_2RowSeatReclineActuatorDuty m6 : 16|12@1- (0.1,0) [0|0] "" Vector__XXX
 SG_ VCRIGHT_2RowSeatTrackActuatorDuty m9 : 16|12@1- (0.1,0) [0|0] "" Vector__XXX
 SG_ VCRIGHT_frontSeatHeatDuty m0 : 16|8@1+ (1,0) [0|0] "" Vector__XXX
 SG_ VCRIGHT_ocsIEEReqOfPassSeatCal m10 : 16|1@1+ (1,0) [0|0] "" Vector__XXX
 SG_ VCRIGHT_rearCSeatHeatDuty m2 : 16|8@1+ (1,0) [0|0] "" Vector__XXX
 SG_ VCRIGHT_rearLSeatHeatDuty m1 : 16|8@1+ (1,0) [0|0] "" Vector__XXX
 SG_ VCRIGHT_rearRSeatHeatDuty m3 : 16|8@1+ (1,0) [0|0] "" Vector__XXX
 SG_ VCRIGHT_ocsIEEReqOfClrOfFlt m10 : 17|1@1+ (1,0) [0|0] "" Vector__XXX
 SG_ VCRIGHT_ocsIEESnsrPassSeatCalRespSts m10 : 18|2@1+ (1,0) [0|0] "" Vector__XXX
 SG_ VCRIGHT_ocsIEEPowerCurrent m10 : 20|12@1+ (0.001,0) [0|0] "" Vector__XXX
 SG_ VCRIGHT_frontSeatHeatTmp m0 : 24|12@1- (0.05,0) [0|0] "" Vector__XXX
 SG_ VCRIGHT_frontSeatLiftTiltSwitchVoltage m7 : 24|10@1+ (0.01,0) [0|0] "" Vector__XXX
 SG_ VCRIGHT_rearCSeatHeatTmp m2 : 24|12@1- (0.05,0) [0|0] "" Vector__XXX
 SG_ VCRIGHT_rearCenterBuckleVoltage m4 : 24|10@1+ (0.01,0) [0|0] "" Vector__XXX
 SG_ VCRIGHT_rearLSeatHeatTmp m1 : 24|12@1- (0.05,0) [0|0] "" Vector__XXX
 SG_ VCRIGHT_rearRSeatHeatTmp m3 : 24|12@1- (0.05,0) [0|0] "" Vector__XXX
 SG_ VCRIGHT_2RowSeatEasyEntryState m9 : 28|3@1+ (1,0) [0|0] "" Vector__XXX
 SG_ VCRIGHT_3RUSBPortsCurrentAvg m6 : 28|8@1+ (0.01,0) [0|0] "" Vector__XXX
 SG_ VCRIGHT_2RowSeatTrackPositionSwitch m9 : 31|2@1+ (1,0) [0|0] "" Vector__XXX
 SG_ VCRIGHT_ocsIEEState m10 : 32|3@1+ (1,0) [0|0] "" Vector__XXX
 SG_ VCRIGHT_2RowSeatReclineSwitchVoltage m7 : 34|10@1+ (0.01,0) [0|0] "" Vector__XXX
 SG_ VCRIGHT_rearRightBuckleVoltage m4 : 34|10@1+ (0.01,0) [0|0] "" Vector__XXX
 SG_ VCRIGHT_frontSeatHeatTmpTarget m0 : 36|8@1- (0.5,0) [0|0] "" Vector__XXX
 SG_ VCRIGHT_rearCSeatHeatTmpTarget m2 : 36|8@1- (0.5,0) [0|0] "" Vector__XXX
 SG_ VCRIGHT_rearLSeatHeatTmpTarget m1 : 36|8@1- (0.5,0) [0|0] "" Vector__XXX
 SG_ VCRIGHT_rearRSeatHeatTmpTarget m3 : 36|8@1- (0.5,0) [0|0] "" Vector__XXX
 SG_ VCRIGHT_2RowSeatEasyEntrySwitchVoltage m7 : 44|10@1+ (0.01,0) [0|0] "" Vector__XXX
 SG_ VCRIGHT_frontSeatHeatInhibited m0 : 44|1@1+ (1,0) [0|0] "" Vector__XXX
 SG_ VCRIGHT_rearCSeatHeatInhibited m2 : 44|1@1+ (1,0) [0|0] "" Vector__XXX
 SG_ VCRIGHT_rearLSeatHeatInhibited m1 : 44|1@1+ (1,0) [0|0] "" Vector__XXX
 SG_ VCRIGHT_rearRSeatHeatInhibited m3 : 44|1@1+ (1,0) [0|0] "" Vector__XXX
 SG_ VCRIGHT_frontSeatHeatPowered m0 : 45|1@1+ (1,0) [0|0] "" Vector__XXX
 SG_ VCRIGHT_rearCSeatHeatPowered m2 : 45|1@1+ (1,0) [0|0] "" Vector__XXX
 SG_ VCRIGHT_rearLSeatHeatPowered m1 : 45|1@1+ (1,0) [0|0] "" Vector__XXX
 SG_ VCRIGHT_rearRSeatHeatPowered m3 : 45|1@1+ (1,0) [0|0] "" Vector__XXX
 SG_ VCRIGHT_occupantClassificationHoldState m4 : 46|2@1+ (1,0) [0|0] "" Vector__XXX
 SG_ VC_AH_1RowRightSeatHeatVentHealth m0 : 54|2@1+ (1,0) [0|0] "" Vector__XXX

BO_ 740 PCS2_logging: 8 Vector__XXX
 SG_ PCS2_logMessageSelect M : 0|8@1+ (1,0) [0|0] "" Vector__XXX
 SG_ PCS2_10V0RailSense m24 : 8|12@1+ (0.01,0) [0|0] "" Vector__XXX
 SG_ PCS2_13V5RailSense m29 : 8|12@1+ (0.01,0) [0|0] "" Vector__XXX
 SG_ PCS2_18V0RailSense m16 : 8|12@1+ (0.01,0) [0|0] "" Vector__XXX
 SG_ PCS2_1V6RailSense m26 : 8|12@1+ (0.01,0) [0|0] "" Vector__XXX
 SG_ PCS2_2V5Ref_V m30 : 8|12@1+ (0.01,0) [0|0] "" Vector__XXX
 SG_ PCS2_48V0RailSense m27 : 8|13@1+ (0.01,0) [0|0] "" Vector__XXX
 SG_ PCS2_48V0_18V0_CurrentSense m28 : 8|13@1- (0.01,0) [0|0] "" Vector__XXX
 SG_ PCS2_4V5RailSense m25 : 8|12@1+ (0.01,0) [0|0] "" Vector__XXX
 SG_ PCS2_FC_VSense m31 : 8|12@1- (1,0) [0|0] "" Vector__XXX
 SG_ PCS2_L1NAvailableForCharging m140 : 8|1@1+ (1,0) [0|0] "" Vector__XXX
 SG_ PCS2_acChargeLifetimekVAh m151 : 8|24@1+ (0.01,0) [0|0] "" Vector__XXX
 SG_ PCS2_acFrequencyL1L2 m133 : 8|13@1+ (0.01,0) [0|0] "" Vector__XXX
 SG_ PCS2_acFrequencyL1N m132 : 8|13@1+ (0.01,0) [0|0] "" Vector__XXX
 SG_ PCS2_acL1Arms m130 : 8|12@1+ (0.1,0) [0|0] "" Vector__XXX
 SG_ PCS2_acL1ChassisVrms m138 : 8|9@1+ (1,0) [0|0] "" Vector__XXX
 SG_ PCS2_acL1ContinuousCurrentLimit m149 : 8|10@1+ (0.1,0) [0|0] "" Vector__XXX
 SG_ PCS2_acL1CurrentLimitI2T m148 : 8|9@1+ (1,0) [0|0] "" Vector__XXX
 SG_ PCS2_acL1GeneratedHeatI2TCpLimit m159 : 8|10@1+ (0.1,0) [0|0] "" Vector__XXX
 SG_ PCS2_acL1GeneratedHeatI2THwLimit m150 : 8|10@1+ (0.1,0) [0|0] "" Vector__XXX
 SG_ PCS2_acL1L2Vrms m129 : 8|10@1+ (0.5,0) [0|0] "" Vector__XXX
 SG_ PCS2_acL1NVrms m128 : 8|10@1+ (0.5,0) [0|0] "" Vector__XXX
 SG_ PCS2_acL1TransientCurrentLimit m147 : 8|10@1+ (0.1,0) [0|0] "" Vector__XXX
 SG_ PCS2_acL2NPreRelayVrms m157 : 8|10@1+ (0.5,0) [0|0] "" Vector__XXX
 SG_ PCS2_aggregatedChargingCurrentLimit m139 : 8|10@1+ (0.1,0) [0|0] "" Vector__XXX
 SG_ PCS2_cabinAndBedL1L2LifetimekVAh m153 : 8|24@1+ (0.01,0) [0|0] "" Vector__XXX
 SG_ PCS2_cabinOnlyL2L3LifetimekVAh m152 : 8|24@1+ (0.01,0) [0|0] "" Vector__XXX
 SG_ PCS2_chgMainStateMachineState m135 : 8|4@1+ (1,0) [0|0] "" Vector__XXX
 SG_ PCS2_cpu0IsrUtilizationPercentageMax10s m23 : 8|8@1+ (1,0) [0|0] "" Vector__XXX
 SG_ PCS2_cpu1IsrUtilizationPercentageMax10s m95 : 8|8@1+ (1,0) [0|0] "" Vector__XXX
 SG_ PCS2_cpu2IsrUtilizationPercentageMax10s m158 : 8|8@1+ (1,0) [0|0] "" Vector__XXX
 SG_ PCS2_cpu3IsrUtilizationPercentageMax10s m206 : 8|8@1+ (1,0) [0|0] "" Vector__XXX
 SG_ PCS2_cycloAC_L1L2PeakV m160 : 8|11@1+ (0.5,0) [0|0] "" Vector__XXX
 SG_ PCS2_cycloAC_L1PeakCurrent m192 : 8|9@1+ (1,0) [0|0] "" Vector__XXX
 SG_ PCS2_cycloAC_chassisNPeakV m136 : 8|11@1+ (0.5,0) [0|0] "" Vector__XXX
 SG_ PCS2_cycloACmdSwitchingFreq_max_1s m156 : 8|14@1+ (0.1,150) [0|0] "" Vector__XXX
 SG_ PCS2_cycloASurgeCombinedDeratingFactor m143 : 8|7@1+ (0.01,0) [0|0] "" Vector__XXX
 SG_ PCS2_cycloATankLeakFreq m137 : 8|12@1+ (0.1,0) [0|0] "" Vector__XXX
 SG_ PCS2_cycloA_L_tank m142 : 8|11@1+ (0.1,0) [0|0] "" Vector__XXX
 SG_ PCS2_cycloA_tank_zcd_event_pu_max_1s m155 : 8|9@1- (0.01,0) [0|0] "" Vector__XXX
 SG_ PCS2_cycloBCmdSwitchingFreq_max_1s m203 : 8|14@1+ (0.1,150) [0|0] "" Vector__XXX
 SG_ PCS2_cycloBSurgeCombinedDeratingFactor m195 : 8|7@1+ (0.01,0) [0|0] "" Vector__XXX
 SG_ PCS2_cycloBTankLeakFreq m193 : 8|12@1+ (0.1,0) [0|0] "" Vector__XXX
 SG_ PCS2_cycloB_L_tank m194 : 8|11@1+ (0.1,0) [0|0] "" Vector__XXX
 SG_ PCS2_cycloB_tank_zcd_event_pu_max_1s m202 : 8|9@1- (0.01,0) [0|0] "" Vector__XXX
 SG_ PCS2_cyclo_A_hv_device_temp m144 : 8|11@1+ (0.1,0) [0|0] "" Vector__XXX
 SG_ PCS2_cyclo_A_hv_device_temp_max m145 : 8|11@1+ (0.1,0) [0|0] "" Vector__XXX
 SG_ PCS2_cyclo_A_i_tank_loss m146 : 8|17@1+ (1000000000000,0) [0|0] "" Vector__XXX
 SG_ PCS2_cyclo_B_hv_device_temp m196 : 8|11@1+ (0.1,0) [0|0] "" Vector__XXX
 SG_ PCS2_cyclo_B_hv_device_temp_max m197 : 8|11@1+ (0.1,0) [0|0] "" Vector__XXX
 SG_ PCS2_cyclo_B_i_tank_loss m198 : 8|17@1+ (1000000000000,0) [0|0] "" Vector__XXX
 SG_ PCS2_dcOffsetL1NVoltage m204 : 8|9@1- (4,0) [0|0] "" Vector__XXX
 SG_ PCS2_dcOffsetL2NPreRelayVoltage m205 : 8|9@1- (4,0) [0|0] "" Vector__XXX
 SG_ PCS2_dcacA_ac1Temp m86 : 8|11@1- (0.15,70.05) [0|0] "" Vector__XXX
 SG_ PCS2_dcacA_ac1TempMax_10s m91 : 8|11@1- (0.15,70.05) [0|0] "" Vector__XXX
 SG_ PCS2_dcacA_ac1TempMin_10s m90 : 8|11@1- (0.15,70.05) [0|0] "" Vector__XXX
 SG_ PCS2_dcacA_transformerTemp m89 : 8|11@1- (0.15,70.05) [0|0] "" Vector__XXX
 SG_ PCS2_dcacA_transformerTempMax_10s m82 : 8|11@1- (0.15,70.05) [0|0] "" Vector__XXX
 SG_ PCS2_dcacA_transformerTempMin_10s m94 : 8|11@1- (0.15,70.05) [0|0] "" Vector__XXX
 SG_ PCS2_dcacB_ac1Temp m87 : 8|11@1- (0.15,70.05) [0|0] "" Vector__XXX
 SG_ PCS2_dcacB_ac1TempMax_10s m93 : 8|11@1- (0.15,70.05) [0|0] "" Vector__XXX
 SG_ PCS2_dcacB_ac1TempMin_10s m92 : 8|11@1- (0.15,70.05) [0|0] "" Vector__XXX
 SG_ PCS2_dcacHvBusVoltage m134 : 8|14@1+ (0.1,0) [0|0] "" Vector__XXX
 SG_ PCS2_dcdcACmdSwitchingFreq_max_1s m21 : 8|14@1+ (0.1,150) [0|0] "" Vector__XXX
 SG_ PCS2_dcdcAHalfBusTopVoltageMin_10s m7 : 8|10@1+ (1,0) [0|0] "" Vector__XXX
 SG_ PCS2_dcdcAHvCurrentCommand m2 : 8|13@1- (0.01,0) [0|0] "" Vector__XXX
 SG_ PCS2_dcdcAHvVoltage m0 : 8|14@1+ (0.1,0) [0|0] "" Vector__XXX
 SG_ PCS2_dcdcAHvVoltageMin_10s m5 : 8|14@1+ (0.1,0) [0|0] "" Vector__XXX
 SG_ PCS2_dcdcALifetimekWh m10 : 8|24@1+ (0.01,0) [0|0] "" Vector__XXX
 SG_ PCS2_dcdcALvMosfetModelTemp m11 : 8|9@1- (1,106) [0|0] "" Vector__XXX
 SG_ PCS2_dcdcALvVoltageTarget m9 : 8|13@1+ (0.01,0) [0|0] "" Vector__XXX
 SG_ PCS2_dcdcAPWMBlockedByArbitration m19 : 8|1@1+ (1,0) [0|0] "" Vector__XXX
 SG_ PCS2_dcdcAStageManagerRetryCount m17 : 8|3@1+ (1,0) [0|0] "" Vector__XXX
 SG_ PCS2_dcdcATankLeakFreq m8 : 8|12@1+ (0.1,0) [0|0] "" Vector__XXX
 SG_ PCS2_dcdcA_L_tank m6 : 8|11@1+ (0.1,0) [0|0] "" Vector__XXX
 SG_ PCS2_dcdcA_lv1Temp m98 : 8|11@1- (0.15,70.05) [0|0] "" Vector__XXX
 SG_ PCS2_dcdcA_lv2Temp m88 : 8|11@1- (0.15,70.05) [0|0] "" Vector__XXX
 SG_ PCS2_dcdcA_lv2TempMax_10s m80 : 8|11@1- (0.15,70.05) [0|0] "" Vector__XXX
 SG_ PCS2_dcdcA_lv2TempMin_10s m79 : 8|11@1- (0.15,70.05) [0|0] "" Vector__XXX
 SG_ PCS2_dcdcA_tank_zcd_event_pu_max_1s m20 : 8|9@1- (0.01,0) [0|0] "" Vector__XXX
 SG_ PCS2_dcdcBCmdSwitchingFreq_max_1s m78 : 8|14@1+ (0.1,150) [0|0] "" Vector__XXX
 SG_ PCS2_dcdcBHalfBusTopVoltageMin_10s m68 : 8|10@1+ (1,0) [0|0] "" Vector__XXX
 SG_ PCS2_dcdcBHvCurrentCommand m65 : 8|13@1- (0.01,0) [0|0] "" Vector__XXX
 SG_ PCS2_dcdcBHvMosfetModelTemp m96 : 8|9@1- (1,106) [0|0] "" Vector__XXX
 SG_ PCS2_dcdcBHvVoltage m64 : 8|14@1+ (0.1,0) [0|0] "" Vector__XXX
 SG_ PCS2_dcdcBHvVoltageMin_10s m66 : 8|14@1+ (0.1,0) [0|0] "" Vector__XXX
 SG_ PCS2_dcdcBLifetimekWh m71 : 8|24@1+ (0.01,0) [0|0] "" Vector__XXX
 SG_ PCS2_dcdcBLvMosfetModelTemp m72 : 8|9@1- (1,106) [0|0] "" Vector__XXX
 SG_ PCS2_dcdcBLvVoltageTarget m70 : 8|13@1+ (0.01,0) [0|0] "" Vector__XXX
 SG_ PCS2_dcdcBPWMBlockedByArbitration m76 : 8|1@1+ (1,0) [0|0] "" Vector__XXX
 SG_ PCS2_dcdcBStageManagerRetryCount m74 : 8|3@1+ (1,0) [0|0] "" Vector__XXX
 SG_ PCS2_dcdcBTankLeakFreq m69 : 8|12@1+ (0.1,0) [0|0] "" Vector__XXX
 SG_ PCS2_dcdcB_L_tank m67 : 8|11@1+ (0.1,0) [0|0] "" Vector__XXX
 SG_ PCS2_dcdcB_tank_zcd_event_pu_max_1s m77 : 8|9@1- (0.01,0) [0|0] "" Vector__XXX
 SG_ PCS2_dcdcGdpsHealthCheckStatus m22 : 8|2@1+ (1,0) [0|0] "" Vector__XXX
 SG_ PCS2_dcdcLvBusVoltage m83 : 8|13@1+ (0.01,0) [0|0] "" Vector__XXX
 SG_ PCS2_dcdcLvBusVoltageFiltered m3 : 8|13@1+ (0.01,0) [0|0] "" Vector__XXX
 SG_ PCS2_dcdcUsingInternalDefLvTarget m1 : 8|1@1+ (1,0) [0|0] "" Vector__XXX
 SG_ PCS2_dcdc_hvTemp m81 : 8|11@1- (0.15,70.05) [0|0] "" Vector__XXX
 SG_ PCS2_detectedInternalPhaseConfig m131 : 8|3@1+ (1,0) [0|0] "" Vector__XXX
 SG_ PCS2_hvBusEstimatedCapacitance m73 : 8|10@1+ (10,0) [0|0] "" Vector__XXX
 SG_ PCS2_hwZcdFaultRateMax60s m97 : 8|16@1+ (0.001,0) [0|0] "" Vector__XXX
 SG_ PCS2_ipcCpu0ToCpu1MaxSuccessiveLockGrabFails m18 : 8|3@1+ (1,0) [0|0] "" Vector__XXX
 SG_ PCS2_ipcCpu1ToCpu0MaxSuccessiveLockGrabFails m75 : 8|3@1+ (1,0) [0|0] "" Vector__XXX
 SG_ PCS2_ipcCpu2ToCpu0MaxSuccessiveLockGrabFails m154 : 8|3@1+ (1,0) [0|0] "" Vector__XXX
 SG_ PCS2_ipcCpu3ToCpu0MaxSuccessiveLockGrabFails m200 : 8|3@1+ (1,0) [0|0] "" Vector__XXX
 SG_ PCS2_lite_BoostCurrentPeak m38 : 8|10@1+ (0.05,0) [0|0] "" Vector__XXX
 SG_ PCS2_lite_ambientTemp m84 : 8|11@1- (0.15,70.05) [0|0] "" Vector__XXX
 SG_ PCS2_lite_boost_duty m32 : 8|7@1+ (0.01,0) [0|0] "" Vector__XXX
 SG_ PCS2_lite_dcdc_LV_A_Temp m85 : 8|11@1- (0.15,70.05) [0|0] "" Vector__XXX
 SG_ PCS2_lite_lvBiasRailSense m33 : 8|12@1+ (0.01,0) [0|0] "" Vector__XXX
 SG_ PCS2_llcControllerFreqMHz m4 : 8|8@1+ (0.01,0) [0|0] "" Vector__XXX
 SG_ PCS2_mfgFuncTestCalIterativeState m14 : 8|4@1+ (1,0) [0|0] "" Vector__XXX
 SG_ PCS2_mfgFuncTestIOXWriteFailed m15 : 8|10@1+ (1,0) [0|0] "" Vector__XXX
 SG_ PCS2_mfgFuncTestState m12 : 8|4@1+ (1,0) [0|0] "" Vector__XXX
 SG_ PCS2_mfg_can_injection_msg_index m13 : 8|3@1+ (1,0) [0|0] "" Vector__XXX
 SG_ PCS2_microgridHeartbeatDetected m201 : 8|1@1+ (1,0) [0|0] "" Vector__XXX
 SG_ PCS2_phase_diff_L1N_L2N m141 : 8|8@1+ (1,0) [0|0] "" Vector__XXX
 SG_ PCS2_vcrEfuseState m34 : 8|1@1+ (1,0) [0|0] "" Vector__XXX
 SG_ PCS2_L2NAvailableForCharging m140 : 9|1@1+ (1,0) [0|0] "" Vector__XXX
 SG_ PCS2_dcdcAStateMachineState m1 : 9|3@1+ (1,0) [0|0] "" Vector__XXX
 SG_ PCS2_hvcEfuseState m34 : 9|1@1+ (1,0) [0|0] "" Vector__XXX
 SG_ PCS2_L3NAvailableForCharging m140 : 10|1@1+ (1,0) [0|0] "" Vector__XXX
 SG_ PCS2_cutloopStatus m34 : 10|2@1+ (1,0) [0|0] "" Vector__XXX
 SG_ PCS2_cycloAGdpsHealthCheckStatus m22 : 10|2@1+ (1,0) [0|0] "" Vector__XXX
 SG_ PCS2_L1L2AvailableForCharging m140 : 11|1@1+ (1,0) [0|0] "" Vector__XXX
 SG_ PCS2_dcdcASmLvRegulationRetryCnt m17 : 11|4@1+ (1,0) [0|0] "" Vector__XXX
 SG_ PCS2_dcdcBSmLvRegulationRetryCnt m74 : 11|4@1+ (1,0) [0|0] "" Vector__XXX
 SG_ PCS2_ipcCpu0ToCpu2MaxSuccessiveLockGrabFails m18 : 11|3@1+ (1,0) [0|0] "" Vector__XXX
 SG_ PCS2_ipcCpu1ToCpu2MaxSuccessiveLockGrabFails m75 : 11|3@1+ (1,0) [0|0] "" Vector__XXX
 SG_ PCS2_ipcCpu2ToCpu1MaxSuccessiveLockGrabFails m154 : 11|3@1+ (1,0) [0|0] "" Vector__XXX
 SG_ PCS2_ipcCpu3ToCpu1MaxSuccessiveLockGrabFails m200 : 11|3@1+ (1,0) [0|0] "" Vector__XXX
 SG_ PCS2_latchedInternalPhaseConfig m131 : 11|3@1+ (1,0) [0|0] "" Vector__XXX
 SG_ PCS2_mfgFuncTestImpedanceMeasEnable m13 : 11|1@1+ (1,0) [0|0] "" Vector__XXX
 SG_ PCS2_L1L3AvailableForCharging m140 : 12|1@1+ (1,0) [0|0] "" Vector__XXX
 SG_ PCS2_cycloBGdpsHealthCheckStatus m22 : 12|2@1+ (1,0) [0|0] "" Vector__XXX
 SG_ PCS2_dcdcBStateMachineState m1 : 12|3@1+ (1,0) [0|0] "" Vector__XXX
 SG_ PCS2_gridFormStateMachineState m135 : 12|3@1+ (1,0) [0|0] "" Vector__XXX
 SG_ PCS2_mfgFuncTestBlockID m12 : 12|6@1+ (1,0) [0|0] "" Vector__XXX
 SG_ PCS2_mfgFuncTestCalIterativeCtrlID m14 : 12|1@1+ (1,0) [0|0] "" Vector__XXX
 SG_ PCS2_mfgFuncTestCalPiCtrlEnable m13 : 12|1@1+ (1,0) [0|0] "" Vector__XXX
 SG_ PCS2_L2L3AvailableForCharging m140 : 13|1@1+ (1,0) [0|0] "" Vector__XXX
 SG_ PCS2_L1NExpectedWhileCharging m140 : 14|1@1+ (1,0) [0|0] "" Vector__XXX
 SG_ PCS2_cycloAMosfetHealthCheckStatus m22 : 14|2@1+ (1,0) [0|0] "" Vector__XXX
 SG_ PCS2_cycloNumWire m131 : 14|2@1+ (1,0) [0|0] "" Vector__XXX
 SG_ PCS2_L2NExpectedWhileCharging m140 : 15|1@1+ (1,0) [0|0] "" Vector__XXX
 SG_ PCS2_L3NExpectedWhileCharging m140 : 16|1@1+ (1,0) [0|0] "" Vector__XXX
 SG_ PCS2_cpu0Task5kHzUtilizationPercentageMax10s m23 : 16|8@1+ (1,0) [0|0] "" Vector__XXX
 SG_ PCS2_cpu1Task5kHzUtilizationPercentageMax10s m95 : 16|8@1+ (1,0) [0|0] "" Vector__XXX
 SG_ PCS2_cpu2Task5kHzUtilizationPercentageMax10s m158 : 16|8@1+ (1,0) [0|0] "" Vector__XXX
 SG_ PCS2_cpu3Task5kHzUtilizationPercentageMax10s m206 : 16|8@1+ (1,0) [0|0] "" Vector__XXX
 SG_ PCS2_cycloAStageStateMachineState m135 : 16|3@1+ (1,0) [0|0] "" Vector__XXX
 SG_ PCS2_cycloATxTempDeratingFactor m143 : 16|7@1+ (0.01,0) [0|0] "" Vector__XXX
 SG_ PCS2_cycloBMosfetHealthCheckStatus m22 : 16|2@1+ (1,0) [0|0] "" Vector__XXX
 SG_ PCS2_cycloBTxTempDeratingFactor m195 : 16|7@1+ (0.01,0) [0|0] "" Vector__XXX
 SG_ PCS2_dcdcADeltaEnergy m19 : 16|16@1+ (1,0) [0|0] "" Vector__XXX
 SG_ PCS2_dcdcASmPrechargeRetryCnt m17 : 16|4@1+ (1,0) [0|0] "" Vector__XXX
 SG_ PCS2_dcdcAStageModeRequest m1 : 16|2@1+ (1,0) [0|0] "" Vector__XXX
 SG_ PCS2_dcdcBDeltaEnergy m76 : 16|16@1+ (1,0) [0|0] "" Vector__XXX
 SG_ PCS2_dcdcBSmPrechargeRetryCnt m74 : 16|4@1+ (1,0) [0|0] "" Vector__XXX
 SG_ PCS2_gridFrequency m131 : 16|13@1+ (0.01,0) [0|0] "" Vector__XXX
 SG_ PCS2_ipcCpu0ToCpu3MaxSuccessiveLockGrabFails m18 : 16|3@1+ (1,0) [0|0] "" Vector__XXX
 SG_ PCS2_ipcCpu1ToCpu3MaxSuccessiveLockGrabFails m75 : 16|3@1+ (1,0) [0|0] "" Vector__XXX
 SG_ PCS2_ipcCpu2ToCpu3MaxSuccessiveLockGrabFails m154 : 16|3@1+ (1,0) [0|0] "" Vector__XXX
 SG_ PCS2_ipcCpu3ToCpu2MaxSuccessiveLockGrabFails m200 : 16|3@1+ (1,0) [0|0] "" Vector__XXX
 SG_ PCS2_lite_boost_duty_min_10s m32 : 16|7@1+ (0.01,0) [0|0] "" Vector__XXX
 SG_ PCS2_llcControllerFreqMHzMax10s m4 : 16|8@1+ (0.01,0) [0|0] "" Vector__XXX
 SG_ PCS2_mfgFuncTestCalPiReference m13 : 16|5@1+ (1,0) [0|0] "" Vector__XXX
 SG_ PCS2_mfgFuncTestResult2 m14 : 16|14@1- (0.01,0) [0|0] "" Vector__XXX
 SG_ PCS2_microgridHeartbeat1hzRms m201 : 16|8@1+ (0.001,0) [0|0] "" Vector__XXX
 SG_ PCS2_phase_diff_L1N_L3N m141 : 16|8@1+ (1,0) [0|0] "" Vector__XXX
 SG_ PCS2_L1L2ExpectedWhileCharging m140 : 17|1@1+ (1,0) [0|0] "" Vector__XXX
 SG_ PCS2_acL2ChassisVrms m138 : 17|9@1+ (1,0) [0|0] "" Vector__XXX
 SG_ PCS2_acL2CurrentLimitI2T m148 : 17|9@1+ (1,0) [0|0] "" Vector__XXX
 SG_ PCS2_cycloAC_L2PeakCurrent m192 : 17|9@1+ (1,0) [0|0] "" Vector__XXX
 SG_ PCS2_cycloA_tank_zcd_event_pu_min_1s m155 : 17|9@1- (0.01,0) [0|0] "" Vector__XXX
 SG_ PCS2_cycloB_tank_zcd_event_pu_min_1s m202 : 17|9@1- (0.01,0) [0|0] "" Vector__XXX
 SG_ PCS2_dcOffsetL2NVoltage m204 : 17|9@1- (4,0) [0|0] "" Vector__XXX
 SG_ PCS2_dcOffsetL3NPreRelayVoltage m205 : 17|9@1- (4,0) [0|0] "" Vector__XXX
 SG_ PCS2_dcdcALvMosfetModelHvCurrentLimit m11 : 17|14@1- (0.01,0) [0|0] "" Vector__XXX
 SG_ PCS2_dcdcA_tank_zcd_event_pu_min_1s m20 : 17|9@1- (0.01,0) [0|0] "" Vector__XXX
 SG_ PCS2_dcdcBHvMosfetModelHvCurrentLimit m96 : 17|14@1- (0.01,0) [0|0] "" Vector__XXX
 SG_ PCS2_dcdcBLvMosfetModelHvCurrentLimit m72 : 17|14@1- (0.01,0) [0|0] "" Vector__XXX
 SG_ PCS2_dcdcB_tank_zcd_event_pu_min_1s m77 : 17|9@1- (0.01,0) [0|0] "" Vector__XXX
 SG_ PCS2_L1L3ExpectedWhileCharging m140 : 18|1@1+ (1,0) [0|0] "" Vector__XXX
 SG_ PCS2_acL1L3Vrms m129 : 18|10@1+ (0.5,0) [0|0] "" Vector__XXX
 SG_ PCS2_acL2ContinuousCurrentLimit m149 : 18|10@1+ (0.1,0) [0|0] "" Vector__XXX
 SG_ PCS2_acL2GeneratedHeatI2TCpLimit m159 : 18|10@1+ (0.1,0) [0|0] "" Vector__XXX
 SG_ PCS2_acL2GeneratedHeatI2THwLimit m150 : 18|10@1+ (0.1,0) [0|0] "" Vector__XXX
 SG_ PCS2_acL2NVrms m128 : 18|10@1+ (0.5,0) [0|0] "" Vector__XXX
 SG_ PCS2_acL2TransientCurrentLimit m147 : 18|10@1+ (0.1,0) [0|0] "" Vector__XXX
 SG_ PCS2_acL3NPreRelayVrms m157 : 18|10@1+ (0.5,0) [0|0] "" Vector__XXX
 SG_ PCS2_aggregatedWithUserChargingCurrentLimit m139 : 18|10@1+ (0.1,0) [0|0] "" Vector__XXX
 SG_ PCS2_cycloXcapHealthCheckStatus m22 : 18|2@1+ (1,0) [0|0] "" Vector__XXX
 SG_ PCS2_dcdcAHalfBusTopVoltageMax_10s m7 : 18|10@1+ (1,0) [0|0] "" Vector__XXX
 SG_ PCS2_dcdcBHalfBusTopVoltageMax_10s m68 : 18|10@1+ (1,0) [0|0] "" Vector__XXX
 SG_ PCS2_dcdcBStageModeRequest m1 : 18|2@1+ (1,0) [0|0] "" Vector__XXX
 SG_ PCS2_lite_BoostCurrentPeakMax10s m38 : 18|10@1+ (0.05,0) [0|0] "" Vector__XXX
 SG_ PCS2_mfgFuncTestID m12 : 18|10@1+ (1,0) [0|0] "" Vector__XXX
 SG_ PCS2_mfgFuncTestIOXWrRetryHWM m15 : 18|10@1+ (1,0) [0|0] "" Vector__XXX
 SG_ PCS2_L2L3ExpectedWhileCharging m140 : 19|1@1+ (1,0) [0|0] "" Vector__XXX
 SG_ PCS2_cycloAC_L1L3PeakV m160 : 19|11@1+ (0.5,0) [0|0] "" Vector__XXX
 SG_ PCS2_cycloAC_L1NPeakV m136 : 19|11@1+ (0.5,0) [0|0] "" Vector__XXX
 SG_ PCS2_cycloBStageStateMachineState m135 : 19|3@1+ (1,0) [0|0] "" Vector__XXX
 SG_ PCS2_cyclo_A_l1_device_temp m144 : 19|11@1+ (0.1,0) [0|0] "" Vector__XXX
 SG_ PCS2_cyclo_A_l1_device_temp_max m145 : 19|11@1+ (0.1,0) [0|0] "" Vector__XXX
 SG_ PCS2_cyclo_B_l1_device_temp m196 : 19|11@1+ (0.1,0) [0|0] "" Vector__XXX
 SG_ PCS2_cyclo_B_l1_device_temp_max m197 : 19|11@1+ (0.1,0) [0|0] "" Vector__XXX
 SG_ PCS2_dcacA_ac1TempIrrational m86 : 19|1@1+ (1,0) [0|0] "" Vector__XXX
 SG_ PCS2_dcacA_ac2TempMax_10s m91 : 19|11@1- (0.15,70.05) [0|0] "" Vector__XXX
 SG_ PCS2_dcacA_ac2TempMin_10s m90 : 19|11@1- (0.15,70.05) [0|0] "" Vector__XXX
 SG_ PCS2_dcacB_ac1TempIrrational m87 : 19|1@1+ (1,0) [0|0] "" Vector__XXX
 SG_ PCS2_dcacB_ac2TempMax_10s m93 : 19|11@1- (0.15,70.05) [0|0] "" Vector__XXX
 SG_ PCS2_dcacB_ac2TempMin_10s m92 : 19|11@1- (0.15,70.05) [0|0] "" Vector__XXX
 SG_ PCS2_dcacB_transformerTemp m89 : 19|11@1- (0.15,70.05) [0|0] "" Vector__XXX
 SG_ PCS2_dcacB_transformerTempMax_10s m82 : 19|11@1- (0.15,70.05) [0|0] "" Vector__XXX
 SG_ PCS2_dcacB_transformerTempMin_10s m94 : 19|11@1- (0.15,70.05) [0|0] "" Vector__XXX
 SG_ PCS2_dcdcA_lv1TempIrrational m98 : 19|1@1+ (1,0) [0|0] "" Vector__XXX
 SG_ PCS2_dcdcA_lv2TempIrrational m88 : 19|1@1+ (1,0) [0|0] "" Vector__XXX
 SG_ PCS2_dcdcB_lv2TempMax_10s m80 : 19|11@1- (0.15,70.05) [0|0] "" Vector__XXX
 SG_ PCS2_dcdcB_lv2TempMin_10s m79 : 19|11@1- (0.15,70.05) [0|0] "" Vector__XXX
 SG_ PCS2_dcdc_hvTempIrrational m81 : 19|1@1+ (1,0) [0|0] "" Vector__XXX
 SG_ PCS2_ipcCpu0ToCpu1TotalPeriodicLockGrabFails m18 : 19|9@1+ (1,0) [0|0] "" Vector__XXX
 SG_ PCS2_ipcCpu1ToCpu0TotalPeriodicLockGrabFails m75 : 19|9@1+ (1,0) [0|0] "" Vector__XXX
 SG_ PCS2_ipcCpu2ToCpu0TotalPeriodicLockGrabFails m154 : 19|9@1+ (1,0) [0|0] "" Vector__XXX
 SG_ PCS2_ipcCpu3ToCpu0TotalPeriodicLockGrabFails m200 : 19|9@1+ (1,0) [0|0] "" Vector__XXX
 SG_ PCS2_lite_coolantOutTemp m84 : 19|11@1- (0.15,70.05) [0|0] "" Vector__XXX
 SG_ PCS2_lite_dcdc_LV_B_Temp m85 : 19|11@1- (0.15,70.05) [0|0] "" Vector__XXX
 SG_ PCS2_10V0RailSenseMax10s m24 : 20|12@1+ (0.01,0) [0|0] "" Vector__XXX
 SG_ PCS2_13V5RailSenseMax10s m29 : 20|12@1+ (0.01,0) [0|0] "" Vector__XXX
 SG_ PCS2_18V0RailSenseMax10s m16 : 20|12@1+ (0.01,0) [0|0] "" Vector__XXX
 SG_ PCS2_1V6RailSenseMax10s m26 : 20|12@1+ (0.01,0) [0|0] "" Vector__XXX
 SG_ PCS2_4V5RailSenseMax10s m25 : 20|12@1+ (0.01,0) [0|0] "" Vector__XXX
 SG_ PCS2_FC_P_VSense m31 : 20|12@1- (1,0) [0|0] "" Vector__XXX
 SG_ PCS2_L1NLatchedExpectedWhileCharging m140 : 20|1@1+ (1,0) [0|0] "" Vector__XXX
 SG_ PCS2_acL2Arms m130 : 20|12@1+ (0.1,0) [0|0] "" Vector__XXX
 SG_ PCS2_cycloATankLeakInductance m137 : 20|11@1+ (0.1,0) [0|0] "" Vector__XXX
 SG_ PCS2_cycloBTankLeakInductance m193 : 20|11@1+ (0.1,0) [0|0] "" Vector__XXX
 SG_ PCS2_dcacA_ac2Temp m86 : 20|11@1- (0.15,70.05) [0|0] "" Vector__XXX
 SG_ PCS2_dcacB_ac2Temp m87 : 20|11@1- (0.15,70.05) [0|0] "" Vector__XXX
 SG_ PCS2_dcdcASmDischargeRetryCnt m17 : 20|4@1+ (1,0) [0|0] "" Vector__XXX
 SG_ PCS2_dcdcATankLeakInductance m8 : 20|11@1+ (0.1,0) [0|0] "" Vector__XXX
 SG_ PCS2_dcdcBSmDischargeRetryCnt m74 : 20|4@1+ (1,0) [0|0] "" Vector__XXX
 SG_ PCS2_dcdcBTankLeakInductance m69 : 20|11@1+ (0.1,0) [0|0] "" Vector__XXX
 SG_ PCS2_dcdcB_lv1Temp m98 : 20|11@1- (0.15,70.05) [0|0] "" Vector__XXX
 SG_ PCS2_dcdcB_lv2Temp m88 : 20|11@1- (0.15,70.05) [0|0] "" Vector__XXX
 SG_ PCS2_dcdc_LVRightTemp m81 : 20|11@1- (0.15,70.05) [0|0] "" Vector__XXX
 SG_ PCS2_lite_lvBiasRailSenseMax10s m33 : 20|12@1+ (0.01,0) [0|0] "" Vector__XXX
 SG_ PCS2_L2NLatchedExpectedWhileCharging m140 : 21|1@1+ (1,0) [0|0] "" Vector__XXX
 SG_ PCS2_L3NLatchedExpectedWhileCharging m140 : 22|1@1+ (1,0) [0|0] "" Vector__XXX
 SG_ PCS2_cycloACmdSwitchingFreq_min_1s m156 : 22|14@1+ (0.1,150) [0|0] "" Vector__XXX
 SG_ PCS2_cycloAEnableRequest m135 : 22|1@1+ (1,0) [0|0] "" Vector__XXX
 SG_ PCS2_cycloBCmdSwitchingFreq_min_1s m203 : 22|14@1+ (0.1,150) [0|0] "" Vector__XXX
 SG_ PCS2_L1L2LatchedExpectedWhileCharging m140 : 23|1@1+ (1,0) [0|0] "" Vector__XXX
 SG_ PCS2_cycloBEnableRequest m135 : 23|1@1+ (1,0) [0|0] "" Vector__XXX
 SG_ PCS2_48V0RailSenseMax10s m27 : 24|13@1+ (0.01,0) [0|0] "" Vector__XXX
 SG_ PCS2_48V0_18V0_CurrentSenseMax10s m28 : 24|13@1- (0.01,0) [0|0] "" Vector__XXX
 SG_ PCS2_L1L3LatchedExpectedWhileCharging m140 : 24|1@1+ (1,0) [0|0] "" Vector__XXX
 SG_ PCS2_acFrequencyL1L3 m133 : 24|13@1+ (0.01,0) [0|0] "" Vector__XXX
 SG_ PCS2_acFrequencyL2N m132 : 24|13@1+ (0.01,0) [0|0] "" Vector__XXX
 SG_ PCS2_cpu0Task1kHzUtilizationPercentageMax10s m23 : 24|8@1+ (1,0) [0|0] "" Vector__XXX
 SG_ PCS2_cpu1Task1kHzUtilizationPercentageMax10s m95 : 24|8@1+ (1,0) [0|0] "" Vector__XXX
 SG_ PCS2_cpu2Task1kHzUtilizationPercentageMax10s m158 : 24|8@1+ (1,0) [0|0] "" Vector__XXX
 SG_ PCS2_cpu3Task1kHzUtilizationPercentageMax10s m206 : 24|8@1+ (1,0) [0|0] "" Vector__XXX
 SG_ PCS2_cycloADcTempDeratingFactor m143 : 24|7@1+ (0.01,0) [0|0] "" Vector__XXX
 SG_ PCS2_cycloARetryCount m135 : 24|4@1+ (1,0) [0|0] "" Vector__XXX
 SG_ PCS2_cycloA_L_magnetizing m142 : 24|15@1+ (0.1,0) [0|0] "" Vector__XXX
 SG_ PCS2_cycloBDcTempDeratingFactor m195 : 24|7@1+ (0.01,0) [0|0] "" Vector__XXX
 SG_ PCS2_cycloB_L_magnetizing m194 : 24|15@1+ (0.1,0) [0|0] "" Vector__XXX
 SG_ PCS2_dcacHvBusCurrent m134 : 24|15@1- (0.01,0) [0|0] "" Vector__XXX
 SG_ PCS2_dcdcACmdSwitchingFreq_min_1s m21 : 24|14@1+ (0.1,150) [0|0] "" Vector__XXX
 SG_ PCS2_dcdcAHvVoltageFiltered m0 : 24|14@1+ (0.1,0) [0|0] "" Vector__XXX
 SG_ PCS2_dcdcAHvVoltageMax_10s m5 : 24|14@1+ (0.1,0) [0|0] "" Vector__XXX
 SG_ PCS2_dcdcAHvVoltageTarget m9 : 24|14@1+ (0.1,0) [0|0] "" Vector__XXX
 SG_ PCS2_dcdcALvCurrentCommand m2 : 24|13@1- (0.1,0) [0|0] "" Vector__XXX
 SG_ PCS2_dcdcAMinFaultDurationTicks m17 : 24|14@1+ (1,0) [0|0] "" Vector__XXX
 SG_ PCS2_dcdcA_L_magnetizing m6 : 24|15@1+ (0.1,0) [0|0] "" Vector__XXX
 SG_ PCS2_dcdcBCmdSwitchingFreq_min_1s m78 : 24|14@1+ (0.1,150) [0|0] "" Vector__XXX
 SG_ PCS2_dcdcBHvVoltageFiltered m64 : 24|14@1+ (0.1,0) [0|0] "" Vector__XXX
 SG_ PCS2_dcdcBHvVoltageMax_10s m66 : 24|14@1+ (0.1,0) [0|0] "" Vector__XXX
 SG_ PCS2_dcdcBHvVoltageTarget m70 : 24|14@1+ (0.1,0) [0|0] "" Vector__XXX
 SG_ PCS2_dcdcBLvCurrentCommand m65 : 24|13@1- (0.1,0) [0|0] "" Vector__XXX
 SG_ PCS2_dcdcBMinFaultDurationTicks m74 : 24|14@1+ (1,0) [0|0] "" Vector__XXX
 SG_ PCS2_dcdcB_L_magnetizing m67 : 24|15@1+ (0.1,0) [0|0] "" Vector__XXX
 SG_ PCS2_dcdcHvBusCurrent m83 : 24|15@1- (0.01,0) [0|0] "" Vector__XXX
 SG_ PCS2_hvBusEstimatedImpedanceLinear m73 : 24|16@1+ (10,0) [0|0] "" Vector__XXX
 SG_ PCS2_lite_boost_duty_max_10s m32 : 24|7@1+ (0.01,0) [0|0] "" Vector__XXX
 SG_ PCS2_llcControllerFreqMHzMin10s m4 : 24|8@1+ (0.01,0) [0|0] "" Vector__XXX
 SG_ PCS2_mfgFuncTestCalCtrlFreq_MHz m13 : 24|12@1+ (0.001,0) [0|0] "" Vector__XXX
 SG_ PCS2_microgridHeartbeat2hzRms m201 : 24|8@1+ (0.001,0) [0|0] "" Vector__XXX
 SG_ PCS2_phase_diff_L2N_L3N m141 : 24|8@1+ (1,0) [0|0] "" Vector__XXX
 SG_ PCS2_L2L3LatchedExpectedWhileCharging m140 : 25|1@1+ (1,0) [0|0] "" Vector__XXX
 SG_ PCS2_acL3ChassisVrms m138 : 26|9@1+ (1,0) [0|0] "" Vector__XXX
 SG_ PCS2_acL3CurrentLimitI2T m148 : 26|9@1+ (1,0) [0|0] "" Vector__XXX
 SG_ PCS2_cycloAC_L3PeakCurrent m192 : 26|9@1+ (1,0) [0|0] "" Vector__XXX
 SG_ PCS2_cycloA_tank_zcd_half_prd_meas_pu_max_1s m155 : 26|9@1- (0.01,0) [0|0] "" Vector__XXX
 SG_ PCS2_cycloB_tank_zcd_half_prd_meas_pu_max_1s m202 : 26|9@1- (0.01,0) [0|0] "" Vector__XXX
 SG_ PCS2_dcOffsetL3NVoltage m204 : 26|9@1- (4,0) [0|0] "" Vector__XXX
 SG_ PCS2_dcdcA_tank_zcd_half_prd_meas_pu_max_1s m20 : 26|9@1- (0.01,0) [0|0] "" Vector__XXX
 SG_ PCS2_dcdcB_tank_zcd_half_prd_meas_pu_max_1s m77 : 26|9@1- (0.01,0) [0|0] "" Vector__XXX
 SG_ PCS2_pcs2_pwm_xbar_time_index m35 : 26|6@1+ (1,0) [0|0] "" Vector__XXX
 SG_ PCS2_pcs2lite_pwm_xbar_time_index m36 : 26|6@1+ (1,0) [0|0] "" Vector__XXX
 SG_ PCS2_pcsci_pwm_xbar_time_index m37 : 26|6@1+ (1,0) [0|0] "" Vector__XXX
 SG_ PCS2_acL2L3Vrms m129 : 28|10@1+ (0.5,0) [0|0] "" Vector__XXX
 SG_ PCS2_acL3ContinuousCurrentLimit m149 : 28|10@1+ (0.1,0) [0|0] "" Vector__XXX
 SG_ PCS2_acL3GeneratedHeatI2TCpLimit m159 : 28|10@1+ (0.1,0) [0|0] "" Vector__XXX
 SG_ PCS2_acL3GeneratedHeatI2THwLimit m150 : 28|10@1+ (0.1,0) [0|0] "" Vector__XXX
 SG_ PCS2_acL3NVrms m128 : 28|10@1+ (0.5,0) [0|0] "" Vector__XXX
 SG_ PCS2_acL3TransientCurrentLimit m147 : 28|10@1+ (0.1,0) [0|0] "" Vector__XXX
 SG_ PCS2_acRelayState m157 : 28|3@1+ (1,0) [0|0] "" Vector__XXX
 SG_ PCS2_cycloChargingCurrentCommand m139 : 28|10@1+ (0.1,0) [0|0] "" Vector__XXX
 SG_ PCS2_dcdcAHalfBusBotVoltageMin_10s m7 : 28|10@1+ (1,0) [0|0] "" Vector__XXX
 SG_ PCS2_dcdcBHalfBusBotVoltageMin_10s m68 : 28|10@1+ (1,0) [0|0] "" Vector__XXX
 SG_ PCS2_ipcCpu0ToCpu2TotalPeriodicLockGrabFails m18 : 28|9@1+ (1,0) [0|0] "" Vector__XXX
 SG_ PCS2_ipcCpu1ToCpu2TotalPeriodicLockGrabFails m75 : 28|9@1+ (1,0) [0|0] "" Vector__XXX
 SG_ PCS2_ipcCpu2ToCpu1TotalPeriodicLockGrabFails m154 : 28|9@1+ (1,0) [0|0] "" Vector__XXX
 SG_ PCS2_ipcCpu3ToCpu1TotalPeriodicLockGrabFails m200 : 28|9@1+ (1,0) [0|0] "" Vector__XXX
 SG_ PCS2_lite_BoostCurrentValley m38 : 28|10@1+ (0.05,0) [0|0] "" Vector__XXX
 SG_ PCS2_mfgFuncTestACLineMosfetCount m12 : 28|3@1+ (1,0) [0|0] "" Vector__XXX
 SG_ PCS2_cyclo_A_l2_device_temp m144 : 30|11@1+ (0.1,0) [0|0] "" Vector__XXX
 SG_ PCS2_cyclo_A_l2_device_temp_max m145 : 30|11@1+ (0.1,0) [0|0] "" Vector__XXX
 SG_ PCS2_cyclo_B_l2_device_temp m196 : 30|11@1+ (0.1,0) [0|0] "" Vector__XXX
 SG_ PCS2_cyclo_B_l2_device_temp_max m197 : 30|11@1+ (0.1,0) [0|0] "" Vector__XXX
 SG_ PCS2_mfgFuncTestCalPiCtrlEnable2 m14 : 30|1@1+ (1,0) [0|0] "" Vector__XXX
 SG_ PCS2_dcacA_ac2TempIrrational m86 : 31|1@1+ (1,0) [0|0] "" Vector__XXX
 SG_ PCS2_dcacB_ac2TempIrrational m87 : 31|1@1+ (1,0) [0|0] "" Vector__XXX
 SG_ PCS2_dcdcATankCapacitance m8 : 31|9@1+ (0.05,15) [0|0] "" Vector__XXX
 SG_ PCS2_dcdcATxWindingModelTemp m11 : 31|9@1- (1,106) [0|0] "" Vector__XXX
 SG_ PCS2_dcdcBTankCapacitance m69 : 31|9@1+ (0.05,15) [0|0] "" Vector__XXX
 SG_ PCS2_dcdcBTxWindingModelTemp m72 : 31|9@1- (1,106) [0|0] "" Vector__XXX
 SG_ PCS2_dcdcB_lv1TempIrrational m98 : 31|1@1+ (1,0) [0|0] "" Vector__XXX
 SG_ PCS2_dcdcB_lv2TempIrrational m88 : 31|1@1+ (1,0) [0|0] "" Vector__XXX
 SG_ PCS2_dcdc_LVLeftTemp m81 : 31|11@1- (0.15,70.05) [0|0] "" Vector__XXX
 SG_ PCS2_mfgFuncTestACTankMosfetCount m12 : 31|2@1+ (1,0) [0|0] "" Vector__XXX
 SG_ PCS2_10V0RailSenseMin10s m24 : 32|12@1+ (0.01,0) [0|0] "" Vector__XXX
 SG_ PCS2_13V5RailSenseMin10s m29 : 32|12@1+ (0.01,0) [0|0] "" Vector__XXX
 SG_ PCS2_18V0RailSenseMin10s m16 : 32|12@1+ (0.01,0) [0|0] "" Vector__XXX
 SG_ PCS2_1V6RailSenseMin10s m26 : 32|12@1+ (0.01,0) [0|0] "" Vector__XXX
 SG_ PCS2_4V5RailSenseMin10s m25 : 32|12@1+ (0.01,0) [0|0] "" Vector__XXX
 SG_ PCS2_FC_N_VSense m31 : 32|12@1- (1,0) [0|0] "" Vector__XXX
 SG_ PCS2_acL3Arms m130 : 32|12@1+ (0.1,0) [0|0] "" Vector__XXX
 SG_ PCS2_ambientTemp m89 : 32|11@1- (0.15,70.05) [0|0] "" Vector__XXX
 SG_ PCS2_ambientTempMax_10s m82 : 32|11@1- (0.15,70.05) [0|0] "" Vector__XXX
 SG_ PCS2_ambientTempMin_10s m94 : 32|11@1- (0.15,70.05) [0|0] "" Vector__XXX
 SG_ PCS2_cabinAndBedL2L3LifetimekVAh m153 : 32|24@1+ (0.01,0) [0|0] "" Vector__XXX
 SG_ PCS2_cpGridFormLifetimekVAh m151 : 32|24@1+ (0.01,0) [0|0] "" Vector__XXX
 SG_ PCS2_cycloAC_L2L3PeakV m160 : 32|11@1+ (0.5,0) [0|0] "" Vector__XXX
 SG_ PCS2_cycloAC_L2NPeakV m136 : 32|11@1+ (0.5,0) [0|0] "" Vector__XXX
 SG_ PCS2_cycloAJunctionTempDeratingFactor m143 : 32|7@1+ (0.01,0) [0|0] "" Vector__XXX
 SG_ PCS2_cycloALineTransientRetryCount m135 : 32|7@1+ (0.1,0) [0|0] "" Vector__XXX
 SG_ PCS2_cycloATankCapacitance m137 : 32|10@1+ (0.1,50) [0|0] "" Vector__XXX
 SG_ PCS2_cycloBJunctionTempDeratingFactor m195 : 32|7@1+ (0.01,0) [0|0] "" Vector__XXX
 SG_ PCS2_cycloBTankCapacitance m193 : 32|10@1+ (0.1,50) [0|0] "" Vector__XXX
 SG_ PCS2_cyclo_A_hvdc_oc_count m146 : 32|8@1+ (1,0) [0|0] "" Vector__XXX
 SG_ PCS2_cyclo_B_hvdc_oc_count m198 : 32|8@1+ (1,0) [0|0] "" Vector__XXX
 SG_ PCS2_dcacA_dcTemp m86 : 32|11@1- (0.15,70.05) [0|0] "" Vector__XXX
 SG_ PCS2_dcacA_dcTempMax_10s m91 : 32|11@1- (0.15,70.05) [0|0] "" Vector__XXX
 SG_ PCS2_dcacA_dcTempMin_10s m90 : 32|11@1- (0.15,70.05) [0|0] "" Vector__XXX
 SG_ PCS2_dcacB_dcTemp m87 : 32|11@1- (0.15,70.05) [0|0] "" Vector__XXX
 SG_ PCS2_dcacB_dcTempMax_10s m93 : 32|11@1- (0.15,70.05) [0|0] "" Vector__XXX
 SG_ PCS2_dcacB_dcTempMin_10s m92 : 32|11@1- (0.15,70.05) [0|0] "" Vector__XXX
 SG_ PCS2_dcdcAVoltageErrorTooLarge m19 : 32|1@1+ (1,0) [0|0] "" Vector__XXX
 SG_ PCS2_dcdcA_hvTemp m88 : 32|11@1- (0.15,70.05) [0|0] "" Vector__XXX
 SG_ PCS2_dcdcA_hvTempMax_10s m80 : 32|11@1- (0.15,70.05) [0|0] "" Vector__XXX
 SG_ PCS2_dcdcA_hvTempMin_10s m79 : 32|11@1- (0.15,70.05) [0|0] "" Vector__XXX
 SG_ PCS2_dcdcBVoltageErrorTooLarge m76 : 32|1@1+ (1,0) [0|0] "" Vector__XXX
 SG_ PCS2_lite_buck_duty m32 : 32|7@1+ (0.01,0) [0|0] "" Vector__XXX
 SG_ PCS2_lite_dcac_dcTemp m84 : 32|11@1- (0.15,70.05) [0|0] "" Vector__XXX
 SG_ PCS2_lite_dcdc_LV_C_Temp m85 : 32|11@1- (0.15,70.05) [0|0] "" Vector__XXX
 SG_ PCS2_lite_lvBiasRailSenseMin10s m33 : 32|12@1+ (0.01,0) [0|0] "" Vector__XXX
 SG_ PCS2_mfgFuncTestCalPiReference2 m14 : 32|5@1+ (1,0) [0|0] "" Vector__XXX
 SG_ PCS2_mfgFuncTestIOXWrExpected m15 : 32|16@1+ (1,0) [0|0] "" Vector__XXX
 SG_ PCS2_pcs2_pwm_xbar_DCDCA_TANK_ZCD m35 : 32|1@1+ (1,0) [0|0] "" Vector__XXX
 SG_ PCS2_pcs2lite_pwm_xbar_DCDCB_TANK_ZCD m36 : 32|1@1+ (1,0) [0|0] "" Vector__XXX
 SG_ PCS2_pcsci_pwm_xbar_DCDCB_TANK_ZCD m37 : 32|1@1+ (1,0) [0|0] "" Vector__XXX
 SG_ PCS2_phase_diff_L1L3_L2L3 m141 : 32|8@1+ (1,0) [0|0] "" Vector__XXX
 SG_ PCS2_remoteFilteredCoolantTemp m4 : 32|8@1- (1,46) [0|0] "" Vector__XXX
 SG_ PCS2_totalOutletLifetimekVAh m152 : 32|24@1+ (0.01,0) [0|0] "" Vector__XXX
 SG_ PCS2_dcdcACloseToPowerLimit m19 : 33|1@1+ (1,0) [0|0] "" Vector__XXX
 SG_ PCS2_dcdcBCloseToPowerLimit m76 : 33|1@1+ (1,0) [0|0] "" Vector__XXX
 SG_ PCS2_mfgFuncTestSwitchingFreq m12 : 33|14@1+ (0.1,150) [0|0] "" Vector__XXX
 SG_ PCS2_pcs2_pwm_xbar_ANY_LN_OC m35 : 33|1@1+ (1,0) [0|0] "" Vector__XXX
 SG_ PCS2_pcs2lite_pwm_xbar_ANY_LN_OC m36 : 33|1@1+ (1,0) [0|0] "" Vector__XXX
 SG_ PCS2_dcdcATransientPowerNotEnough m19 : 34|1@1+ (1,0) [0|0] "" Vector__XXX
 SG_ PCS2_dcdcBTransientPowerNotEnough m76 : 34|1@1+ (1,0) [0|0] "" Vector__XXX
 SG_ PCS2_pcs2_pwm_xbar_CYCLOA_TANK_ZCD m35 : 34|1@1+ (1,0) [0|0] "" Vector__XXX
 SG_ PCS2_acL2PreRelayChassisVrms m138 : 35|9@1+ (1,0) [0|0] "" Vector__XXX
 SG_ PCS2_acLNCurrentLimitI2T m148 : 35|9@1+ (1,0) [0|0] "" Vector__XXX
 SG_ PCS2_cycloAC_NPeakCurrent m192 : 35|9@1+ (1,0) [0|0] "" Vector__XXX
 SG_ PCS2_cycloA_tank_zcd_half_prd_meas_pu_min_1s m155 : 35|9@1- (0.01,0) [0|0] "" Vector__XXX
 SG_ PCS2_cycloB_tank_zcd_half_prd_meas_pu_min_1s m202 : 35|9@1- (0.01,0) [0|0] "" Vector__XXX
 SG_ PCS2_dcOffsetL1L2Voltage m204 : 35|9@1- (4,0) [0|0] "" Vector__XXX
 SG_ PCS2_dcdcA_tank_zcd_half_prd_meas_pu_min_1s m20 : 35|9@1- (0.01,0) [0|0] "" Vector__XXX
 SG_ PCS2_dcdcB_tank_zcd_half_prd_meas_pu_min_1s m77 : 35|9@1- (0.01,0) [0|0] "" Vector__XXX
 SG_ PCS2_pcs2_pwm_xbar_CYCLOA_SECONDARY_TRIPOUT m35 : 35|1@1+ (1,0) [0|0] "" Vector__XXX
 SG_ PCS2_pcs2lite_pwm_xbar_CYCLOA_SECONDARY_TRIPOUT m36 : 35|1@1+ (1,0) [0|0] "" Vector__XXX
 SG_ PCS2_cycloA_tank_zcd_measured_freq_max_1s m156 : 36|14@1+ (0.1,150) [0|0] "" Vector__XXX
 SG_ PCS2_cycloB_tank_zcd_measured_freq_max_1s m203 : 36|14@1+ (0.1,150) [0|0] "" Vector__XXX
 SG_ PCS2_mfg_nvm_gdps_id_begin m13 : 36|3@1+ (1,0) [0|0] "" Vector__XXX
 SG_ PCS2_pcs2_pwm_xbar_CYCLOB_SECONDARY_TRIPOUT m35 : 36|1@1+ (1,0) [0|0] "" Vector__XXX
 SG_ PCS2_dcdcAPowerLimit m2 : 37|12@1+ (1,0) [0|0] "" Vector__XXX
 SG_ PCS2_dcdcBPowerLimit m65 : 37|12@1+ (1,0) [0|0] "" Vector__XXX
 SG_ PCS2_ipcCpu0ToCpu3TotalPeriodicLockGrabFails m18 : 37|9@1+ (1,0) [0|0] "" Vector__XXX
 SG_ PCS2_ipcCpu1ToCpu3TotalPeriodicLockGrabFails m75 : 37|9@1+ (1,0) [0|0] "" Vector__XXX
 SG_ PCS2_ipcCpu2ToCpu3TotalPeriodicLockGrabFails m154 : 37|9@1+ (1,0) [0|0] "" Vector__XXX
 SG_ PCS2_ipcCpu3ToCpu2TotalPeriodicLockGrabFails m200 : 37|9@1+ (1,0) [0|0] "" Vector__XXX
 SG_ PCS2_pcs2lite_pwm_xbar_DCDC_GDPS m36 : 37|1@1+ (1,0) [0|0] "" Vector__XXX
 SG_ PCS2_acGndN m128 : 38|10@1- (1,0) [0|0] "" Vector__XXX
 SG_ PCS2_acLNContinuousCurrentLimit m149 : 38|10@1+ (0.1,0) [0|0] "" Vector__XXX
 SG_ PCS2_acLNGeneratedHeatI2TCpLimit m159 : 38|10@1+ (0.1,0) [0|0] "" Vector__XXX
 SG_ PCS2_acLNGeneratedHeatI2THwLimit m150 : 38|10@1+ (0.1,0) [0|0] "" Vector__XXX
 SG_ PCS2_acLNTransientCurrentLimit m147 : 38|10@1+ (0.1,0) [0|0] "" Vector__XXX
 SG_ PCS2_cycloChargingCurrentCommandReal m139 : 38|10@1+ (0.1,0) [0|0] "" Vector__XXX
 SG_ PCS2_dcdcABursting m17 : 38|1@1+ (1,0) [0|0] "" Vector__XXX
 SG_ PCS2_dcdcAHalfBusBotVoltageMax_10s m7 : 38|10@1+ (1,0) [0|0] "" Vector__XXX
 SG_ PCS2_dcdcAHvTopVoltage m0 : 38|13@1+ (0.1,0) [0|0] "" Vector__XXX
 SG_ PCS2_dcdcBBursting m74 : 38|1@1+ (1,0) [0|0] "" Vector__XXX
 SG_ PCS2_dcdcBHalfBusBotVoltageMax_10s m68 : 38|10@1+ (1,0) [0|0] "" Vector__XXX
 SG_ PCS2_dcdcBHvTopVoltage m64 : 38|13@1+ (0.1,0) [0|0] "" Vector__XXX
 SG_ PCS2_dcdcLvVoltageMin_10s m66 : 38|13@1+ (0.01,0) [0|0] "" Vector__XXX
 SG_ PCS2_lite_BoostCurrentValleyMax10s m38 : 38|10@1+ (0.05,0) [0|0] "" Vector__XXX
 SG_ PCS2_pcs2_pwm_xbar_CYCLOA_COMBINEDX m35 : 38|1@1+ (1,0) [0|0] "" Vector__XXX
 SG_ PCS2_pcs2lite_pwm_xbar_CYCLOA_COMBINEDX m36 : 38|1@1+ (1,0) [0|0] "" Vector__XXX
 SG_ PCS2_cycloBRetryCount m135 : 39|4@1+ (1,0) [0|0] "" Vector__XXX
 SG_ PCS2_dcdcAlvuvSurgeLocked m17 : 39|1@1+ (1,0) [0|0] "" Vector__XXX
 SG_ PCS2_pcs2_pwm_xbar_CYCLOB_COMBINEDX m35 : 39|1@1+ (1,0) [0|0] "" Vector__XXX
 SG_ PCS2_pcs2lite_pwm_xbar_TEMPSENSE m36 : 39|1@1+ (1,0) [0|0] "" Vector__XXX
 SG_ PCS2_pcsci_pwm_xbar_DATA_TEMPSENSE m37 : 39|1@1+ (1,0) [0|0] "" Vector__XXX
 SG_ PCS2_48V0RailSenseMin10s m27 : 40|13@1+ (0.01,0) [0|0] "" Vector__XXX
 SG_ PCS2_48V0_18V0_CurrentSenseMin10s m28 : 40|13@1- (0.01,0) [0|0] "" Vector__XXX
 SG_ PCS2_acFrequencyL2L3 m133 : 40|13@1+ (0.01,0) [0|0] "" Vector__XXX
 SG_ PCS2_acFrequencyL3N m132 : 40|13@1+ (0.01,0) [0|0] "" Vector__XXX
 SG_ PCS2_canBusOffOccurrencePer10s m4 : 40|7@1+ (1,0) [0|0] "" Vector__XXX
 SG_ PCS2_cycloAInductorLossDeratingFactor m143 : 40|7@1+ (0.01,0) [0|0] "" Vector__XXX
 SG_ PCS2_cycloA_C_tank m142 : 40|10@1+ (0.1,50) [0|0] "" Vector__XXX
 SG_ PCS2_cycloBInductorLossDeratingFactor m195 : 40|7@1+ (0.01,0) [0|0] "" Vector__XXX
 SG_ PCS2_cycloB_C_tank m194 : 40|10@1+ (0.1,50) [0|0] "" Vector__XXX
 SG_ PCS2_dcdcAHvImpedanceEstState m9 : 40|3@1+ (1,0) [0|0] "" Vector__XXX
 SG_ PCS2_dcdcATankMagInductance m8 : 40|15@1+ (0.1,0) [0|0] "" Vector__XXX
 SG_ PCS2_dcdcATxWindingModelHvCurrentLimit m11 : 40|14@1- (0.01,0) [0|0] "" Vector__XXX
 SG_ PCS2_dcdcA_C_tank m6 : 40|10@1+ (0.05,15) [0|0] "" Vector__XXX
 SG_ PCS2_dcdcBHvImpedanceEstState m70 : 40|3@1+ (1,0) [0|0] "" Vector__XXX
 SG_ PCS2_dcdcBTankMagInductance m69 : 40|15@1+ (0.1,0) [0|0] "" Vector__XXX
 SG_ PCS2_dcdcBTankSelfTestState m74 : 40|2@1+ (1,0) [0|0] "" Vector__XXX
 SG_ PCS2_dcdcBTxWindingModelHvCurrentLimit m72 : 40|14@1- (0.01,0) [0|0] "" Vector__XXX
 SG_ PCS2_dcdcB_C_tank m67 : 40|10@1+ (0.05,15) [0|0] "" Vector__XXX
 SG_ PCS2_hvBusEstimatedImpedanceLogarithm m73 : 40|16@1+ (10,0) [0|0] "" Vector__XXX
 SG_ PCS2_lite_buck_duty_min_10s m32 : 40|7@1+ (0.01,0) [0|0] "" Vector__XXX
 SG_ PCS2_mfgFuncTestCalCtrlFreq2_MHz m14 : 40|12@1+ (0.001,0) [0|0] "" Vector__XXX
 SG_ PCS2_mfg_nvm_gdps_id_end m13 : 40|3@1+ (1,0) [0|0] "" Vector__XXX
 SG_ PCS2_pcs2_pwm_xbar_DCDCA_COMBINEDX m35 : 40|1@1+ (1,0) [0|0] "" Vector__XXX
 SG_ PCS2_pcs2lite_pwm_xbar_DCAC_GDPS_COMBINEDX m36 : 40|1@1+ (1,0) [0|0] "" Vector__XXX
 SG_ PCS2_phase_diff_pre_relay_L1N_L2N m141 : 40|8@1+ (1,0) [0|0] "" Vector__XXX
 SG_ PCS2_cyclo_A_l3_device_temp m144 : 41|11@1+ (0.1,0) [0|0] "" Vector__XXX
 SG_ PCS2_cyclo_A_l3_device_temp_max m145 : 41|11@1+ (0.1,0) [0|0] "" Vector__XXX
 SG_ PCS2_cyclo_B_l3_device_temp m196 : 41|11@1+ (0.1,0) [0|0] "" Vector__XXX
 SG_ PCS2_cyclo_B_l3_device_temp_max m197 : 41|11@1+ (0.1,0) [0|0] "" Vector__XXX
 SG_ PCS2_pcs2_pwm_xbar_DCDCB_COMBINEDX m35 : 41|1@1+ (1,0) [0|0] "" Vector__XXX
 SG_ PCS2_pcs2lite_pwm_xbar_DCDCB_COMBINEDX m36 : 41|1@1+ (1,0) [0|0] "" Vector__XXX
 SG_ PCS2_pcsci_pwm_xbar_DCDCB_COMBINEDX m37 : 41|1@1+ (1,0) [0|0] "" Vector__XXX
 SG_ PCS2_dcdcBlvuvSurgeLocked m74 : 42|1@1+ (1,0) [0|0] "" Vector__XXX
 SG_ PCS2_dcdc_CoolantInTemp m81 : 42|11@1- (0.15,70.05) [0|0] "" Vector__XXX
 SG_ PCS2_pcs2_pwm_xbar_ANY_LN_OV m35 : 42|1@1+ (1,0) [0|0] "" Vector__XXX
 SG_ PCS2_pcs2lite_pwm_xbar_ANY_LN_OV m36 : 42|1@1+ (1,0) [0|0] "" Vector__XXX
 SG_ PCS2_coolantTemp m89 : 43|11@1- (0.15,70.05) [0|0] "" Vector__XXX
 SG_ PCS2_coolantTempMax_10s m82 : 43|11@1- (0.15,70.05) [0|0] "" Vector__XXX
 SG_ PCS2_coolantTempMin_10s m94 : 43|11@1- (0.15,70.05) [0|0] "" Vector__XXX
 SG_ PCS2_cycloAC_L3NPeakV m136 : 43|11@1+ (0.5,0) [0|0] "" Vector__XXX
 SG_ PCS2_cycloBLineTransientRetryCount m135 : 43|7@1+ (0.1,0) [0|0] "" Vector__XXX
 SG_ PCS2_dcacA_dcTempIrrational m86 : 43|1@1+ (1,0) [0|0] "" Vector__XXX
 SG_ PCS2_dcacB_dcTempIrrational m87 : 43|1@1+ (1,0) [0|0] "" Vector__XXX
 SG_ PCS2_dcdcA_hvTempIrrational m88 : 43|1@1+ (1,0) [0|0] "" Vector__XXX
 SG_ PCS2_dcdcB_hvTempMax_10s m80 : 43|11@1- (0.15,70.05) [0|0] "" Vector__XXX
 SG_ PCS2_dcdcB_hvTempMin_10s m79 : 43|11@1- (0.15,70.05) [0|0] "" Vector__XXX
 SG_ PCS2_lite_dcac_dcTempIrrational m84 : 43|1@1+ (1,0) [0|0] "" Vector__XXX
 SG_ PCS2_lite_dcdc_hvTemp m85 : 43|11@1- (0.15,70.05) [0|0] "" Vector__XXX
 SG_ PCS2_mfg_nvm_num_tables_in_last_commit m13 : 43|3@1+ (1,0) [0|0] "" Vector__XXX
 SG_ PCS2_pcs2_pwm_xbar_CYCLOA_I_TANK m35 : 43|1@1+ (1,0) [0|0] "" Vector__XXX
 SG_ PCS2_pcs2lite_pwm_xbar_CYCLOA_I_TANK m36 : 43|1@1+ (1,0) [0|0] "" Vector__XXX
 SG_ PCS2_acL3PreRelayChassisVrms m138 : 44|9@1+ (1,0) [0|0] "" Vector__XXX
 SG_ PCS2_acLNArms m130 : 44|12@1+ (0.1,0) [0|0] "" Vector__XXX
 SG_ PCS2_dcOffsetL1L3Voltage m204 : 44|9@1- (4,0) [0|0] "" Vector__XXX
 SG_ PCS2_dcdcB_hvTemp m88 : 44|11@1- (0.15,70.05) [0|0] "" Vector__XXX
 SG_ PCS2_lite_dcac_ac3Temp m84 : 44|11@1- (0.15,70.05) [0|0] "" Vector__XXX
 SG_ PCS2_pcs2_pwm_xbar_CYCLOB_I_TANK m35 : 44|1@1+ (1,0) [0|0] "" Vector__XXX
 SG_ PCS2_pcsci_pwm_xbar_CP_LATCH_OC m37 : 44|1@1+ (1,0) [0|0] "" Vector__XXX
 SG_ PCS2_pcs2_pwm_xbar_DCDCA_I_TANK m35 : 45|1@1+ (1,0) [0|0] "" Vector__XXX
 SG_ PCS2_pcsci_pwm_xbar_CP_RESERVED m37 : 45|1@1+ (1,0) [0|0] "" Vector__XXX
 SG_ PCS2_mfg_ac_line_LUT_is_committed m13 : 46|1@1+ (1,0) [0|0] "" Vector__XXX
 SG_ PCS2_pcs2_pwm_xbar_DCDCB_I_TANK m35 : 46|1@1+ (1,0) [0|0] "" Vector__XXX
 SG_ PCS2_pcs2lite_pwm_xbar_DCDCB_I_TANK m36 : 46|1@1+ (1,0) [0|0] "" Vector__XXX
 SG_ PCS2_pcsci_pwm_xbar_DCDCB_I_TANK m37 : 46|1@1+ (1,0) [0|0] "" Vector__XXX
 SG_ PCS2_mfgFuncTestResult m12 : 47|14@1- (0.01,0) [0|0] "" Vector__XXX
 SG_ PCS2_mfg_ac_tank_LUT_is_committed m13 : 47|1@1+ (1,0) [0|0] "" Vector__XXX
 SG_ PCS2_pcs2_pwm_xbar_DCDCB_TANK_ZCD m35 : 47|1@1+ (1,0) [0|0] "" Vector__XXX
 SG_ PCS2_IONVMM_ServerState m4 : 48|3@1+ (1,0) [0|0] "" Vector__XXX
 SG_ PCS2_acGndNVrms m128 : 48|10@1+ (0.5,0) [0|0] "" Vector__XXX
 SG_ PCS2_acSurgeCurrentLimit m147 : 48|10@1+ (0.1,0) [0|0] "" Vector__XXX
 SG_ PCS2_bmsLimitDeratingFactor m148 : 48|7@1+ (0.01,0) [0|0] "" Vector__XXX
 SG_ PCS2_cycloATankMagInductance m137 : 48|15@1+ (0.1,0) [0|0] "" Vector__XXX
 SG_ PCS2_cycloBTankMagInductance m193 : 48|15@1+ (0.1,0) [0|0] "" Vector__XXX
 SG_ PCS2_cycloChargingCurrentCommandReactive m139 : 48|10@1+ (0.1,0) [0|0] "" Vector__XXX
 SG_ PCS2_dcdcAHalfBusCompensationPiOutputMin_1s m7 : 48|7@1- (1,0) [0|0] "" Vector__XXX
 SG_ PCS2_dcdcBHalfBusCompensationPiOutputMin_1s m68 : 48|7@1- (1,0) [0|0] "" Vector__XXX
 SG_ PCS2_hvToAcVoltageRatioDeratingFactor m149 : 48|7@1+ (0.01,0) [0|0] "" Vector__XXX
 SG_ PCS2_lite_BuckBoostInductance m38 : 48|10@1+ (0.05,0) [0|0] "" Vector__XXX
 SG_ PCS2_lite_buck_duty_max_10s m32 : 48|7@1+ (0.01,0) [0|0] "" Vector__XXX
 SG_ PCS2_mfgFuncTestIOXWrActual m15 : 48|16@1+ (1,0) [0|0] "" Vector__XXX
 SG_ PCS2_mfg_dc_tank_LUT_is_committed m13 : 48|1@1+ (1,0) [0|0] "" Vector__XXX
 SG_ PCS2_pcs2_pwm_xbar_L1N_CMPSS_OC m35 : 48|1@1+ (1,0) [0|0] "" Vector__XXX
 SG_ PCS2_pcs2lite_pwm_xbar_L1N_CMPSS_OC m36 : 48|1@1+ (1,0) [0|0] "" Vector__XXX
 SG_ PCS2_phase_diff_pre_relay_L1N_L3N m141 : 48|8@1+ (1,0) [0|0] "" Vector__XXX
 SG_ PCS2_dcdcALvCurrentEstimated m2 : 49|13@1- (0.1,0) [0|0] "" Vector__XXX
 SG_ PCS2_dcdcBLvCurrentEstimated m65 : 49|13@1- (0.1,0) [0|0] "" Vector__XXX
 SG_ PCS2_mfg_dcdcx_LUT_is_committed m13 : 49|1@1+ (1,0) [0|0] "" Vector__XXX
 SG_ PCS2_pcs2_pwm_xbar_CYCLOB_TANK_ZCD m35 : 49|1@1+ (1,0) [0|0] "" Vector__XXX
 SG_ PCS2_pcs2lite_pwm_xbar_CYCLOA_TANK_ZCD m36 : 49|1@1+ (1,0) [0|0] "" Vector__XXX
 SG_ PCS2_cycloABlockedReason m135 : 50|3@1+ (1,0) [0|0] "" Vector__XXX
 SG_ PCS2_cycloA_tank_zcd_measured_freq_min_1s m156 : 50|14@1+ (0.1,150) [0|0] "" Vector__XXX
 SG_ PCS2_cycloB_tank_zcd_measured_freq_min_1s m203 : 50|14@1+ (0.1,150) [0|0] "" Vector__XXX
 SG_ PCS2_pcs2_pwm_xbar_L2N_CMPSS_OC m35 : 50|1@1+ (1,0) [0|0] "" Vector__XXX
 SG_ PCS2_pcs2lite_pwm_xbar_L2N_CMPSS_OC m36 : 50|1@1+ (1,0) [0|0] "" Vector__XXX
 SG_ PCS2_BuckBoostState m4 : 51|3@1+ (1,0) [0|0] "" Vector__XXX
 SG_ PCS2_dcdcAHvBottomVoltage m0 : 51|13@1+ (0.1,0) [0|0] "" Vector__XXX
 SG_ PCS2_dcdcBHvBottomVoltage m64 : 51|13@1+ (0.1,0) [0|0] "" Vector__XXX
 SG_ PCS2_dcdcLvVoltageMax_10s m66 : 51|13@1+ (0.01,0) [0|0] "" Vector__XXX
 SG_ PCS2_pcs2_pwm_xbar_L3N_CMPSS_OC m35 : 51|1@1+ (1,0) [0|0] "" Vector__XXX
 SG_ PCS2_pcs2lite_pwm_xbar_L3N_CMPSS_OC m36 : 51|1@1+ (1,0) [0|0] "" Vector__XXX
 SG_ PCS2_cyclo_A_ln_device_temp m144 : 52|11@1+ (0.1,0) [0|0] "" Vector__XXX
 SG_ PCS2_cyclo_A_ln_device_temp_max m145 : 52|11@1+ (0.1,0) [0|0] "" Vector__XXX
 SG_ PCS2_cyclo_B_ln_device_temp m196 : 52|11@1+ (0.1,0) [0|0] "" Vector__XXX
 SG_ PCS2_cyclo_B_ln_device_temp_max m197 : 52|11@1+ (0.1,0) [0|0] "" Vector__XXX
 SG_ PCS2_mfgFuncTestIOXWriteRetry m14 : 52|10@1+ (1,0) [0|0] "" Vector__XXX
 SG_ PCS2_pcs2_pwm_xbar_LN_OC m35 : 52|1@1+ (1,0) [0|0] "" Vector__XXX
 SG_ PCS2_pcs2lite_pwm_xbar_LN_OC m36 : 52|1@1+ (1,0) [0|0] "" Vector__XXX
 SG_ PCS2_L1L2_pllLocked m133 : 53|1@1+ (1,0) [0|0] "" Vector__XXX
 SG_ PCS2_L1N_pllLocked m132 : 53|1@1+ (1,0) [0|0] "" Vector__XXX
 SG_ PCS2_cycloBBlockedReason m135 : 53|3@1+ (1,0) [0|0] "" Vector__XXX
 SG_ PCS2_dcOffsetL2L3Voltage m204 : 53|9@1- (4,0) [0|0] "" Vector__XXX
 SG_ PCS2_dcdc_CoolantOutTemp m81 : 53|11@1- (0.15,70.05) [0|0] "" Vector__XXX
 SG_ PCS2_pcs2_pwm_xbar_CYCLOA_COMBINEDY m35 : 53|1@1+ (1,0) [0|0] "" Vector__XXX
 SG_ PCS2_pcs2lite_pwm_xbar_CYCLOA_COMBINEDY m36 : 53|1@1+ (1,0) [0|0] "" Vector__XXX
 SG_ PCS2_L1L3_pllLocked m133 : 54|1@1+ (1,0) [0|0] "" Vector__XXX
 SG_ PCS2_L2N_pllLocked m132 : 54|1@1+ (1,0) [0|0] "" Vector__XXX
 SG_ PCS2_dcdcALvModelTemp m11 : 54|9@1- (1,106) [0|0] "" Vector__XXX
 SG_ PCS2_dcdcBLvModelTemp m72 : 54|9@1- (1,106) [0|0] "" Vector__XXX
 SG_ PCS2_lite_dcdc_hvTempIrrational m85 : 54|1@1+ (1,0) [0|0] "" Vector__XXX
 SG_ PCS2_pcs2_pwm_xbar_CYCLOB_COMBINEDY m35 : 54|1@1+ (1,0) [0|0] "" Vector__XXX
 SG_ PCS2_pcs2lite_pwm_xbar_BUCK_BOOST_OV m36 : 54|1@1+ (1,0) [0|0] "" Vector__XXX
 SG_ PCS2_L2L3_pllLocked m133 : 55|1@1+ (1,0) [0|0] "" Vector__XXX
 SG_ PCS2_L3N_pllLocked m132 : 55|1@1+ (1,0) [0|0] "" Vector__XXX
 SG_ PCS2_dcdcB_hvTempIrrational m88 : 55|1@1+ (1,0) [0|0] "" Vector__XXX
 SG_ PCS2_lite_dcac_ac3TempIrrational m84 : 55|1@1+ (1,0) [0|0] "" Vector__XXX
 SG_ PCS2_pcs2_pwm_xbar_DCDCA_COMBINEDY m35 : 55|1@1+ (1,0) [0|0] "" Vector__XXX
 SG_ PCS2_pcs2lite_pwm_xbar_DCAC_GDPS_COMBINEDY m36 : 55|1@1+ (1,0) [0|0] "" Vector__XXX
 SG_ PCS2_acManagerOperatingMode m135 : 56|4@1+ (1,0) [0|0] "" Vector__XXX
 SG_ PCS2_baseCurrentLimitDeratingFactor m149 : 56|7@1+ (0.01,0) [0|0] "" Vector__XXX
 SG_ PCS2_dcdcAHalfBusCompensationPiOutputMax_1s m7 : 56|7@1- (1,0) [0|0] "" Vector__XXX
 SG_ PCS2_dcdcBHalfBusCompensationPiOutputMax_1s m68 : 56|7@1- (1,0) [0|0] "" Vector__XXX
 SG_ PCS2_lite_buck_boost_cbc_leakybucket m32 : 56|8@1+ (0.1,0) [0|0] "" Vector__XXX
 SG_ PCS2_pcs2_pwm_xbar_DCDCB_COMBINEDY m35 : 56|1@1+ (1,0) [0|0] "" Vector__XXX
 SG_ PCS2_pcs2lite_pwm_xbar_DCDCB_COMBINEDY m36 : 56|1@1+ (1,0) [0|0] "" Vector__XXX
 SG_ PCS2_pcsci_pwm_xbar_DCDCB_COMBINEDY m37 : 56|1@1+ (1,0) [0|0] "" Vector__XXX
 SG_ PCS2_phase_diff_pre_relay_L2N_L3N m141 : 56|8@1+ (1,0) [0|0] "" Vector__XXX
 SG_ PCS2_pcs2_pwm_xbar_TEMPSENSE m35 : 57|1@1+ (1,0) [0|0] "" Vector__XXX
 SG_ PCS2_pcs2lite_pwm_xbar_BUCK_BOOST_UV m36 : 57|1@1+ (1,0) [0|0] "" Vector__XXX
 SG_ PCS2_pcs2_pwm_xbar_HVDC_OC m35 : 58|1@1+ (1,0) [0|0] "" Vector__XXX
 SG_ PCS2_pcs2lite_pwm_xbar_HVDC_OC m36 : 58|1@1+ (1,0) [0|0] "" Vector__XXX
 SG_ PCS2_pcsci_pwm_xbar_HVDC_OC m37 : 58|1@1+ (1,0) [0|0] "" Vector__XXX
 SG_ PCS2_pcs2_pwm_xbar_LV_BUS_OV_OR_UV m35 : 59|1@1+ (1,0) [0|0] "" Vector__XXX
 SG_ PCS2_pcs2lite_pwm_xbar_LV_BUS_OV_OR_UV m36 : 59|1@1+ (1,0) [0|0] "" Vector__XXX
 SG_ PCS2_pcsci_pwm_xbar_LV_BUS_OV_OR_UV m37 : 59|1@1+ (1,0) [0|0] "" Vector__XXX
 SG_ PCS2_legHardTiedToNeutral m135 : 60|2@1+ (1,0) [0|0] "" Vector__XXX
 SG_ PCS2_pcs2_pwm_xbar_HV_BUS_OV_OR_UV m35 : 60|1@1+ (1,0) [0|0] "" Vector__XXX
 SG_ PCS2_pcs2lite_pwm_xbar_HV_BUS_OV_OR_UV m36 : 60|1@1+ (1,0) [0|0] "" Vector__XXX
 SG_ PCS2_pcsci_pwm_xbar_HV_BUS_OV_OR_UV m37 : 60|1@1+ (1,0) [0|0] "" Vector__XXX
 SG_ PCS2_mfgFuncTestTopBoardEnable m12 : 61|1@1+ (1,0) [0|0] "" Vector__XXX
 SG_ PCS2_pcs2_pwm_xbar_HV_BATT_OV_OR_UV m35 : 61|1@1+ (1,0) [0|0] "" Vector__XXX
 SG_ PCS2_latchedLineConfiguration m135 : 62|2@1+ (1,0) [0|0] "" Vector__XXX
 SG_ PCS2_mfgFuncTestBottomBoardEnable m12 : 62|1@1+ (1,0) [0|0] "" Vector__XXX
 SG_ PCS2_dcdcAThermalLimited m11 : 63|1@1+ (1,0) [0|0] "" Vector__XXX
 SG_ PCS2_dcdcBThermalLimited m72 : 63|1@1+ (1,0) [0|0] "" Vector__XXX
 SG_ PCS2_mfgFuncTestVoltageEmuMeasEnable m12 : 63|1@1+ (1,0) [0|0] "" Vector__XXX

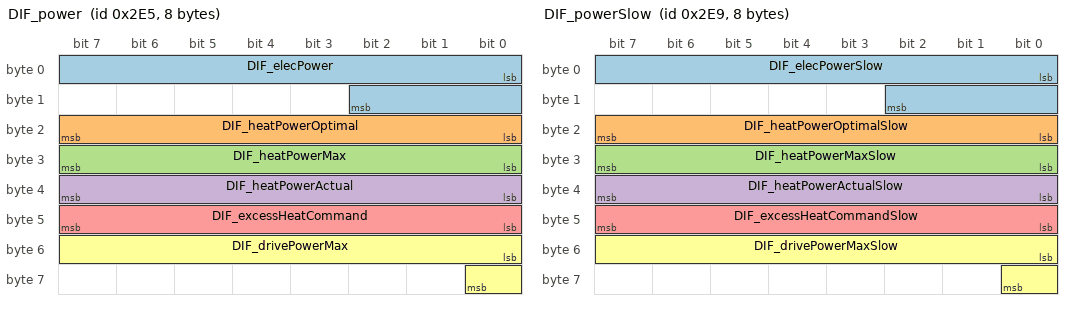
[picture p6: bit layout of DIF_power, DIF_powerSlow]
BO_ 741 DIF_power: 8 Vector__XXX
 SG_ DIF_elecPower : 0|11@1- (0.5,0) [0|0] "" Vector__XXX
 SG_ DIF_heatPowerOptimal : 16|8@1+ (0.08,0) [0|0] "" Vector__XXX
 SG_ DIF_heatPowerMax : 24|8@1+ (0.08,0) [0|0] "" Vector__XXX
 SG_ DIF_heatPowerActual : 32|8@1+ (0.08,0) [0|0] "" Vector__XXX
 SG_ DIF_excessHeatCommand : 40|8@1+ (0.08,0) [0|0] "" Vector__XXX
 SG_ DIF_drivePowerMax : 48|9@1+ (1,0) [0|0] "" Vector__XXX

BO_ 744 EPBR_status: 8 Vector__XXX
 SG_ EPBR_systemStatus : 0|4@1+ (1,0) [0|0] "" Vector__XXX
 SG_ EPBR_freeRollModeStatus : 4|2@1+ (1,0) [0|0] "" Vector__XXX
 SG_ EPBR_driverIsLeaving : 6|1@1+ (1,0) [0|0] "" Vector__XXX
 SG_ EPBR_driverIsLeavingAnySpeed : 7|1@1+ (1,0) [0|0] "" Vector__XXX
 SG_ EPBR_systemCdpAvailable : 8|1@1+ (1,0) [0|0] "" Vector__XXX
 SG_ EPBR_chimeRequest : 9|3@1+ (1,0) [0|0] "" Vector__XXX
 SG_ EPBR_telltale : 12|3@1+ (1,0) [0|0] "" Vector__XXX
 SG_ EPBR_audioCurrentSpikeDetected : 15|1@1+ (1,0) [0|0] "" Vector__XXX
 SG_ EPBR_redundantBrakingEnabled : 16|1@1+ (1,0) [0|0] "" Vector__XXX
 SG_ EPBR_summonEnabled : 17|1@1+ (1,0) [0|0] "" Vector__XXX
 SG_ EPBR_brakeLight : 18|1@1+ (1,0) [0|0] "" Vector__XXX
 SG_ EPBR_epbConfigMismatch : 19|1@1+ (1,0) [0|0] "" Vector__XXX
 SG_ EPBR_brakeConfirmedPressed : 20|1@1+ (1,0) [0|0] "" Vector__XXX
 SG_ EPBR_requestUserConfirmation : 21|1@1+ (1,0) [0|0] "" Vector__XXX
 SG_ EPBR_uiWinchModeMiscBlocking : 22|1@1+ (1,0) [0|0] "" Vector__XXX
 SG_ EPBR_winchModeActive : 23|1@1+ (1,0) [0|0] "" Vector__XXX
 SG_ EPBR_updateMode : 24|1@1+ (1,0) [0|0] "" Vector__XXX
 SG_ EPBR_winchModePermissive : 25|1@1+ (1,0) [0|0] "" Vector__XXX
 SG_ EPBR_winchModePending : 26|1@1+ (1,0) [0|0] "" Vector__XXX
 SG_ EPBR_cdpRequest : 27|1@1+ (1,0) [0|0] "" Vector__XXX
 SG_ EPBR_uiParkAvailable : 28|2@1+ (1,0) [0|0] "" Vector__XXX
 SG_ EPBR_brakeDiscWipeRequest : 30|2@1+ (1,0) [0|0] "" Vector__XXX
 SG_ EPBR_showUiGearShifter : 32|1@1+ (1,0) [0|0] "" Vector__XXX
 SG_ EPBR_uiWinchModeLvStatus : 33|2@1+ (1,0) [0|0] "" Vector__XXX
 SG_ EPBR_contactorCycleNotNeededForWinchEntry : 35|1@1+ (1,0) [0|0] "" Vector__XXX
 SG_ EPBR_autonomyBehavior : 43|2@1+ (1,0) [0|0] "" Vector__XXX
 SG_ EPBR_showStalkFaultedOnUi : 45|1@1+ (1,0) [0|0] "" Vector__XXX
 SG_ EPBR_espPowerRequest : 46|1@1+ (1,0) [0|0] "" Vector__XXX
 SG_ EPBR_okToPark : 47|1@1+ (1,0) [0|0] "" Vector__XXX
 SG_ EPBR_hornRequest : 48|1@1+ (1,0) [0|0] "" Vector__XXX
 SG_ EPBR_winchModeAvailable : 49|1@1+ (1,0) [0|0] "" Vector__XXX
 SG_ EPBR_bothDisconnected : 50|1@1+ (1,0) [0|0] "" Vector__XXX
 SG_ EPBR_blockDrive : 51|1@1+ (1,0) [0|0] "" Vector__XXX
 SG_ EPBR_statusCounter : 52|4@1+ (1,0) [0|0] "" Vector__XXX
 SG_ EPBR_statusChecksum : 56|8@1+ (1,0) [0|0] "" Vector__XXX

BO_ 745 DIF_powerSlow: 8 Vector__XXX
 SG_ DIF_elecPowerSlow : 0|11@1- (0.5,0) [0|0] "" Vector__XXX
 SG_ DIF_heatPowerOptimalSlow : 16|8@1+ (0.08,0) [0|0] "" Vector__XXX
 SG_ DIF_heatPowerMaxSlow : 24|8@1+ (0.08,0) [0|0] "" Vector__XXX
 SG_ DIF_heatPowerActualSlow : 32|8@1+ (0.08,0) [0|0] "" Vector__XXX
 SG_ DIF_excessHeatCommandSlow : 40|8@1+ (0.08,0) [0|0] "" Vector__XXX
 SG_ DIF_drivePowerMaxSlow : 48|9@1+ (1,0) [0|0] "" Vector__XXX

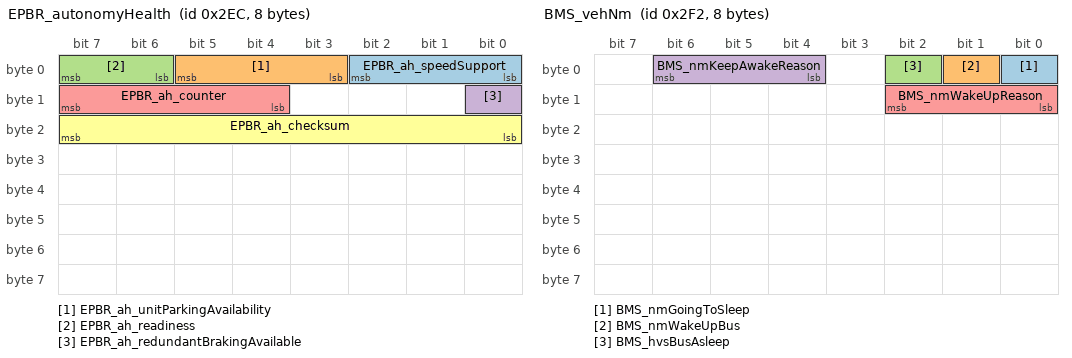
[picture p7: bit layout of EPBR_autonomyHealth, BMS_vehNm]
BO_ 748 EPBR_autonomyHealth: 8 Vector__XXX
 SG_ EPBR_ah_speedSupport : 0|3@1+ (1,0) [0|0] "" Vector__XXX
 SG_ EPBR_ah_unitParkingAvailability : 3|3@1+ (1,0) [0|0] "" Vector__XXX
 SG_ EPBR_ah_readiness : 6|2@1+ (1,0) [0|0] "" Vector__XXX
 SG_ EPBR_ah_redundantBrakingAvailable : 8|1@1+ (1,0) [0|0] "" Vector__XXX
 SG_ EPBR_ah_counter : 12|4@1+ (1,0) [0|0] "" Vector__XXX
 SG_ EPBR_ah_checksum : 16|8@1+ (1,0) [0|0] "" Vector__XXX

BO_ 753 VCFRONT_eFuseDebugStatus: 8 Vector__XXX
 SG_ VCFRONT_eFuseDebugStatusIndex M : 0|5@1+ (1,0) [0|0] "" Vector__XXX
 SG_ VCFRONT_mcuAudioState m18 : 5|1@1+ (1,0) [0|0] "" Vector__XXX
 SG_ VCFRONT_mcuLogicState m11 : 5|1@1+ (1,0) [0|0] "" Vector__XXX
 SG_ VCFRONT_pump1AndFanState m14 : 5|1@1+ (1,0) [0|0] "" Vector__XXX
 SG_ VCFRONT_mcuAudioFault m18 : 6|1@1+ (1,0) [0|0] "" Vector__XXX
 SG_ VCFRONT_mcuLogicFault m11 : 6|1@1+ (1,0) [0|0] "" Vector__XXX
 SG_ VCFRONT_pump1AndFanCurrent m14 : 6|16@1+ (0.05,0) [0|0] "" Vector__XXX
 SG_ VCFRONT_EPAS3PState m4 : 8|2@1+ (1,0) [0|0] "" Vector__XXX
 SG_ VCFRONT_EPAS3SState m5 : 8|2@1+ (1,0) [0|0] "" Vector__XXX
 SG_ VCFRONT_ESPMotorState m6 : 8|2@1+ (1,0) [0|0] "" Vector__XXX
 SG_ VCFRONT_ESPValveState m7 : 8|2@1+ (1,0) [0|0] "" Vector__XXX
 SG_ VCFRONT_PCSState m2 : 8|2@1+ (1,0) [0|0] "" Vector__XXX
 SG_ VCFRONT_autopilot1State m8 : 8|2@1+ (1,0) [0|0] "" Vector__XXX
 SG_ VCFRONT_autopilot2State m9 : 8|2@1+ (1,0) [0|0] "" Vector__XXX
 SG_ VCFRONT_chargedIBSAmpHours m17 : 8|16@1+ (1,0) [0|0] "" Vector__XXX
 SG_ VCFRONT_eFuseLockoutVoltage m16 : 8|12@1+ (0.005443676098,0) [0|0] "" Vector__XXX
 SG_ VCFRONT_headlampLeftState m12 : 8|1@1+ (1,0) [0|0] "" Vector__XXX
 SG_ VCFRONT_iBoosterState m3 : 8|2@1+ (1,0) [0|0] "" Vector__XXX
 SG_ VCFRONT_leftControllerState m1 : 8|2@1+ (1,0) [0|0] "" Vector__XXX
 SG_ VCFRONT_mcuAudioCurrent m18 : 8|10@1+ (0.025,0) [0|0] "" Vector__XXX
 SG_ VCFRONT_mcuLogicCurrent m11 : 8|10@1+ (0.027,0) [0|0] "" Vector__XXX
 SG_ VCFRONT_railA_12v m15 : 8|12@1+ (0.005443676098,0) [0|0] "" Vector__XXX
 SG_ VCFRONT_rightControllerState m0 : 8|2@1+ (1,0) [0|0] "" Vector__XXX
 SG_ VCFRONT_sleepBypassState m10 : 8|1@1+ (1,0) [0|0] "" Vector__XXX
 SG_ VCFRONT_vbatFusedHighState m13 : 8|1@1+ (1,0) [0|0] "" Vector__XXX
 SG_ VCFRONT_headlampLeftFault m12 : 9|1@1+ (1,0) [0|0] "" Vector__XXX
 SG_ VCFRONT_sleepBypassFault m10 : 9|1@1+ (1,0) [0|0] "" Vector__XXX
 SG_ VCFRONT_vbatFusedHighFault m13 : 9|1@1+ (1,0) [0|0] "" Vector__XXX
 SG_ VCFRONT_EPAS3PFault m4 : 10|1@1+ (1,0) [0|0] "" Vector__XXX
 SG_ VCFRONT_EPAS3SFault m5 : 10|1@1+ (1,0) [0|0] "" Vector__XXX
 SG_ VCFRONT_ESPMotorFault m6 : 10|1@1+ (1,0) [0|0] "" Vector__XXX
 SG_ VCFRONT_ESPValveFault m7 : 10|1@1+ (1,0) [0|0] "" Vector__XXX
 SG_ VCFRONT_PCSFault m2 : 10|1@1+ (1,0) [0|0] "" Vector__XXX
 SG_ VCFRONT_autopilot1Fault m8 : 10|1@1+ (1,0) [0|0] "" Vector__XXX
 SG_ VCFRONT_autopilot2Fault m9 : 10|1@1+ (1,0) [0|0] "" Vector__XXX
 SG_ VCFRONT_headlampLeftCurrent m12 : 10|10@1+ (0.027,0) [0|0] "" Vector__XXX
 SG_ VCFRONT_iBoosterFault m3 : 10|1@1+ (1,0) [0|0] "" Vector__XXX
 SG_ VCFRONT_leftControllerFault m1 : 10|1@1+ (1,0) [0|0] "" Vector__XXX
 SG_ VCFRONT_rightControllerFault m0 : 10|1@1+ (1,0) [0|0] "" Vector__XXX
 SG_ VCFRONT_sleepBypassVoltage m10 : 10|16@1+ (0.1,0) [0|0] "" Vector__XXX
 SG_ VCFRONT_vbatFusedSelfTestResult m13 : 10|4@1+ (1,0) [0|0] "" Vector__XXX
 SG_ VCFRONT_EPAS3PSelfTestResult m4 : 11|4@1+ (1,0) [0|0] "" Vector__XXX
 SG_ VCFRONT_EPAS3SSelfTestResult m5 : 11|4@1+ (1,0) [0|0] "" Vector__XXX
 SG_ VCFRONT_ESPMotorSelfTestResult m6 : 11|4@1+ (1,0) [0|0] "" Vector__XXX
 SG_ VCFRONT_autopilot1Temp m8 : 11|11@1+ (0.125,-40) [0|0] "" Vector__XXX
 SG_ VCFRONT_autopilot2Temp m9 : 11|11@1+ (0.125,-40) [0|0] "" Vector__XXX
 SG_ VCFRONT_iBoosterSelfTestResult m3 : 11|4@1+ (1,0) [0|0] "" Vector__XXX
 SG_ VCFRONT_pcsSelfTestResult m2 : 11|4@1+ (1,0) [0|0] "" Vector__XXX
 SG_ VCFRONT_vcleftSelfTestResult m1 : 11|4@1+ (1,0) [0|0] "" Vector__XXX
 SG_ VCFRONT_vcrightSelfTestResult m0 : 11|4@1+ (1,0) [0|0] "" Vector__XXX
 SG_ VCFRONT_ESPValveTemp m7 : 12|11@1+ (0.125,-40) [0|0] "" Vector__XXX
 SG_ VCFRONT_vbatFusedHighTemp m13 : 14|11@1+ (0.125,-40) [0|0] "" Vector__XXX
 SG_ VCFRONT_EPAS3PTemp m4 : 15|11@1+ (0.125,-40) [0|0] "" Vector__XXX
 SG_ VCFRONT_EPAS3STemp m5 : 15|11@1+ (0.125,-40) [0|0] "" Vector__XXX
 SG_ VCFRONT_ESPMotorTemp m6 : 15|11@1+ (0.125,-40) [0|0] "" Vector__XXX
 SG_ VCFRONT_PCSTemp m2 : 15|11@1+ (0.125,-40) [0|0] "" Vector__XXX
 SG_ VCFRONT_iBoosterTemp m3 : 15|11@1+ (0.125,-40) [0|0] "" Vector__XXX
 SG_ VCFRONT_leftControllerTemp m1 : 15|11@1+ (0.125,-40) [0|0] "" Vector__XXX
 SG_ VCFRONT_rightControllerTemp m0 : 15|11@1+ (0.125,-40) [0|0] "" Vector__XXX
 SG_ VCFRONT_headlampLeftVoltage m12 : 20|8@1+ (0.1,0) [0|0] "" Vector__XXX
 SG_ VCFRONT_railB_12v m15 : 20|12@1+ (0.005443676098,0) [0|0] "" Vector__XXX
 SG_ VCFRONT_pump1AndFanVoltage m14 : 22|12@1+ (0.1,0) [0|0] "" Vector__XXX
 SG_ VCFRONT_ChargePumpVoltage m16 : 24|16@1+ (0.005443676098,0) [0|0] "" Vector__XXX
 SG_ VCFRONT_dischargedIBSAmpHours m17 : 24|16@1+ (1,0) [0|0] "" Vector__XXX
 SG_ VCFRONT_mcuAudioVoltage m18 : 24|8@1+ (0.1,0) [0|0] "" Vector__XXX
 SG_ VCFRONT_mcuLogicVoltage m11 : 24|8@1+ (0.1,0) [0|0] "" Vector__XXX
 SG_ VCFRONT_sleepBypassCurrent m10 : 26|16@1+ (0.1,0) [0|0] "" Vector__XXX
 SG_ VCFRONT_autopilot1Voltage m8 : 27|16@1+ (0.1,0) [0|0] "" Vector__XXX
 SG_ VCFRONT_autopilot2Voltage m9 : 27|16@1+ (0.1,0) [0|0] "" Vector__XXX
 SG_ VCFRONT_ESPValveVoltage m7 : 28|16@1+ (0.1,0) [0|0] "" Vector__XXX
 SG_ VCFRONT_headlampRightState m12 : 28|1@1+ (1,0) [0|0] "" Vector__XXX
 SG_ VCFRONT_headlampRightFault m12 : 29|1@1+ (1,0) [0|0] "" Vector__XXX
 SG_ VCFRONT_headlampRightCurrent m12 : 30|10@1+ (0.027,0) [0|0] "" Vector__XXX
 SG_ VCFRONT_vbatFusedHighVoltage m13 : 30|16@1+ (0.1,0) [0|0] "" Vector__XXX
 SG_ VCFRONT_EPAS3PVoltage m4 : 31|9@1+ (0.1,0) [0|0] "" Vector__XXX
 SG_ VCFRONT_EPAS3SVoltage m5 : 31|14@1+ (0.1,0) [0|0] "" Vector__XXX
 SG_ VCFRONT_ESPMotorVoltage m6 : 31|14@1+ (0.1,0) [0|0] "" Vector__XXX
 SG_ VCFRONT_PCSVoltage m2 : 31|14@1+ (0.1,0) [0|0] "" Vector__XXX
 SG_ VCFRONT_iBoosterVoltage m3 : 31|9@1+ (0.1,0) [0|0] "" Vector__XXX
 SG_ VCFRONT_leftControllerVoltage m1 : 31|14@1+ (0.1,0) [0|0] "" Vector__XXX
 SG_ VCFRONT_rightControllerVoltage m0 : 31|14@1+ (0.1,0) [0|0] "" Vector__XXX
 SG_ VCFRONT_railA_5v m15 : 32|12@1+ (0.005443676098,0) [0|0] "" Vector__XXX
 SG_ VCFRONT_pump2AndAirCompState m14 : 34|1@1+ (1,0) [0|0] "" Vector__XXX
 SG_ VCFRONT_pump2AndAirCompCurrent m14 : 35|10@1+ (0.05,0) [0|0] "" Vector__XXX
 SG_ VCFRONT_IBSUnfilteredTemperature m17 : 40|16@1- (0.01,0) [0|0] "" Vector__XXX
 SG_ VCFRONT_headlampLeftCurrentFiltered m16 : 40|10@1+ (0.027,0) [0|0] "" Vector__XXX
 SG_ VCFRONT_headlampRightVoltage m12 : 40|8@1+ (0.1,0) [0|0] "" Vector__XXX
 SG_ VCFRONT_mcuGraphicsState m18 : 40|1@1+ (1,0) [0|0] "" Vector__XXX
 SG_ VCFRONT_mcuGraphicsFault m18 : 41|1@1+ (1,0) [0|0] "" Vector__XXX
 SG_ VCFRONT_mcuGraphicsCurrent m18 : 42|16@1+ (0.1,0) [0|0] "" Vector__XXX
 SG_ VCFRONT_autopilot1Current m8 : 43|10@1+ (0.044,0) [0|0] "" Vector__XXX
 SG_ VCFRONT_autopilot2Current m9 : 43|10@1+ (0.044,0) [0|0] "" Vector__XXX
 SG_ VCFRONT_ESPValveCurrent m7 : 44|16@1+ (0.01,0) [0|0] "" Vector__XXX
 SG_ VCFRONT_railB_5v m15 : 44|12@1+ (0.005443676098,0) [0|0] "" Vector__XXX
 SG_ VCFRONT_vbatFusedHighCurrent m13 : 46|16@1+ (0.1,0) [0|0] "" Vector__XXX
 SG_ VCFRONT_EPAS3PCurrent m4 : 47|14@1+ (0.1,0) [0|0] "" Vector__XXX
 SG_ VCFRONT_EPAS3SCurrent m5 : 47|14@1+ (0.1,0) [0|0] "" Vector__XXX
 SG_ VCFRONT_ESPMotorCurrent m6 : 47|14@1+ (0.1,0) [0|0] "" Vector__XXX
 SG_ VCFRONT_iBoosterCurrent m3 : 47|14@1+ (0.1,0) [0|0] "" Vector__XXX
 SG_ VCFRONT_leftControllerCurrent m1 : 47|14@1+ (0.1,0) [0|0] "" Vector__XXX
 SG_ VCFRONT_rightControllerCurrent m0 : 47|14@1+ (0.1,0) [0|0] "" Vector__XXX
 SG_ VCFRONT_headlampLeftTemperature m12 : 48|8@1+ (1,-40) [0|0] "" Vector__XXX
 SG_ VCFRONT_headlampRightCurrentFiltered m16 : 50|10@1+ (0.027,0) [0|0] "" Vector__XXX
 SG_ VCFRONT_pump2AndAirCompVoltage m14 : 51|12@1+ (0.1,0) [0|0] "" Vector__XXX
 SG_ VCFRONT_headlampRightTemperature m12 : 56|8@1+ (1,-40) [0|0] "" Vector__XXX

BO_ 754 BMS_vehNm: 8 Vector__XXX
 SG_ BMS_nmGoingToSleep : 0|1@1+ (1,0) [0|0] "" Vector__XXX
 SG_ BMS_nmWakeUpBus : 1|1@1+ (1,0) [0|0] "" Vector__XXX
 SG_ BMS_hvsBusAsleep : 2|1@1+ (1,0) [0|0] "" Vector__XXX
 SG_ BMS_nmKeepAwakeReason : 4|3@1+ (1,0) [0|0] "" Vector__XXX
 SG_ BMS_nmWakeUpReason : 8|3@1+ (1,0) [0|0] "" Vector__XXX

BO_ 755 UI_hvacRequest: 8 Vector__XXX
 SG_ UI_hvacReqTempSetpointLeft : 0|5@1+ (0.5,15) [0|0] "" Vector__XXX
 SG_ UI_hvacReqAutoBlowerLevel : 5|3@1+ (1,0) [0|0] "" Vector__XXX
 SG_ UI_hvacReqTempSetpointRight : 8|5@1+ (0.5,15) [0|0] "" Vector__XXX
 SG_ UI_hvacReqAirDistributionMode : 13|3@1+ (1,0) [0|0] "" Vector__XXX
 SG_ UI_hvacReqBlowerSegment : 16|4@1+ (1,0) [0|0] "" Vector__XXX
 SG_ UI_hvacReqRecirc : 20|2@1+ (1,0) [0|0] "" Vector__XXX
 SG_ UI_hvacReqACDisable : 22|2@1+ (1,0) [0|0] "" Vector__XXX
 SG_ UI_hvacDefogState : 24|2@1+ (1,0) [0|0] "" Vector__XXX
 SG_ UI_hvacReqUserPowerState : 26|3@1+ (1,0) [0|0] "" Vector__XXX
 SG_ UI_hvacReqSecondRowState : 29|3@1+ (1,0) [0|0] "" Vector__XXX
 SG_ UI_hvacUseModeledDuctTemp : 32|1@1+ (1,0) [0|0] "" Vector__XXX
 SG_ UI_hvacReqKeepClimateOn : 33|2@1+ (1,0) [0|0] "" Vector__XXX
 SG_ UI_hvacReqBioWeaponDefMode : 35|1@1+ (1,0) [0|0] "" Vector__XXX
 SG_ UI_hvacLatchPassengerPresent : 39|1@1+ (1,0) [0|0] "" Vector__XXX
 SG_ UI_enableHvacControlsFeatures1 : 44|1@1+ (1,0) [0|0] "" Vector__XXX
 SG_ UI_enableHvacNotifications : 45|1@1+ (1,0) [0|0] "" Vector__XXX
 SG_ UI_hvacPhoneCallAirFlowAdjustEnabled : 46|1@1+ (1,0) [0|0] "" Vector__XXX
 SG_ UI_enableHvacVOCPurgeRoutine : 47|1@1+ (1,0) [0|0] "" Vector__XXX
 SG_ UI_enableCustomerTHSAlerts : 53|1@1+ (1,0) [0|0] "" Vector__XXX
 SG_ UI_evapDryingSelectiveEnable : 54|1@1+ (1,0) [0|0] "" Vector__XXX
 SG_ UI_enableHvacWeatherDataBasedHumidityControls : 55|1@1+ (1,0) [0|0] "" Vector__XXX
 SG_ UI_hvacReqTempSetpointCOP : 56|2@1+ (1,0) [0|0] "" Vector__XXX
 SG_ UI_hvacClimateNudgeStatus : 58|3@1+ (1,0) [0|0] "" Vector__XXX
 SG_ UI_enableHvacControlsFeatures2 : 61|1@1+ (1,0) [0|0] "" Vector__XXX
 SG_ UI_enableHvacAPFoggingMonitor : 62|1@1+ (1,0) [0|0] "" Vector__XXX
 SG_ UI_enableHvacLimpMode : 63|1@1+ (1,0) [0|0] "" Vector__XXX

BO_ 761 VCSEC_additionalAuthInfo: 8 Vector__XXX
 SG_ VCSEC_algoUsedForSummonRange0 m1 : 0|1@1+ (1,0) [0|0] "" Vector__XXX
 SG_ VCSEC_algoUsedForSummonRange1 m2 : 0|1@1+ (1,0) [0|0] "" Vector__XXX
 SG_ VCSEC_algoUsedForSummonRange2 m3 : 0|1@1+ (1,0) [0|0] "" Vector__XXX
 SG_ VCSEC_activeKeyDebug : 2|5@1+ (1,0) [0|0] "" Vector__XXX
 SG_ VCSEC_bleChannelDisconnected : 7|4@1+ (1,0) [0|0] "" Vector__XXX
 SG_ VCSEC_bleDisconnectionReason : 11|8@1+ (1,0) [0|0] "" Vector__XXX
 SG_ VCSEC_bleConnetionAttemptWLEntry : 19|5@1+ (1,0) [0|0] "" Vector__XXX
 SG_ VCSEC_activeKeyReason m0 : 24|3@1+ (1,0) [0|0] "" Vector__XXX
 SG_ VCSEC_AdditionalAuthInfoIndex M : 27|3@1+ (1,0) [0|0] "" Vector__XXX
 SG_ VCSEC_BLEDeviceWithinSummonRange m4 : 32|32@1+ (1,0) [0|0] "" Vector__XXX
 SG_ VCSEC_NFCAuthFromBPillarFormFactor m5 : 32|3@1+ (1,0) [0|0] "" Vector__XXX
 SG_ VCSEC_activeKeySHA1 m0 : 32|32@1+ (1,0) [0|0] "" Vector__XXX
 SG_ VCSEC_keyWithinSummonRange0 m1 : 32|32@1+ (1,0) [0|0] "" Vector__XXX
 SG_ VCSEC_keyWithinSummonRange1 m2 : 32|32@1+ (1,0) [0|0] "" Vector__XXX
 SG_ VCSEC_keyWithinSummonRange2 m3 : 32|32@1+ (1,0) [0|0] "" Vector__XXX
 SG_ VCSEC_NFCAuthFromCenterConsoleFormFactor m5 : 35|3@1+ (1,0) [0|0] "" Vector__XXX

BO_ 768 BMS_info: 8 Vector__XXX
 SG_ BMS_infoIndex M : 0|8@1+ (1,0) [0|0] "" Vector__XXX
 SG_ BMS_appGitHash m17 : 8|56@1+ (1,0) [0|0] "" Vector__XXX
 SG_ BMS_bootGitHash m18 : 8|56@1+ (1,0) [0|0] "" Vector__XXX
 SG_ BMS_bootUdsProtoVersion m20 : 8|8@1+ (1,0) [0|0] "" Vector__XXX
 SG_ BMS_buildType m10 : 8|3@1+ (1,0) [0|0] "" Vector__XXX
 SG_ BMS_platformType m13 : 8|8@1+ (1,0) [0|0] "" Vector__XXX
 SG_ BMS_buildConfigId m10 : 16|16@1+ (1,0) [0|0] "" Vector__XXX
 SG_ BMS_pcbaId m11 : 16|8@1+ (1,0) [0|0] "" Vector__XXX
 SG_ BMS_assemblyId m11 : 24|8@1+ (1,0) [0|0] "" Vector__XXX
 SG_ BMS_appCrc m13 : 32|32@1+ (1,0) [0|0] "" Vector__XXX
 SG_ BMS_bootCrc m20 : 32|32@1+ (1,0) [0|0] "" Vector__XXX
 SG_ BMS_hardwareId m10 : 32|16@1+ (1,0) [0|0] "" Vector__XXX
 SG_ BMS_usageId m11 : 32|16@1+ (1,0) [0|0] "" Vector__XXX
 SG_ BMS_componentId m10 : 48|16@1+ (1,0) [0|0] "" Vector__XXX
 SG_ BMS_subUsageId m11 : 48|16@1+ (1,0) [0|0] "" Vector__XXX

BO_ 769 VCFRONT_info: 8 Vector__XXX
 SG_ VCFRONT_infoIndex M : 0|8@1+ (1,0) [0|0] "" Vector__XXX
 SG_ VCFRONT_infoAppCrc m13 : 8|32@1+ (1,0) [0|0] "" Vector__XXX
 SG_ VCFRONT_infoAppGitHash m17 : 8|56@1+ (1,0) [0|0] "" Vector__XXX
 SG_ VCFRONT_infoBootGitHash m18 : 8|56@1+ (1,0) [0|0] "" Vector__XXX
 SG_ VCFRONT_infoBootUdsProtoVersion m20 : 8|16@1+ (1,0) [0|0] "" Vector__XXX
 SG_ VCFRONT_infoBuildType m10 : 8|3@1+ (1,0) [0|0] "" Vector__XXX
 SG_ VCFRONT_infoPcbaId m11 : 8|8@1+ (1,0) [0|0] "" Vector__XXX
 SG_ VCFRONT_infoPlatformType m19 : 8|8@1+ (1,0) [0|0] "" Vector__XXX
 SG_ VCFRONT_infoAssemblyId m11 : 16|8@1+ (1,0) [0|0] "" Vector__XXX
 SG_ VCFRONT_infoBuildConfigId m10 : 16|16@1+ (1,0) [0|0] "" Vector__XXX
 SG_ VCFRONT_infoBootCrc m20 : 24|32@1+ (1,0) [0|0] "" Vector__XXX
 SG_ VCFRONT_infoUsageId m11 : 24|16@1+ (1,0) [0|0] "" Vector__XXX
 SG_ VCFRONT_infoBattPumpAppCRC m32 : 32|32@1+ (1,0) [0|0] "" Vector__XXX
 SG_ VCFRONT_infoFanAppCRC m34 : 32|32@1+ (1,0) [0|0] "" Vector__XXX
 SG_ VCFRONT_infoHardwareId m10 : 32|16@1+ (1,0) [0|0] "" Vector__XXX
 SG_ VCFRONT_infoPtPumpAppCRC m33 : 32|32@1+ (1,0) [0|0] "" Vector__XXX
 SG_ VCFRONT_infoSubcomponent10 m37 : 32|32@1+ (1,0) [0|0] "" Vector__XXX
 SG_ VCFRONT_infoSubcomponent11 m38 : 32|32@1+ (1,0) [0|0] "" Vector__XXX
 SG_ VCFRONT_infoSubcomponent12 m39 : 32|32@1+ (1,0) [0|0] "" Vector__XXX
 SG_ VCFRONT_infoSubcomponent13 m40 : 32|32@1+ (1,0) [0|0] "" Vector__XXX
 SG_ VCFRONT_infoSubcomponent14 m41 : 32|32@1+ (1,0) [0|0] "" Vector__XXX
 SG_ VCFRONT_infoSubcomponent3 m24 : 32|32@1+ (1,0) [0|0] "" Vector__XXX
 SG_ VCFRONT_infoSubcomponent8 m35 : 32|32@1+ (1,0) [0|0] "" Vector__XXX
 SG_ VCFRONT_infoSubcomponent9 m36 : 32|32@1+ (1,0) [0|0] "" Vector__XXX
 SG_ VC_infoHCMLAppCRC m16 : 32|32@1+ (1,0) [0|0] "" Vector__XXX
 SG_ VC_infoHCMRAppCRC m23 : 32|32@1+ (1,0) [0|0] "" Vector__XXX
 SG_ VC_infoWiperAppCRC m31 : 32|32@1+ (1,0) [0|0] "" Vector__XXX
 SG_ VCFRONT_infoSubUsageId m11 : 40|16@1+ (1,0) [0|0] "" Vector__XXX
 SG_ VCFRONT_infoComponentId m10 : 48|16@1+ (1,0) [0|0] "" Vector__XXX

BO_ 770 VCLEFT_info: 8 Vector__XXX
 SG_ VCLEFT_infoIndex M : 0|8@1+ (1,0) [0|0] "" Vector__XXX
 SG_ VCLEFT_infoAppCrc m13 : 8|32@1+ (1,0) [0|0] "" Vector__XXX
 SG_ VCLEFT_infoAppGitHash m17 : 8|56@1+ (1,0) [0|0] "" Vector__XXX
 SG_ VCLEFT_infoBootGitHash m18 : 8|56@1+ (1,0) [0|0] "" Vector__XXX
 SG_ VCLEFT_infoBootUdsProtoVersion m20 : 8|16@1+ (1,0) [0|0] "" Vector__XXX
 SG_ VCLEFT_infoBuildType m10 : 8|3@1+ (1,0) [0|0] "" Vector__XXX
 SG_ VCLEFT_infoPcbaId m11 : 8|8@1+ (1,0) [0|0] "" Vector__XXX
 SG_ VCLEFT_infoPlatformType m19 : 8|8@1+ (1,0) [0|0] "" Vector__XXX
 SG_ VCLEFT_infoAssemblyId m11 : 16|8@1+ (1,0) [0|0] "" Vector__XXX
 SG_ VCLEFT_infoBuildConfigId m10 : 16|16@1+ (1,0) [0|0] "" Vector__XXX
 SG_ VCLEFT_infoBootCrc m20 : 24|32@1+ (1,0) [0|0] "" Vector__XXX
 SG_ VCLEFT_infoUsageId m11 : 24|16@1+ (1,0) [0|0] "" Vector__XXX
 SG_ VCLEFT_infoCBCAppCRC m31 : 32|32@1+ (1,0) [0|0] "" Vector__XXX
 SG_ VCLEFT_infoHardwareId m10 : 32|16@1+ (1,0) [0|0] "" Vector__XXX
 SG_ VCLEFT_infoLUMBARLAppCRC m16 : 32|32@1+ (1,0) [0|0] "" Vector__XXX
 SG_ VCLEFT_infoRGBIPFLAppCRC m38 : 32|32@1+ (1,0) [0|0] "" Vector__XXX
 SG_ VCLEFT_infoRGBIPFRAppCRC m39 : 32|32@1+ (1,0) [0|0] "" Vector__XXX
 SG_ VCLEFT_infoSubcomponent3 m24 : 32|32@1+ (1,0) [0|0] "" Vector__XXX
 SG_ VCLEFT_infoTLCAppCRC m33 : 32|32@1+ (1,0) [0|0] "" Vector__XXX
 SG_ VCLEFT_infoVCUSBAppCRC m32 : 32|32@1+ (1,0) [0|0] "" Vector__XXX
 SG_ VCLEFT_swcAppCRC m23 : 32|32@1+ (1,0) [0|0] "" Vector__XXX
 SG_ VCLEFT_infoSubUsageId m11 : 40|16@1+ (1,0) [0|0] "" Vector__XXX
 SG_ VCLEFT_infoComponentId m10 : 48|16@1+ (1,0) [0|0] "" Vector__XXX

BO_ 771 VCRIGHT_info: 8 Vector__XXX
 SG_ VCRIGHT_infoIndex M : 0|8@1+ (1,0) [0|0] "" Vector__XXX
 SG_ VCRIGHT_infoAppCrc m13 : 8|32@1+ (1,0) [0|0] "" Vector__XXX
 SG_ VCRIGHT_infoAppGitHash m17 : 8|56@1+ (1,0) [0|0] "" Vector__XXX
 SG_ VCRIGHT_infoBootGitHash m18 : 8|56@1+ (1,0) [0|0] "" Vector__XXX
 SG_ VCRIGHT_infoBootUdsProtoVersion m20 : 8|16@1+ (1,0) [0|0] "" Vector__XXX
 SG_ VCRIGHT_infoBuildType m10 : 8|3@1+ (1,0) [0|0] "" Vector__XXX
 SG_ VCRIGHT_infoPcbaId m11 : 8|8@1+ (1,0) [0|0] "" Vector__XXX
 SG_ VCRIGHT_infoPlatformType m19 : 8|8@1+ (1,0) [0|0] "" Vector__XXX
 SG_ VCRIGHT_infoAssemblyId m11 : 16|8@1+ (1,0) [0|0] "" Vector__XXX
 SG_ VCRIGHT_infoBuildConfigId m10 : 16|16@1+ (1,0) [0|0] "" Vector__XXX
 SG_ VCRIGHT_infoBootCrc m20 : 24|32@1+ (1,0) [0|0] "" Vector__XXX
 SG_ VCRIGHT_infoUsageId m11 : 24|16@1+ (1,0) [0|0] "" Vector__XXX
 SG_ VCRIGHT_infoHardwareId m10 : 32|16@1+ (1,0) [0|0] "" Vector__XXX
 SG_ VCRIGHT_infoLUMBARRAppCRC m16 : 32|32@1+ (1,0) [0|0] "" Vector__XXX
 SG_ VCRIGHT_infoSubcomponent3 m24 : 32|32@1+ (1,0) [0|0] "" Vector__XXX
 SG_ VCRIGHT_infoSubcomponent4 m31 : 32|32@1+ (1,0) [0|0] "" Vector__XXX
 SG_ VCRIGHT_infoSubcomponent5 m32 : 32|32@1+ (1,0) [0|0] "" Vector__XXX
 SG_ VCRIGHT_infoSubcomponent6 m33 : 32|32@1+ (1,0) [0|0] "" Vector__XXX
 SG_ VCRIGHT_thsAppCRC m23 : 32|32@1+ (1,0) [0|0] "" Vector__XXX
 SG_ VCRIGHT_infoSubUsageId m11 : 40|16@1+ (1,0) [0|0] "" Vector__XXX
 SG_ VCRIGHT_infoComponentId m10 : 48|16@1+ (1,0) [0|0] "" Vector__XXX

BO_ 772 PMF_alertMatrix1: 8 Vector__XXX
 SG_ PMF_a001_absoluteTorque : 0|1@1+ (1,0) [0|0] "" Vector__XXX
 SG_ PMF_a002_excessiveAccelTorque : 1|1@1+ (1,0) [0|0] "" Vector__XXX
 SG_ PMF_a003_excessiveReversalTorque : 2|1@1+ (1,0) [0|0] "" Vector__XXX
 SG_ PMF_a004_excessiveDecelTorque : 3|1@1+ (1,0) [0|0] "" Vector__XXX
 SG_ PMF_a005_torqueInNeutralOrPark : 4|1@1+ (1,0) [0|0] "" Vector__XXX
 SG_ PMF_a008_memoryError : 7|1@1+ (1,0) [0|0] "" Vector__XXX
 SG_ PMF_a010_diMIA : 9|1@1+ (1,0) [0|0] "" Vector__XXX
 SG_ PMF_a011_phaseCurrentIrrational : 10|1@1+ (1,0) [0|0] "" Vector__XXX
 SG_ PMF_a012_canDataBusA : 11|1@1+ (1,0) [0|0] "" Vector__XXX
 SG_ PMF_a013_canHardwareBusA : 12|1@1+ (1,0) [0|0] "" Vector__XXX
 SG_ PMF_a017_brakeMIA : 16|1@1+ (1,0) [0|0] "" Vector__XXX
 SG_ PMF_a018_encoderIrrational : 17|1@1+ (1,0) [0|0] "" Vector__XXX
 SG_ PMF_a019_statorTempIrrational : 18|1@1+ (1,0) [0|0] "" Vector__XXX
 SG_ PMF_a025_unintendedReset : 24|1@1+ (1,0) [0|0] "" Vector__XXX
 SG_ PMF_a026_diHeartBeatMIA : 25|1@1+ (1,0) [0|0] "" Vector__XXX
 SG_ PMF_a027_torqueEstimationOutOfBounds : 26|1@1+ (1,0) [0|0] "" Vector__XXX
 SG_ PMF_a028_torqueCmdError : 27|1@1+ (1,0) [0|0] "" Vector__XXX
 SG_ PMF_a031_highStackUsage : 30|1@1+ (1,0) [0|0] "" Vector__XXX
 SG_ PMF_a032_registerConfigError : 31|1@1+ (1,0) [0|0] "" Vector__XXX
 SG_ PMF_a033_selfTest : 32|1@1+ (1,0) [0|0] "" Vector__XXX
 SG_ PMF_a034_trqCrossCheck : 33|1@1+ (1,0) [0|0] "" Vector__XXX
 SG_ PMF_a035_udsTransactionInitiated : 34|1@1+ (1,0) [0|0] "" Vector__XXX
 SG_ PMF_a036_preWatchdog : 35|1@1+ (1,0) [0|0] "" Vector__XXX
 SG_ PMF_a037_hvpMIA : 36|1@1+ (1,0) [0|0] "" Vector__XXX
 SG_ PMF_a039_disMIA : 38|1@1+ (1,0) [0|0] "" Vector__XXX
 SG_ PMF_a040_pmMIA : 39|1@1+ (1,0) [0|0] "" Vector__XXX
 SG_ PMF_a042_gtwMIA : 41|1@1+ (1,0) [0|0] "" Vector__XXX
 SG_ PMF_a045_motorMovementDetected : 44|1@1+ (1,0) [0|0] "" Vector__XXX
 SG_ PMF_a053_vcfrontMIA : 52|1@1+ (1,0) [0|0] "" Vector__XXX
 SG_ PMF_a054_uiMIA : 53|1@1+ (1,0) [0|0] "" Vector__XXX
 SG_ PMF_a055_resolver : 54|1@1+ (1,0) [0|0] "" Vector__XXX
 SG_ PMF_a056_canHardwareBusB : 55|1@1+ (1,0) [0|0] "" Vector__XXX
 SG_ PMF_a057_canDataBusB : 56|1@1+ (1,0) [0|0] "" Vector__XXX
 SG_ PMF_a061_DIPMVersionMismatch : 60|1@1+ (1,0) [0|0] "" Vector__XXX
 SG_ PMF_a062_eccError : 61|1@1+ (1,0) [0|0] "" Vector__XXX
 SG_ PMF_a064_torqueIntervention : 63|1@1+ (1,0) [0|0] "" Vector__XXX

BO_ 775 PTC_faultsAndExtras: 8 Vector__XXX
 SG_ PTC_faultLVLow : 1|1@1+ (1,0) [0|0] "" Vector__XXX
 SG_ PTC_faultLVHigh : 2|1@1+ (1,0) [0|0] "" Vector__XXX
 SG_ PTC_faultHVLow : 3|1@1+ (1,0) [0|0] "" Vector__XXX
 SG_ PTC_faultHVHigh : 4|1@1+ (1,0) [0|0] "" Vector__XXX
 SG_ PTC_faultLeftOverCurrent : 5|1@1+ (1,0) [0|0] "" Vector__XXX
 SG_ PTC_faultRightOverCurrent : 6|1@1+ (1,0) [0|0] "" Vector__XXX
 SG_ PTC_faultLeftThermalShutOutlet : 7|1@1+ (1,0) [0|0] "" Vector__XXX
 SG_ PTC_faultRightThermalShutOutlet : 8|1@1+ (1,0) [0|0] "" Vector__XXX
 SG_ PTC_faultThermalShutPCB : 9|1@1+ (1,0) [0|0] "" Vector__XXX
 SG_ PTC_faultLeftThermalShutIGBT : 10|1@1+ (1,0) [0|0] "" Vector__XXX
 SG_ PTC_faultRightThermalShutIGBT : 12|1@1+ (1,0) [0|0] "" Vector__XXX
 SG_ PTC_faultCANTimeout : 13|1@1+ (1,0) [0|0] "" Vector__XXX
 SG_ PTC_failLowVoltageSensor : 14|1@1+ (1,0) [0|0] "" Vector__XXX
 SG_ PTC_failHighVoltageSensor : 15|1@1+ (1,0) [0|0] "" Vector__XXX
 SG_ PTC_failLeftCurrentHVSensor : 16|1@1+ (1,0) [0|0] "" Vector__XXX
 SG_ PTC_failRightCurrentHVSensor : 17|1@1+ (1,0) [0|0] "" Vector__XXX
 SG_ PTC_failLeftTempIGBT : 18|1@1+ (1,0) [0|0] "" Vector__XXX
 SG_ PTC_failTempOCP : 19|1@1+ (1,0) [0|0] "" Vector__XXX
 SG_ PTC_failRightTempIGBT : 20|1@1+ (1,0) [0|0] "" Vector__XXX
 SG_ PTC_failTempPCB : 21|1@1+ (1,0) [0|0] "" Vector__XXX
 SG_ PTC_failLeftIGBTShort : 22|1@1+ (1,0) [0|0] "" Vector__XXX
 SG_ PTC_failRightIGBTShort : 23|1@1+ (1,0) [0|0] "" Vector__XXX
 SG_ PTC_failIGBTDriverTemporary : 24|1@1+ (1,0) [0|0] "" Vector__XXX
 SG_ PTC_failIGBTDriverPermanent : 25|1@1+ (1,0) [0|0] "" Vector__XXX
 SG_ PTC_failLeftIGBTOpen : 26|1@1+ (1,0) [0|0] "" Vector__XXX
 SG_ PTC_failRightIGBTOpen : 27|1@1+ (1,0) [0|0] "" Vector__XXX
 SG_ PTC_failLeftIGBTShortWarning : 28|1@1+ (1,0) [0|0] "" Vector__XXX
 SG_ PTC_failRightIGBTShortWarning : 29|1@1+ (1,0) [0|0] "" Vector__XXX
 SG_ PTC_failRightCurrentHVSensorWng : 30|1@1+ (1,0) [0|0] "" Vector__XXX
 SG_ PTC_failLeftCurrentHVSensorWng : 31|1@1+ (1,0) [0|0] "" Vector__XXX
 SG_ PTC_igbt15V : 56|8@1+ (0.25,0) [0|0] "" Vector__XXX

BO_ 776 OCS1P_status: 8 Vector__XXX
 SG_ OCS1P_occupantClassification : 0|8@1+ (1,0) [0|0] "" Vector__XXX
 SG_ OCS1P_occupantClassificationQF : 8|1@1+ (1,0) [0|0] "" Vector__XXX
 SG_ OCS1P_occupiedState : 9|2@1+ (1,0) [0|0] "" Vector__XXX
 SG_ OCS1P_triggerSnapshot : 11|5@1+ (1,0) [0|0] "" Vector__XXX
 SG_ OCS1P_occupantClassificationRaw : 16|3@1+ (1,0) [0|0] "" Vector__XXX
 SG_ OCS1P_occupantClassificationSelf : 19|3@1+ (1,0) [0|0] "" Vector__XXX
 SG_ OCS1P_occupantClassificationRawCap : 22|3@1+ (1,0) [0|0] "" Vector__XXX
 SG_ OCS1P_occupantClassificationCap : 25|3@1+ (1,0) [0|0] "" Vector__XXX
 SG_ OCS1P_classificationHeld : 30|1@1+ (1,0) [0|0] "" Vector__XXX
 SG_ OCS1P_cushionStable : 31|1@1+ (1,0) [0|0] "" Vector__XXX
 SG_ OCS1P_classificationExtHold : 32|1@1+ (1,0) [0|0] "" Vector__XXX
 SG_ OCS1P_classificationHoldState : 33|3@1+ (1,0) [0|0] "" Vector__XXX
 SG_ OCS1P_classificationVariant : 36|3@1+ (1,0) [0|0] "" Vector__XXX
 SG_ OCS1P_sandwichDisabled : 39|1@1+ (1,0) [0|0] "" Vector__XXX
 SG_ OCS1P_noSandwichType : 40|2@1+ (1,0) [0|0] "" Vector__XXX
 SG_ OCS1P_sandwichBoundaryType : 42|1@1+ (1,0) [0|0] "" Vector__XXX
 SG_ OCS1P_sbrBoundaryType : 43|1@1+ (1,0) [0|0] "" Vector__XXX
 SG_ OCS1P_occupiedStateCap : 45|2@1+ (1,0) [0|0] "" Vector__XXX
 SG_ OCS1P_seatbackStable : 47|1@1+ (1,0) [0|0] "" Vector__XXX
 SG_ OCS1P_sandwichStable : 48|1@1+ (1,0) [0|0] "" Vector__XXX
 SG_ OCS1P_cushionStableCap : 49|1@1+ (1,0) [0|0] "" Vector__XXX
 SG_ OCS1P_seatbackStableCap : 50|1@1+ (1,0) [0|0] "" Vector__XXX
 SG_ OCS1P_classificationHeldCap : 51|1@1+ (1,0) [0|0] "" Vector__XXX
 SG_ OCS1P_statusCounter : 52|4@1+ (1,0) [0|0] "" Vector__XXX
 SG_ OCS1P_statusChecksum : 56|8@1+ (1,0) [0|0] "" Vector__XXX

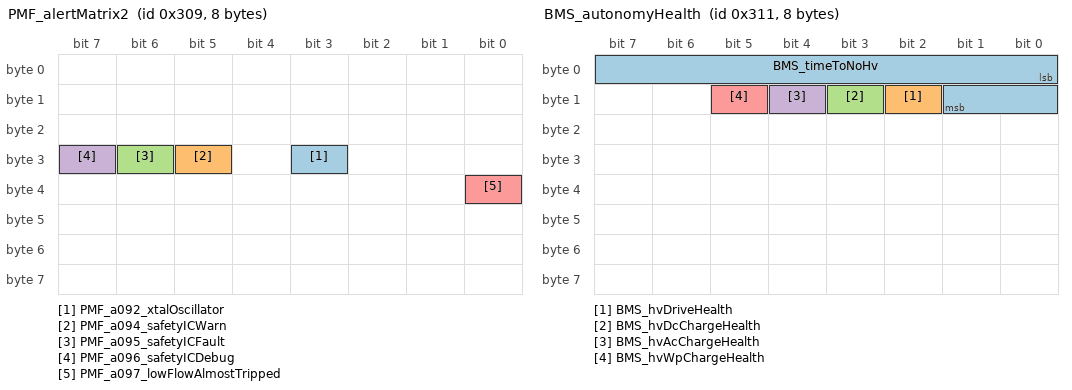
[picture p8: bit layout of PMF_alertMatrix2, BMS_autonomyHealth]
BO_ 777 PMF_alertMatrix2: 8 Vector__XXX
 SG_ PMF_a092_xtalOscillator : 27|1@1+ (1,0) [0|0] "" Vector__XXX
 SG_ PMF_a094_safetyICWarn : 29|1@1+ (1,0) [0|0] "" Vector__XXX
 SG_ PMF_a095_safetyICFault : 30|1@1+ (1,0) [0|0] "" Vector__XXX
 SG_ PMF_a096_safetyICDebug : 31|1@1+ (1,0) [0|0] "" Vector__XXX
 SG_ PMF_a097_lowFlowAlmostTripped : 32|1@1+ (1,0) [0|0] "" Vector__XXX

BO_ 784 HVP_info: 8 Vector__XXX
 SG_ HVP_infoIndex M : 0|8@1+ (1,0) [0|0] "" Vector__XXX
 SG_ HVP_appGitHash m17 : 8|56@1+ (1,0) [0|0] "" Vector__XXX
 SG_ HVP_bootGitHash m18 : 8|56@1+ (1,0) [0|0] "" Vector__XXX
 SG_ HVP_bootUdsProtoVersion m20 : 8|8@1+ (1,0) [0|0] "" Vector__XXX
 SG_ HVP_buildType m10 : 8|3@1+ (1,0) [0|0] "" Vector__XXX
 SG_ HVP_platformType m13 : 8|8@1+ (1,0) [0|0] "" Vector__XXX
 SG_ HVP_buildConfigId m10 : 16|16@1+ (1,0) [0|0] "" Vector__XXX
 SG_ HVP_pcbaId m11 : 16|8@1+ (1,0) [0|0] "" Vector__XXX
 SG_ HVP_assemblyId m11 : 24|8@1+ (1,0) [0|0] "" Vector__XXX
 SG_ HVP_appCrc m13 : 32|32@1+ (1,0) [0|0] "" Vector__XXX
 SG_ HVP_bootCrc m20 : 32|32@1+ (1,0) [0|0] "" Vector__XXX
 SG_ HVP_hardwareId m10 : 32|16@1+ (1,0) [0|0] "" Vector__XXX
 SG_ HVP_usageId m11 : 32|16@1+ (1,0) [0|0] "" Vector__XXX
 SG_ HVP_componentId m10 : 48|16@1+ (1,0) [0|0] "" Vector__XXX
 SG_ HVP_subUsageId m11 : 48|16@1+ (1,0) [0|0] "" Vector__XXX

BO_ 785 BMS_autonomyHealth: 8 Vector__XXX
 SG_ BMS_timeToNoHv : 0|10@1+ (1,0) [0|0] "" Vector__XXX
 SG_ BMS_hvDriveHealth : 10|1@1+ (1,0) [0|0] "" Vector__XXX
 SG_ BMS_hvDcChargeHealth : 11|1@1+ (1,0) [0|0] "" Vector__XXX
 SG_ BMS_hvAcChargeHealth : 12|1@1+ (1,0) [0|0] "" Vector__XXX
 SG_ BMS_hvWpChargeHealth : 13|1@1+ (1,0) [0|0] "" Vector__XXX

BO_ 786 BMS_thermalStatus: 8 Vector__XXX
 SG_ BMS_thermalStatusMultiplexer M : 0|2@1+ (1,0) [0|0] "" Vector__XXX
 SG_ BMS_coldStagnationLimit m1 : 2|9@1+ (0.25,-25) [0|0] "" Vector__XXX
 SG_ BMS_inletActiveCoolTargetT m0 : 2|9@1+ (0.25,-25) [0|0] "" Vector__XXX
 SG_ BMS_hotStagnationLimit m1 : 11|9@1+ (0.25,-25) [0|0] "" Vector__XXX
 SG_ BMS_inletPassiveTargetT m0 : 11|9@1+ (0.25,-25) [0|0] "" Vector__XXX
 SG_ BMS_hotCellTempLimit m1 : 20|9@1+ (0.25,-25) [0|0] "" Vector__XXX
 SG_ BMS_inletActiveHeatTargetT m0 : 20|9@1+ (0.25,-25) [0|0] "" Vector__XXX
 SG_ BMS_i2tDeratingEnabled m1 : 29|1@1+ (1,0) [0|0] "" Vector__XXX
 SG_ BMS_requestDischarge m0 : 29|1@1+ (1,0) [0|0] "" Vector__XXX
 SG_ BMS_activeHeatingWorthwhile m0 : 30|1@1+ (1,0) [0|0] "" Vector__XXX
 SG_ BMS_pcsNoFlowRequest m0 : 31|1@1+ (1,0) [0|0] "" Vector__XXX
 SG_ BMS_activeCoolCellReferenceT m1 : 32|9@1+ (0.25,-25) [0|0] "" Vector__XXX
 SG_ BMS_minPackTemperature m0 : 32|10@1+ (0.2,-40) [0|0] "" Vector__XXX
 SG_ BMS_activeHeatCellTargetT m1 : 41|9@1+ (0.25,-25) [0|0] "" Vector__XXX
 SG_ BMS_noFlowRequest m0 : 42|1@1+ (1,0) [0|0] "" Vector__XXX
 SG_ BMS_maxPackTemperature m0 : 43|11@1+ (0.1,-40) [0|0] "" Vector__XXX
 SG_ BMS_powerDissipation m1 : 50|10@1+ (0.02,0) [0|0] "" Vector__XXX
 SG_ BMS_flowRequest m0 : 56|8@1+ (0.25,0) [0|0] "" Vector__XXX

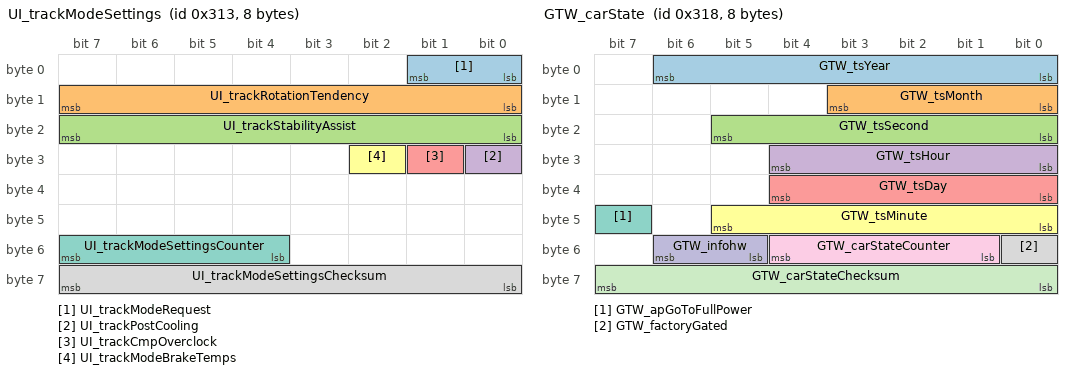
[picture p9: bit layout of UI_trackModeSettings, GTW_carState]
BO_ 787 UI_trackModeSettings: 8 Vector__XXX
 SG_ UI_trackModeRequest : 0|2@1+ (1,0) [0|0] "" Vector__XXX
 SG_ UI_trackRotationTendency : 8|8@1+ (0.5,0) [0|0] "" Vector__XXX
 SG_ UI_trackStabilityAssist : 16|8@1+ (0.5,0) [0|0] "" Vector__XXX
 SG_ UI_trackPostCooling : 24|1@1+ (1,0) [0|0] "" Vector__XXX
 SG_ UI_trackCmpOverclock : 25|1@1+ (1,0) [0|0] "" Vector__XXX
 SG_ UI_trackModeBrakeTemps : 26|1@1+ (1,0) [0|0] "" Vector__XXX
 SG_ UI_trackModeSettingsCounter : 52|4@1+ (1,0) [0|0] "" Vector__XXX
 SG_ UI_trackModeSettingsChecksum : 56|8@1+ (1,0) [0|0] "" Vector__XXX

BO_ 789 DIR_temperature: 8 Vector__XXX
 SG_ DIR_tempIndex M : 0|3@1+ (1,0) [0|0] "" Vector__XXX
 SG_ DIR_currentWeibullMiles m3 : 3|16@1+ (8,0) [0|0] "" Vector__XXX
 SG_ DIR_inverterTQF m0 : 3|2@1+ (1,0) [0|0] "" Vector__XXX
 SG_ DIR_fluidInTemp m2 : 8|8@1+ (1,-40) [0|0] "" Vector__XXX
 SG_ DIR_heatsink1Temp m1 : 8|8@1+ (1,-40) [0|0] "" Vector__XXX
 SG_ DIR_initialBurnInVehicleOdometer m4 : 8|32@1+ (0.001,0) [0|0] "" Vector__XXX
 SG_ DIR_pcbT m0 : 8|8@1+ (1,-40) [0|0] "" Vector__XXX
 SG_ DIR_heatsink2Temp m1 : 16|8@1+ (1,-40) [0|0] "" Vector__XXX
 SG_ DIR_inverterT m0 : 16|8@1+ (1,-40) [0|0] "" Vector__XXX
 SG_ DIR_normalFetBurnIn m2 : 16|16@1+ (0.00763,0) [0|0] "" Vector__XXX
 SG_ DIR_endOfServiceWeibullMiles m3 : 19|16@1+ (8,0) [0|0] "" Vector__XXX
 SG_ DIR_heatsink3Temp m1 : 24|8@1+ (1,-40) [0|0] "" Vector__XXX
 SG_ DIR_statorT m0 : 24|8@1+ (1,-40) [0|0] "" Vector__XXX
 SG_ DIR_additionalFetBurnIn m2 : 32|16@1+ (0.00763,0) [0|0] "" Vector__XXX
 SG_ DIR_dcCapT m0 : 32|8@1+ (1,-40) [0|0] "" Vector__XXX
 SG_ DIR_pcbTemp2 m1 : 32|8@1+ (1,-40) [0|0] "" Vector__XXX
 SG_ DIR_burnInDamageRatio m3 : 35|9@1+ (0.01,0) [0|0] "" Vector__XXX
 SG_ DIR_heatsinkT m0 : 40|8@1+ (1,-40) [0|0] "" Vector__XXX
 SG_ DIR_inverterHS2Est m4 : 40|8@1+ (1,-40) [0|0] "" Vector__XXX
 SG_ DIR_junctionTemp m1 : 40|8@1+ (1,-40) [0|0] "" Vector__XXX
 SG_ DIR_inverterSensorEst m3 : 44|8@1+ (1,-40) [0|0] "" Vector__XXX
 SG_ DIR_TPak1Temp m1 : 48|8@1+ (1,-40) [0|0] "" Vector__XXX
 SG_ DIR_inverterInletEst m4 : 48|8@1+ (1,-40) [0|0] "" Vector__XXX
 SG_ DIR_inverterTpct m0 : 48|8@1+ (0.4,0) [0|0] "" Vector__XXX
 SG_ DIR_inverterHS1Est m3 : 52|8@1+ (1,-40) [0|0] "" Vector__XXX
 SG_ DIR_TPak2Temp m1 : 56|8@1+ (1,-40) [0|0] "" Vector__XXX
 SG_ DIR_statorHousingTemp m4 : 56|8@1+ (1,-40) [0|0] "" Vector__XXX
 SG_ DIR_statorTpct m0 : 56|8@1+ (0.4,0) [0|0] "" Vector__XXX

BO_ 790 PMF_info: 8 Vector__XXX
 SG_ PMF_infoIndex M : 0|8@1+ (1,0) [0|0] "" Vector__XXX
 SG_ PMF_appGitHash m17 : 8|56@1+ (1,0) [0|0] "" Vector__XXX
 SG_ PMF_bootGitHash m18 : 8|56@1+ (1,0) [0|0] "" Vector__XXX
 SG_ PMF_buildType m10 : 8|8@1+ (1,0) [0|0] "" Vector__XXX
 SG_ PMF_diNodeBuildType m21 : 8|8@1+ (1,0) [0|0] "" Vector__XXX
 SG_ PMF_platformTyp m19 : 8|8@1+ (1,0) [0|0] "" Vector__XXX
 SG_ PMF_udsProtocolVersion m20 : 8|8@1+ (1,0) [0|0] "" Vector__XXX
 SG_ PMF_buildConfigurationId m10 : 16|16@1+ (1,0) [0|0] "" Vector__XXX
 SG_ PMF_diNodeBuildConfigurationId m21 : 16|16@1+ (1,0) [0|0] "" Vector__XXX
 SG_ PMF_pcbaId m11 : 16|8@1+ (1,0) [0|0] "" Vector__XXX
 SG_ PMF_assemblyId m11 : 24|8@1+ (1,0) [0|0] "" Vector__XXX
 SG_ PMF_applicationCrc m13 : 32|32@1+ (1,0) [0|0] "" Vector__XXX
 SG_ PMF_bootloaderCrc m20 : 32|32@1+ (1,0) [0|0] "" Vector__XXX
 SG_ PMF_diNodeApplicationCrc m21 : 32|32@1+ (1,0) [0|0] "" Vector__XXX
 SG_ PMF_hardwareId m10 : 32|8@1+ (1,0) [0|0] "" Vector__XXX
 SG_ PMF_usageId m11 : 32|16@1+ (1,0) [0|0] "" Vector__XXX
 SG_ PMF_componentId m10 : 48|16@1+ (1,0) [0|0] "" Vector__XXX
 SG_ PMF_subUsageId m11 : 48|16@1+ (1,0) [0|0] "" Vector__XXX

BO_ 792 GTW_carState: 8 Vector__XXX
 SG_ GTW_tsYear : 0|7@1+ (1,2000) [0|0] "" Vector__XXX
 SG_ GTW_tsMonth : 8|4@1+ (1,0) [0|0] "" Vector__XXX
 SG_ GTW_tsSecond : 16|6@1+ (1,0) [0|0] "" Vector__XXX
 SG_ GTW_tsHour : 24|5@1+ (1,0) [0|0] "" Vector__XXX
 SG_ GTW_tsDay : 32|5@1+ (1,0) [0|0] "" Vector__XXX
 SG_ GTW_tsMinute : 40|6@1+ (1,0) [0|0] "" Vector__XXX
 SG_ GTW_apGoToFullPower : 47|1@1+ (1,0) [0|0] "" Vector__XXX
 SG_ GTW_factoryGated : 48|1@1+ (1,0) [0|0] "" Vector__XXX
 SG_ GTW_carStateCounter : 49|4@1+ (1,0) [0|0] "" Vector__XXX
 SG_ GTW_infohw : 53|2@1+ (1,0) [0|0] "" Vector__XXX
 SG_ GTW_carStateChecksum : 56|8@1+ (1,0) [0|0] "" Vector__XXX

BO_ 793 VCSEC_info: 8 Vector__XXX
 SG_ VCSEC_infoIndex M : 0|8@1+ (1,0) [0|0] "" Vector__XXX
 SG_ VCSEC_infoAppGitHash m17 : 8|56@1+ (1,0) [0|0] "" Vector__XXX
 SG_ VCSEC_infoBootGitHash m18 : 8|56@1+ (1,0) [0|0] "" Vector__XXX
 SG_ VCSEC_infoBootUdsProtoVersion m20 : 8|16@1+ (1,0) [0|0] "" Vector__XXX
 SG_ VCSEC_infoBuildType m10 : 8|3@1+ (1,0) [0|0] "" Vector__XXX
 SG_ VCSEC_infoPcbaId m11 : 8|8@1+ (1,0) [0|0] "" Vector__XXX
 SG_ VCSEC_infoPlatformType m19 : 8|8@1+ (1,0) [0|0] "" Vector__XXX
 SG_ VCSEC_infoAssemblyId m11 : 16|8@1+ (1,0) [0|0] "" Vector__XXX
 SG_ VCSEC_infoBuildConfigId m10 : 16|16@1+ (1,0) [0|0] "" Vector__XXX
 SG_ VCSEC_infoBootCrc m20 : 24|32@1+ (1,0) [0|0] "" Vector__XXX
 SG_ VCSEC_infoAppCrc m13 : 32|32@1+ (1,0) [0|0] "" Vector__XXX
 SG_ VCSEC_infoHardwareId m10 : 32|16@1+ (1,0) [0|0] "" Vector__XXX
 SG_ VCSEC_infoSubcomponent1 m16 : 32|32@1+ (1,0) [0|0] "" Vector__XXX
 SG_ VCSEC_infoSubcomponent10 m37 : 32|32@1+ (1,0) [0|0] "" Vector__XXX
 SG_ VCSEC_infoSubcomponent11 m38 : 32|32@1+ (1,0) [0|0] "" Vector__XXX
 SG_ VCSEC_infoSubcomponent12 m39 : 32|32@1+ (1,0) [0|0] "" Vector__XXX
 SG_ VCSEC_infoSubcomponent13 m40 : 32|32@1+ (1,0) [0|0] "" Vector__XXX
 SG_ VCSEC_infoSubcomponent14 m41 : 32|32@1+ (1,0) [0|0] "" Vector__XXX
 SG_ VCSEC_infoSubcomponent2 m23 : 32|32@1+ (1,0) [0|0] "" Vector__XXX
 SG_ VCSEC_infoSubcomponent3 m24 : 32|32@1+ (1,0) [0|0] "" Vector__XXX
 SG_ VCSEC_infoSubcomponent4 m31 : 32|32@1+ (1,0) [0|0] "" Vector__XXX
 SG_ VCSEC_infoSubcomponent5 m32 : 32|32@1+ (1,0) [0|0] "" Vector__XXX
 SG_ VCSEC_infoSubcomponent6 m33 : 32|32@1+ (1,0) [0|0] "" Vector__XXX
 SG_ VCSEC_infoSubcomponent7 m34 : 32|32@1+ (1,0) [0|0] "" Vector__XXX
 SG_ VCSEC_infoSubcomponent8 m35 : 32|32@1+ (1,0) [0|0] "" Vector__XXX
 SG_ VCSEC_infoSubcomponent9 m36 : 32|32@1+ (1,0) [0|0] "" Vector__XXX
 SG_ VCSEC_infoUsageId m11 : 32|16@1+ (1,0) [0|0] "" Vector__XXX
 SG_ VCSEC_infoComponentId m10 : 48|16@1+ (1,0) [0|0] "" Vector__XXX
 SG_ VCSEC_infoSubUsageId m11 : 48|16@1+ (1,0) [0|0] "" Vector__XXX

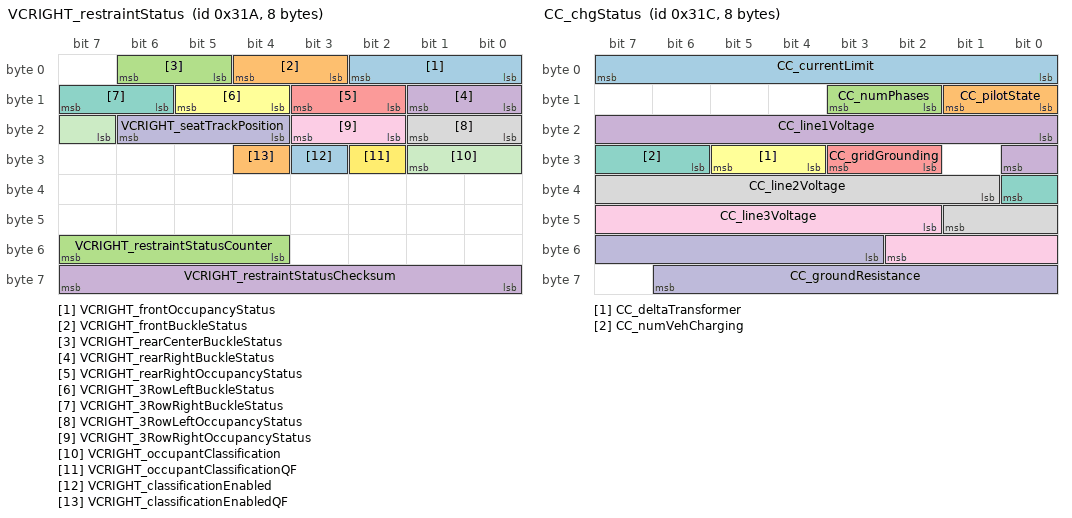
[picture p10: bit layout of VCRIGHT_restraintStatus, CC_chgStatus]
BO_ 794 VCRIGHT_restraintStatus: 8 Vector__XXX
 SG_ VCRIGHT_frontOccupancyStatus : 0|3@1+ (1,0) [0|0] "" Vector__XXX
 SG_ VCRIGHT_frontBuckleStatus : 3|2@1+ (1,0) [0|0] "" Vector__XXX
 SG_ VCRIGHT_rearCenterBuckleStatus : 5|2@1+ (1,0) [0|0] "" Vector__XXX
 SG_ VCRIGHT_rearRightBuckleStatus : 8|2@1+ (1,0) [0|0] "" Vector__XXX
 SG_ VCRIGHT_rearRightOccupancyStatus : 10|2@1+ (1,0) [0|0] "" Vector__XXX
 SG_ VCRIGHT_3RowLeftBuckleStatus : 12|2@1+ (1,0) [0|0] "" Vector__XXX
 SG_ VCRIGHT_3RowRightBuckleStatus : 14|2@1+ (1,0) [0|0] "" Vector__XXX
 SG_ VCRIGHT_3RowLeftOccupancyStatus : 16|2@1+ (1,0) [0|0] "" Vector__XXX
 SG_ VCRIGHT_3RowRightOccupancyStatus : 18|2@1+ (1,0) [0|0] "" Vector__XXX
 SG_ VCRIGHT_seatTrackPosition : 20|3@1+ (1,0) [0|0] "" Vector__XXX
 SG_ VCRIGHT_occupantClassification : 23|3@1+ (1,0) [0|0] "" Vector__XXX
 SG_ VCRIGHT_occupantClassificationQF : 26|1@1+ (1,0) [0|0] "" Vector__XXX
 SG_ VCRIGHT_classificationEnabled : 27|1@1+ (1,0) [0|0] "" Vector__XXX
 SG_ VCRIGHT_classificationEnabledQF : 28|1@1+ (1,0) [0|0] "" Vector__XXX
 SG_ VCRIGHT_restraintStatusCounter : 52|4@1+ (1,0) [0|0] "" Vector__XXX
 SG_ VCRIGHT_restraintStatusChecksum : 56|8@1+ (1,0) [0|0] "" Vector__XXX

BO_ 796 CC_chgStatus: 8 Vector__XXX
 SG_ CC_currentLimit : 0|8@1+ (0.5,0) [0|0] "" Vector__XXX
 SG_ CC_pilotState : 8|2@1+ (1,0) [0|0] "" Vector__XXX
 SG_ CC_numPhases : 10|2@1+ (1,0) [0|0] "" Vector__XXX
 SG_ CC_line1Voltage : 16|9@1+ (1,0) [0|0] "" Vector__XXX
 SG_ CC_gridGrounding : 26|2@1+ (1,0) [0|0] "" Vector__XXX
 SG_ CC_deltaTransformer : 28|2@1+ (1,0) [0|0] "" Vector__XXX
 SG_ CC_numVehCharging : 30|3@1+ (1,0) [0|0] "" Vector__XXX
 SG_ CC_line2Voltage : 33|9@1+ (1,0) [0|0] "" Vector__XXX
 SG_ CC_line3Voltage : 42|9@1+ (1,0) [0|0] "" Vector__XXX
 SG_ CC_groundResistance : 51|12@1+ (1,0) [0|0] "" Vector__XXX

BO_ 797 CC_chgStatus2: 8 Vector__XXX
 SG_ CC_chgStatus2Index M : 0|8@1+ (1,0) [0|0] "" Vector__XXX
 SG_ CC_buttonState m0 : 8|1@1+ (1,0) [0|0] "" Vector__XXX
 SG_ EVSE_v2xSupport m0 : 9|2@1+ (1,0) [0|0] "" Vector__XXX
 SG_ EVSE_v2xHandshakeStart m0 : 12|1@1+ (1,0) [0|0] "" Vector__XXX

BO_ 798 CP_alertMatrix: 8 Vector__XXX
 SG_ CP_matrixIndex M : 0|4@1+ (1,0) [0|0] "" Vector__XXX
 SG_ CP_a001_canRx m0 : 4|1@1+ (1,0) [0|0] "" Vector__XXX
 SG_ CP_a061_uhfReceiverMIA m1 : 4|1@1+ (1,0) [0|0] "" Vector__XXX
 SG_ CP_a121_PLCRLY_lostCommsCP m2 : 4|1@1+ (1,0) [0|0] "" Vector__XXX
 SG_ CP_a002_canTx m0 : 5|1@1+ (1,0) [0|0] "" Vector__XXX
 SG_ CP_a062_scOutOfService m1 : 5|1@1+ (1,0) [0|0] "" Vector__XXX
 SG_ CP_a122_plcModemFailure m2 : 5|1@1+ (1,0) [0|0] "" Vector__XXX
 SG_ CP_a182_pncdCommsError m3 : 5|1@1+ (1,0) [0|0] "" Vector__XXX
 SG_ CP_a003_canError m0 : 6|1@1+ (1,0) [0|0] "" Vector__XXX
 SG_ CP_a063_scUpdateInProgress m1 : 6|1@1+ (1,0) [0|0] "" Vector__XXX
 SG_ CP_a123_latchPotIrrational m2 : 6|1@1+ (1,0) [0|0] "" Vector__XXX
 SG_ CP_a183_certManagerError m3 : 6|1@1+ (1,0) [0|0] "" Vector__XXX
 SG_ CP_a004_proximityRationality m0 : 7|1@1+ (1,0) [0|0] "" Vector__XXX
 SG_ CP_a064_superchargingBlocked m1 : 7|1@1+ (1,0) [0|0] "" Vector__XXX
 SG_ CP_a124_ivledFault m2 : 7|1@1+ (1,0) [0|0] "" Vector__XXX
 SG_ CP_a184_certChangeEvent m3 : 7|1@1+ (1,0) [0|0] "" Vector__XXX
 SG_ CP_a005_gbdcLiveDisconnect m0 : 8|1@1+ (1,0) [0|0] "" Vector__XXX
 SG_ CP_a065_selfTestFailed m1 : 8|1@1+ (1,0) [0|0] "" Vector__XXX
 SG_ CP_a125_unexpectedLVJuiceState m2 : 8|1@1+ (1,0) [0|0] "" Vector__XXX
 SG_ CP_a185_pncAuthRejection m3 : 8|1@1+ (1,0) [0|0] "" Vector__XXX
 SG_ CP_a006_lostCommsBMS m0 : 9|1@1+ (1,0) [0|0] "" Vector__XXX
 SG_ CP_a066_proxLatchedIdlePilot m1 : 9|1@1+ (1,0) [0|0] "" Vector__XXX
 SG_ CP_a126_wakeOnUhfFault m2 : 9|1@1+ (1,0) [0|0] "" Vector__XXX
 SG_ CP_a186_spiDmaFailure m3 : 9|1@1+ (1,0) [0|0] "" Vector__XXX
 SG_ CP_a007_watchdog m0 : 10|1@1+ (1,0) [0|0] "" Vector__XXX
 SG_ CP_a067_gbdcConnFault m1 : 10|1@1+ (1,0) [0|0] "" Vector__XXX
 SG_ CP_a127_lostCommsHVLINK m2 : 10|1@1+ (1,0) [0|0] "" Vector__XXX
 SG_ CP_a187_highStackUsage m3 : 10|1@1+ (1,0) [0|0] "" Vector__XXX
 SG_ CP_a008_memoryError m0 : 11|1@1+ (1,0) [0|0] "" Vector__XXX
 SG_ CP_a068_doorSensorMismatch m1 : 11|1@1+ (1,0) [0|0] "" Vector__XXX
 SG_ CP_a128_lostCommsVC m2 : 11|1@1+ (1,0) [0|0] "" Vector__XXX
 SG_ CP_a188_v2lEvseRequiresUpdate m3 : 11|1@1+ (1,0) [0|0] "" Vector__XXX
 SG_ CP_a009_coverOpenAllChgBlocked m0 : 12|1@1+ (1,0) [0|0] "" Vector__XXX
 SG_ CP_a069_doorInductiveSensorError m1 : 12|1@1+ (1,0) [0|0] "" Vector__XXX
 SG_ CP_a129_bldcDriverCommsFailed m2 : 12|1@1+ (1,0) [0|0] "" Vector__XXX
 SG_ CP_a189_resistivePresenceRationality m3 : 12|1@1+ (1,0) [0|0] "" Vector__XXX
 SG_ CP_a010_pilotRationality m0 : 13|1@1+ (1,0) [0|0] "" Vector__XXX
 SG_ CP_a070_doorInductiveSensorReset m1 : 13|1@1+ (1,0) [0|0] "" Vector__XXX
 SG_ CP_a130_bldcDriverCommsRecovered m2 : 13|1@1+ (1,0) [0|0] "" Vector__XXX
 SG_ CP_d190_backCoverCircuitIssue m3 : 13|1@1+ (1,0) [0|0] "" Vector__XXX
 SG_ CP_a011_eeprom m0 : 14|1@1+ (1,0) [0|0] "" Vector__XXX
 SG_ CP_a071_exiDecodeFailure m1 : 14|1@1+ (1,0) [0|0] "" Vector__XXX
 SG_ CP_a131_evseCommTimeout m2 : 14|1@1+ (1,0) [0|0] "" Vector__XXX
 SG_ CP_d191_latchConnectionIssue m3 : 14|1@1+ (1,0) [0|0] "" Vector__XXX
 SG_ CP_a012_ledDriver m0 : 15|1@1+ (1,0) [0|0] "" Vector__XXX
 SG_ CP_a072_v2gEvccTimeout m1 : 15|1@1+ (1,0) [0|0] "" Vector__XXX
 SG_ CP_a132_contractAuthTimeout m2 : 15|1@1+ (1,0) [0|0] "" Vector__XXX
 SG_ CP_d192_couplerTempHigh m3 : 15|1@1+ (1,0) [0|0] "" Vector__XXX
 SG_ CP_a013_lostCommsGTW m0 : 16|1@1+ (1,0) [0|0] "" Vector__XXX
 SG_ CP_a073_iecComboShutdown m1 : 16|1@1+ (1,0) [0|0] "" Vector__XXX
 SG_ CP_a133_proxNeverLatched m2 : 16|1@1+ (1,0) [0|0] "" Vector__XXX
 SG_ CP_d193_proximityCircuitErratic m3 : 16|1@1+ (1,0) [0|0] "" Vector__XXX
 SG_ CP_a014_lostCommsCHG m0 : 17|1@1+ (1,0) [0|0] "" Vector__XXX
 SG_ CP_a074_failedToEstablishV2gComm m1 : 17|1@1+ (1,0) [0|0] "" Vector__XXX
 SG_ CP_a134_plcModemNotExpected m2 : 17|1@1+ (1,0) [0|0] "" Vector__XXX
 SG_ CP_d194_proximityCircuitRangeIssue m3 : 17|1@1+ (1,0) [0|0] "" Vector__XXX
 SG_ CP_a015_apsVov m0 : 18|1@1+ (1,0) [0|0] "" Vector__XXX
 SG_ CP_a075_v2gCommsFailure m1 : 18|1@1+ (1,0) [0|0] "" Vector__XXX
 SG_ CP_a135_sdpAttemptsFailed m2 : 18|1@1+ (1,0) [0|0] "" Vector__XXX
 SG_ CP_d195_couplerLockActuatorIssue m3 : 18|1@1+ (1,0) [0|0] "" Vector__XXX
 SG_ CP_a016_apsVuv m0 : 19|1@1+ (1,0) [0|0] "" Vector__XXX
 SG_ CP_a076_LDC1612errorWatchdog m1 : 19|1@1+ (1,0) [0|0] "" Vector__XXX
 SG_ CP_a136_sdpSideReqFailed m2 : 19|1@1+ (1,0) [0|0] "" Vector__XXX
 SG_ CP_d196_doorActuatorPerformanceIssue m3 : 19|1@1+ (1,0) [0|0] "" Vector__XXX
 SG_ CP_a017_fiveVov m0 : 20|1@1+ (1,0) [0|0] "" Vector__XXX
 SG_ CP_a077_invalidMacAddress m1 : 20|1@1+ (1,0) [0|0] "" Vector__XXX
 SG_ CP_a137_plcForwardError m2 : 20|1@1+ (1,0) [0|0] "" Vector__XXX
 SG_ CP_d197_doorSensorCircuitErratic m3 : 20|1@1+ (1,0) [0|0] "" Vector__XXX
 SG_ CP_a018_fiveVuv m0 : 21|1@1+ (1,0) [0|0] "" Vector__XXX
 SG_ CP_a078_latchNotDisengagedCold m1 : 21|1@1+ (1,0) [0|0] "" Vector__XXX
 SG_ CP_a138_swcanCommsAcEvseFaulted m2 : 21|1@1+ (1,0) [0|0] "" Vector__XXX
 SG_ CP_d198_couplerTempSensorCircuitErratic m3 : 21|1@1+ (1,0) [0|0] "" Vector__XXX
 SG_ CP_a019_threeVov m0 : 22|1@1+ (1,0) [0|0] "" Vector__XXX
 SG_ CP_a079_cableNotSecuredCold m1 : 22|1@1+ (1,0) [0|0] "" Vector__XXX
 SG_ CP_a139_pilotFaulted m2 : 22|1@1+ (1,0) [0|0] "" Vector__XXX
 SG_ CP_d199_hardwareConfigMismatch m3 : 22|1@1+ (1,0) [0|0] "" Vector__XXX
 SG_ CP_a020_threeVuv m0 : 23|1@1+ (1,0) [0|0] "" Vector__XXX
 SG_ CP_a080_taskStackOverflow m1 : 23|1@1+ (1,0) [0|0] "" Vector__XXX
 SG_ CP_a140_superchargerFaulted m2 : 23|1@1+ (1,0) [0|0] "" Vector__XXX
 SG_ CP_d200_pilotCircuitIssue m3 : 23|1@1+ (1,0) [0|0] "" Vector__XXX
 SG_ CP_a021_zeroVov m0 : 24|1@1+ (1,0) [0|0] "" Vector__XXX
 SG_ CP_a081_swException m1 : 24|1@1+ (1,0) [0|0] "" Vector__XXX
 SG_ CP_a141_chademoAdapterFault m2 : 24|1@1+ (1,0) [0|0] "" Vector__XXX
 SG_ CP_a201_uhfDoorOpenRepeatedlyOverLimit m3 : 24|1@1+ (1,0) [0|0] "" Vector__XXX
 SG_ CP_a022_zeroVuv m0 : 25|1@1+ (1,0) [0|0] "" Vector__XXX
 SG_ CP_a082_powerOnReset m1 : 25|1@1+ (1,0) [0|0] "" Vector__XXX
 SG_ CP_a142_gbdcScConnFault m2 : 25|1@1+ (1,0) [0|0] "" Vector__XXX
 SG_ CP_a202_failedToEstablishV2gComm2 m3 : 25|1@1+ (1,0) [0|0] "" Vector__XXX
 SG_ CP_a023_gbdcSessionFailed m0 : 26|1@1+ (1,0) [0|0] "" Vector__XXX
 SG_ CP_a083_watchdogTraceData m1 : 26|1@1+ (1,0) [0|0] "" Vector__XXX
 SG_ CP_a143_unsupportedChargeAdapter m2 : 26|1@1+ (1,0) [0|0] "" Vector__XXX
 SG_ CP_a203_evseCommTimeout2 m3 : 26|1@1+ (1,0) [0|0] "" Vector__XXX
 SG_ CP_a024_ledsUC m0 : 27|1@1+ (1,0) [0|0] "" Vector__XXX
 SG_ CP_a084_proxPeDisconnected_gb m1 : 27|1@1+ (1,0) [0|0] "" Vector__XXX
 SG_ CP_a144_nvmInitFailed m2 : 27|1@1+ (1,0) [0|0] "" Vector__XXX
 SG_ CP_a204_sdpAttemptsFailed2 m3 : 27|1@1+ (1,0) [0|0] "" Vector__XXX
 SG_ CP_a025_ledsOC m0 : 28|1@1+ (1,0) [0|0] "" Vector__XXX
 SG_ CP_a085_dcPinTempFaulted m1 : 28|1@1+ (1,0) [0|0] "" Vector__XXX
 SG_ CP_a145_modemAppLoadFailedNA m2 : 28|1@1+ (1,0) [0|0] "" Vector__XXX
 SG_ CP_a205_doorPositionUndetectable m3 : 28|1@1+ (1,0) [0|0] "" Vector__XXX
 SG_ CP_a026_networkManagement m0 : 29|1@1+ (1,0) [0|0] "" Vector__XXX
 SG_ CP_a086_dcPinTempIrrational m1 : 29|1@1+ (1,0) [0|0] "" Vector__XXX
 SG_ CP_a146_ccsEvseMalfunction m2 : 29|1@1+ (1,0) [0|0] "" Vector__XXX
 SG_ CP_a206_peToChassisDisconnected m3 : 29|1@1+ (1,0) [0|0] "" Vector__XXX
 SG_ CP_a027_doorSensorOutOfSpec m0 : 30|1@1+ (1,0) [0|0] "" Vector__XXX
 SG_ CP_a087_dcTempModelFault m1 : 30|1@1+ (1,0) [0|0] "" Vector__XXX
 SG_ CP_a147_inductiveRecoveredMia m2 : 30|1@1+ (1,0) [0|0] "" Vector__XXX
 SG_ CP_a028_insertEnableMismatch m0 : 31|1@1+ (1,0) [0|0] "" Vector__XXX
 SG_ CP_a088_dcTempModelDeviation m1 : 31|1@1+ (1,0) [0|0] "" Vector__XXX
 SG_ CP_a148_bldcTachFeedbackMia m2 : 31|1@1+ (1,0) [0|0] "" Vector__XXX
 SG_ CP_a029_doorClosedProxPilot m0 : 32|1@1+ (1,0) [0|0] "" Vector__XXX
 SG_ CP_a089_plcConfigMismatch m1 : 32|1@1+ (1,0) [0|0] "" Vector__XXX
 SG_ CP_a149_pilotPeriodInvalid m2 : 32|1@1+ (1,0) [0|0] "" Vector__XXX
 SG_ CP_a030_busOff m0 : 33|1@1+ (1,0) [0|0] "" Vector__XXX
 SG_ CP_a090_ccsEvseLowIso m1 : 33|1@1+ (1,0) [0|0] "" Vector__XXX
 SG_ CP_a150_railToggleTimeout m2 : 33|1@1+ (1,0) [0|0] "" Vector__XXX
 SG_ CP_a031_doorClosedCommandedOpen m0 : 34|1@1+ (1,0) [0|0] "" Vector__XXX
 SG_ CP_a091_wrongSuperchargerHandle m1 : 34|1@1+ (1,0) [0|0] "" Vector__XXX
 SG_ CP_a151_badPilotDiodeDetected m2 : 34|1@1+ (1,0) [0|0] "" Vector__XXX
 SG_ CP_a032_doorOpenExpectedClosed m0 : 35|1@1+ (1,0) [0|0] "" Vector__XXX
 SG_ CP_a092_modemAppLoadFailed m1 : 35|1@1+ (1,0) [0|0] "" Vector__XXX
 SG_ CP_a152_pilotEdgeDetectionFailed m2 : 35|1@1+ (1,0) [0|0] "" Vector__XXX
 SG_ CP_a033_spiOpen m0 : 36|1@1+ (1,0) [0|0] "" Vector__XXX
 SG_ CP_a093_modemLoadedWithReset m1 : 36|1@1+ (1,0) [0|0] "" Vector__XXX
 SG_ CP_a153_thermalAcLimitActive m2 : 36|1@1+ (1,0) [0|0] "" Vector__XXX
 SG_ CP_a034_calibrationIncomplete m0 : 37|1@1+ (1,0) [0|0] "" Vector__XXX
 SG_ CP_a094_inductiveResetSuccessful m1 : 37|1@1+ (1,0) [0|0] "" Vector__XXX
 SG_ CP_a154_acChargingStoppedOT m2 : 37|1@1+ (1,0) [0|0] "" Vector__XXX
 SG_ CP_a035_latchMovement_1 m0 : 38|1@1+ (1,0) [0|0] "" Vector__XXX
 SG_ CP_a095_thermalDcLimitActive m1 : 38|1@1+ (1,0) [0|0] "" Vector__XXX
 SG_ CP_a155_hallPresenceRationality m2 : 38|1@1+ (1,0) [0|0] "" Vector__XXX
 SG_ CP_a036_latchNotDisengaged m0 : 39|1@1+ (1,0) [0|0] "" Vector__XXX
 SG_ CP_a096_pilotWake m1 : 39|1@1+ (1,0) [0|0] "" Vector__XXX
 SG_ CP_a156_gbdcPrechargingConcern m2 : 39|1@1+ (1,0) [0|0] "" Vector__XXX
 SG_ CP_a037_latchNotEngaged m0 : 40|1@1+ (1,0) [0|0] "" Vector__XXX
 SG_ CP_a097_modeTransitionFailure m1 : 40|1@1+ (1,0) [0|0] "" Vector__XXX
 SG_ CP_a157_doorOpenRateLimiter m2 : 40|1@1+ (1,0) [0|0] "" Vector__XXX
 SG_ CP_a038_latchNotBlocking m0 : 41|1@1+ (1,0) [0|0] "" Vector__XXX
 SG_ CP_a098_proximityWake m1 : 41|1@1+ (1,0) [0|0] "" Vector__XXX
 SG_ CP_a158_doorCloseRateLimiter m2 : 41|1@1+ (1,0) [0|0] "" Vector__XXX
 SG_ CP_a039_latchMovement_2 m0 : 42|1@1+ (1,0) [0|0] "" Vector__XXX
 SG_ CP_a099_cableStateUnknown m1 : 42|1@1+ (1,0) [0|0] "" Vector__XXX
 SG_ CP_a159_swcanHealthCheckFailed m2 : 42|1@1+ (1,0) [0|0] "" Vector__XXX
 SG_ CP_a040_doNotUse m0 : 43|1@1+ (1,0) [0|0] "" Vector__XXX
 SG_ CP_a100_inletHarnessIdIrrational m1 : 43|1@1+ (1,0) [0|0] "" Vector__XXX
 SG_ CP_a160_latchDisengageInDcCharge m2 : 43|1@1+ (1,0) [0|0] "" Vector__XXX
 SG_ CP_a041_doorSensorUnplugged m0 : 44|1@1+ (1,0) [0|0] "" Vector__XXX
 SG_ CP_a101_wcFoldbackActive m1 : 44|1@1+ (1,0) [0|0] "" Vector__XXX
 SG_ CP_a161_badPilotDiodeDetectedCN m2 : 44|1@1+ (1,0) [0|0] "" Vector__XXX
 SG_ CP_a042_doorAssemblyBroken m0 : 45|1@1+ (1,0) [0|0] "" Vector__XXX
 SG_ CP_a102_wcOvertempFault m1 : 45|1@1+ (1,0) [0|0] "" Vector__XXX
 SG_ CP_a162_pilotEdgeDetectionFailedCN m2 : 45|1@1+ (1,0) [0|0] "" Vector__XXX
 SG_ CP_a043_doorPotIrrational m0 : 46|1@1+ (1,0) [0|0] "" Vector__XXX
 SG_ CP_a103_proximityPeDisconnected m1 : 46|1@1+ (1,0) [0|0] "" Vector__XXX
 SG_ CP_a163_coverOpenDcChgBlocked m2 : 46|1@1+ (1,0) [0|0] "" Vector__XXX
 SG_ CP_a044_lostCommsHVP m0 : 47|1@1+ (1,0) [0|0] "" Vector__XXX
 SG_ CP_a104_uhfResetSuccessful m1 : 47|1@1+ (1,0) [0|0] "" Vector__XXX
 SG_ CP_a164_latchRedisengageRequested m2 : 47|1@1+ (1,0) [0|0] "" Vector__XXX
 SG_ CP_a045_lostCommsVCSEC m0 : 48|1@1+ (1,0) [0|0] "" Vector__XXX
 SG_ CP_a105_hwUnableToSleep m1 : 48|1@1+ (1,0) [0|0] "" Vector__XXX
 SG_ CP_a165_proxWiggleDetected m2 : 48|1@1+ (1,0) [0|0] "" Vector__XXX
 SG_ CP_a046_lostCommsEVSE m0 : 49|1@1+ (1,0) [0|0] "" Vector__XXX
 SG_ CP_a106_uhfReceiverReset m1 : 49|1@1+ (1,0) [0|0] "" Vector__XXX
 SG_ CP_a166_faultLineMismatchDetected m2 : 49|1@1+ (1,0) [0|0] "" Vector__XXX
 SG_ CP_a047_lostCommsVCFRONT m0 : 50|1@1+ (1,0) [0|0] "" Vector__XXX
 SG_ CP_a107_chademoFoldbackActive m1 : 50|1@1+ (1,0) [0|0] "" Vector__XXX
 SG_ CP_a167_doorIdIrrational m2 : 50|1@1+ (1,0) [0|0] "" Vector__XXX
 SG_ CP_a048_lostCommsUI m0 : 51|1@1+ (1,0) [0|0] "" Vector__XXX
 SG_ CP_a108_chademoOvertempFault m1 : 51|1@1+ (1,0) [0|0] "" Vector__XXX
 SG_ CP_a168_pilotHSDFaulted m2 : 51|1@1+ (1,0) [0|0] "" Vector__XXX
 SG_ CP_a049_multipleCablesDetected m0 : 52|1@1+ (1,0) [0|0] "" Vector__XXX
 SG_ CP_a109_thermistorIrrational m1 : 52|1@1+ (1,0) [0|0] "" Vector__XXX
 SG_ CP_a050_latchNotConnected m0 : 53|1@1+ (1,0) [0|0] "" Vector__XXX
 SG_ CP_a110_thermalVelocityHigh m1 : 53|1@1+ (1,0) [0|0] "" Vector__XXX
 SG_ CP_a051_doorInductiveSensorMIA m0 : 54|1@1+ (1,0) [0|0] "" Vector__XXX
 SG_ CP_a111_inletHeaterUnableToHeat m1 : 54|1@1+ (1,0) [0|0] "" Vector__XXX
 SG_ CP_a052_chademoNotSupported m0 : 55|1@1+ (1,0) [0|0] "" Vector__XXX
 SG_ CP_a112_inletHeaterIrrationalTemperature m1 : 55|1@1+ (1,0) [0|0] "" Vector__XXX
 SG_ CP_a172_triggerOdin m2 : 55|1@1+ (1,0) [0|0] "" Vector__XXX
 SG_ CP_a053_proxLatchedNoPilot m0 : 56|1@1+ (1,0) [0|0] "" Vector__XXX
 SG_ CP_a113_inletHeaterShortCircuit m1 : 56|1@1+ (1,0) [0|0] "" Vector__XXX
 SG_ CP_a173_coverOpenAcChgBlocked m2 : 56|1@1+ (1,0) [0|0] "" Vector__XXX
 SG_ CP_a054_cableNotSecured m0 : 57|1@1+ (1,0) [0|0] "" Vector__XXX
 SG_ CP_a114_ccsEvseFailed m1 : 57|1@1+ (1,0) [0|0] "" Vector__XXX
 SG_ CP_a174_fwdedMsgLoadWarning m2 : 57|1@1+ (1,0) [0|0] "" Vector__XXX
 SG_ CP_a055_chargeStoppedNoPilot m0 : 58|1@1+ (1,0) [0|0] "" Vector__XXX
 SG_ CP_a115_unexpectedTcan1145State m1 : 58|1@1+ (1,0) [0|0] "" Vector__XXX
 SG_ CP_a175_fwdedMsgDropped m2 : 58|1@1+ (1,0) [0|0] "" Vector__XXX
 SG_ CP_a056_proxDisconnected m0 : 59|1@1+ (1,0) [0|0] "" Vector__XXX
 SG_ CP_a116_misconfigurationDetected m1 : 59|1@1+ (1,0) [0|0] "" Vector__XXX
 SG_ CP_a176_lostCommsV2l m2 : 59|1@1+ (1,0) [0|0] "" Vector__XXX
 SG_ CP_a057_ccs1AdapterBtnPress m0 : 60|1@1+ (1,0) [0|0] "" Vector__XXX
 SG_ CP_a117_inletHeaterUnableToRegulate m1 : 60|1@1+ (1,0) [0|0] "" Vector__XXX
 SG_ CP_a177_incompatibleV2lDeviceDetected m2 : 60|1@1+ (1,0) [0|0] "" Vector__XXX
 SG_ CP_a058_acChargeRetryPending m0 : 61|1@1+ (1,0) [0|0] "" Vector__XXX
 SG_ CP_a118_iecComboLockUp m1 : 61|1@1+ (1,0) [0|0] "" Vector__XXX
 SG_ CP_a178_v2xPlcCommsFault m2 : 61|1@1+ (1,0) [0|0] "" Vector__XXX
 SG_ CP_a059_swcanError m0 : 62|1@1+ (1,0) [0|0] "" Vector__XXX
 SG_ CP_a119_plcTransmitFailure m1 : 62|1@1+ (1,0) [0|0] "" Vector__XXX
 SG_ CP_a179_evseCommsTlsError m2 : 62|1@1+ (1,0) [0|0] "" Vector__XXX
 SG_ CP_a060_lostCommsPCS m0 : 63|1@1+ (1,0) [0|0] "" Vector__XXX
 SG_ CP_a120_comboAdapterFoldback m1 : 63|1@1+ (1,0) [0|0] "" Vector__XXX

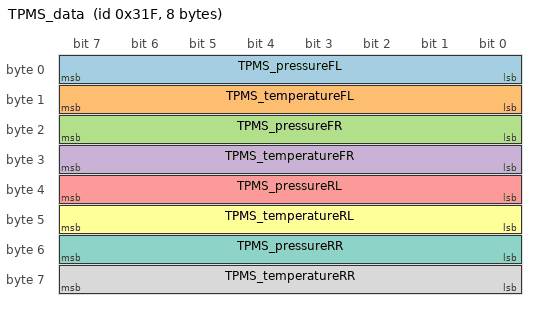
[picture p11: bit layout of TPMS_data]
BO_ 799 TPMS_data: 8 Vector__XXX
 SG_ TPMS_pressureFL : 0|8@1+ (0.025,0) [0|0] "" Vector__XXX
 SG_ TPMS_temperatureFL : 8|8@1+ (1,-40) [0|0] "" Vector__XXX
 SG_ TPMS_pressureFR : 16|8@1+ (0.025,0) [0|0] "" Vector__XXX
 SG_ TPMS_temperatureFR : 24|8@1+ (1,-40) [0|0] "" Vector__XXX
 SG_ TPMS_pressureRL : 32|8@1+ (0.025,0) [0|0] "" Vector__XXX
 SG_ TPMS_temperatureRL : 40|8@1+ (1,-40) [0|0] "" Vector__XXX
 SG_ TPMS_pressureRR : 48|8@1+ (0.025,0) [0|0] "" Vector__XXX
 SG_ TPMS_temperatureRR : 56|8@1+ (1,-40) [0|0] "" Vector__XXX

VAL_ 691 VCRIGHT_logging1HzIndex 0 "HVAC_TEMP_SENSORS_AND_ESTIMATES" 1 "HVAC_STATUS_AIRFLOW" 2 "HVAC_COMFORT_SOLAR" 3 "HEATER_AND_DUCT_TARGETS" 4 "HVAC_ACTUATOR_VOLTAGES_1" 5 "HVAC_ACTUATOR_VOLTAGES_2" 6 "HVAC_ACTUATOR_ENDSTOP_1" 7 "HVAC_ACTUATOR_ENDSTOP_2" 8 "HVAC_ACTUATOR_ZEROSTOP_1" 9 "HVAC_ACTUATOR_ZEROSTOP_2" 10 "HVAC_MISCELLANEOUS_1" 11 "HVAC_MISCELLANEOUS_2" 12 "HVAC_OPERATION_MODE" 13 "SECOND_ROW_CABIN_MODEL" 14 "END" ;
VAL_ 691 VCRIGHT_convectionTargetLeft 255 "SNA" ;
VAL_ 691 VCRIGHT_CO2ppm 1023 "SNA" ;
VAL_ 691 VCRIGHT_cabinTempGlassRoof 255 "SNA" ;
VAL_ 691 VCRIGHT_filterLifeBlowerTorque 1023 "SNA" ;
VAL_ 691 VCRIGHT_tempIncarCabinProbe 255 "SNA" ;
VAL_ 691 VCRIGHT_convectionTargetRight 255 "SNA" ;
VAL_ 691 VCRIGHT_cabinTempInteriorL2 255 "SNA" ;
VAL_ 691 VCRIGHT_cabinTempWindshield 255 "SNA" ;
VAL_ 691 VCRIGHT_convectionDeliveredLeft 255 "SNA" ;
VAL_ 691 VCRIGHT_cabinTempInterior 255 "SNA" ;
VAL_ 691 VCRIGHT_cabinTempInteriorSunnyL2 255 "SNA" ;
VAL_ 691 VCRIGHT_hvacAutoTransitionReason 0 "NONE" 1 "HUMIDITY_HIGH" 2 "HUMIDITY_MODERATE" 3 "HUMIDITY_LOW" 4 "TEMP_TARGET_BELOW_THRESHOLD" 5 "TEMP_TARGET_ABOVE_THRESHOLD" 6 "EXCESS_OCCUPANT_CONVECTION" 7 "OCCUPANT_CONVECTION_REQUIREMENT" 8 "TEMP_TARGET_LOW" 9 "DUCTS_COLD" 10 "BI_LEVEL_LANDING" 11 "DEFOG_OVERRIDE" 12 "SET_TEMP_LO" 13 "SET_TEMP_HI" 14 "CABIN_PURGE" 15 "EVAP_DRYING" 16 "EVAP_OIL_PURGE" 17 "HVAC_OFF" 18 "DUCT_TARGETS_INVALID" 19 "BIODEFENSE" 20 "END" ;
VAL_ 691 VCRIGHT_cabinTempInteriorSunny 255 "SNA" ;
VAL_ 691 VCRIGHT_convectionDeliveredRight 255 "SNA" ;
VAL_ 691 VCRIGHT_solarLoadOnVehFiltered 255 "SNA" ;
VAL_ 691 VCRIGHT_tempIncarCabinMid 250 "SNA" ;
VAL_ 691 VCRIGHT_cabinTempInteriorL3 255 "SNA" ;
VAL_ 691 VCRIGHT_cabinTempProbeEstimate 255 "SNA" ;
VAL_ 691 VCRIGHT_cabinTempSideGlassLeft 255 "SNA" ;
VAL_ 691 VCRIGHT_evapPulldownBias 255 "SNA" ;
VAL_ 691 VCRIGHT_solarLoadRightOccupant 127 "SNA" ;
VAL_ 691 VCRIGHT_hvacLHBleedOperationMode 0 "NORMAL" 1 "CALIBRATION" ;
VAL_ 691 VCRIGHT_hvacRHBleedOperationMode 0 "NORMAL" 1 "CALIBRATION" ;
VAL_ 691 VCRIGHT_hvacLHVaneOperationMode 0 "NORMAL" 1 "CALIBRATION" ;
VAL_ 691 VCRIGHT_hvacRHVaneOperationMode 0 "NORMAL" 1 "CALIBRATION" ;
VAL_ 691 VCRIGHT_cabinTempInteriorSunnyL3 255 "SNA" ;
VAL_ 691 VCRIGHT_cabinTempSideGlassRight 255 "SNA" ;
VAL_ 691 VCRIGHT_cabinTempThs 255 "SNA" ;
VAL_ 691 VCRIGHT_cabinTempWshldDefog 255 "SNA" ;
VAL_ 691 VCRIGHT_hvacUpperModeOpMode 0 "NORMAL" 1 "CALIBRATION" ;
VAL_ 691 VCRIGHT_solarLoadLeftOccupant 127 "SNA" ;
VAL_ 691 VCRIGHT_hvacLowerModeOpMode 0 "NORMAL" 1 "CALIBRATION" ;
VAL_ 691 VCRIGHT_hvacIntakeOperationMode 0 "NORMAL" 1 "CALIBRATION" ;
VAL_ 691 VCRIGHT_cabinTempBreathLevel 255 "SNA" ;
VAL_ 691 VCRIGHT_cabinTempThsBracket 255 "SNA" ;
VAL_ 691 VCRIGHT_cabinTempWshldDefogTop 255 "SNA" ;
VAL_ 691 VCRIGHT_solarLoadFromThsTemp 255 "SNA" ;
VAL_ 694 DI_vdcTelltaleFlash 0 "OFF" 1 "ON" ;
VAL_ 694 DI_vdcTelltaleOn 0 "OFF" 1 "ON" ;
VAL_ 694 DI_tcTelltaleFlash 0 "OFF" 1 "ON" ;
VAL_ 694 DI_tcTelltaleOn 0 "OFF" 1 "ON" ;
VAL_ 694 DI_tractionControlModeUI 0 "NORMAL" 1 "SLIP_START" 2 "DEV_MODE_1" 3 "DEV_MODE_2" 4 "ROLLS_MODE" 5 "DYNO_MODE" 6 "OFFROAD_ASSIST" ;
VAL_ 694 DI_ptcStateGlobalUI 0 "FAULTED" 1 "BACKUP" 2 "ON" 3 "SNA" ;
VAL_ 694 DI_btcStateUI 0 "OFF" 1 "ON" ;
VAL_ 694 DI_vehicleHoldTelltaleOn 0 "OFF" 1 "ON" ;
VAL_ 702 FC_powerLimit_value 4294934528 "SNA" ;
VAL_ 702 FC_currentLimit_value 4294934528 "SNA" ;
VAL_ 702 FC_minVoltageLimit_value 4294934528 "SNA" ;
VAL_ 705 VCFRONT_logging10HzIndex 0 "COOLANT_PUMPS" 1 "THERMAL_FAN" 2 "COOLANT_VALVE" 3 "COMPRESSOR_REFRIGERANT" 4 "ACTIVE_LOUVER" 5 "HP_CONTROLLER" 6 "RADAR_HEATER" 7 "EXV_TORQUE_COUNT" 8 "END" ;
VAL_ 706 VCLEFT_windowStatusIndex 0 "Mux0" 1 "Mux1" ;
VAL_ 706 VCLEFT_windowStateLF 0 "STOPPED" 1 "MOVING_UP" 2 "MOVING_DOWN" 3 "BACKOFF" 4 "SHORT_DROP" 5 "SHORT_DROP_REVERSE" 6 "MOVING_AUTO_UP" 7 "MOVING_AUTO_DOWN" 8 "BACKDRIVE" ;
VAL_ 706 VCLEFT_windowThermalModeLF 0 "SNA" 1 "NORMAL" 2 "ALERT" 3 "CRITICAL" ;
VAL_ 706 VCLEFT_windowStopReasonLF 0 "NONE" 1 "DOOR_OPEN_TRIM_PROTECT" 2 "NEW_REQUEST" 3 "TARGET_REACHED" 4 "STOP_REQUEST" 5 "FULL_OPEN_SOFT_STOP" 6 "STATE_TIMEOUT" ;
VAL_ 706 VCLEFT_windowStopReqReasonLF 0 "NONE" 1 "SWITCH_CANCEL_AUTO_MOVEMENT" 2 "SWITCH_RELEASED" 3 "REAR_LOCKOUT" 4 "THERMAL" 5 "STALL" 6 "STATE_TIMEOUT" 7 "FULL_OPEN_SOFT_STOP" 8 "EXTERNAL_REQUEST" ;
VAL_ 706 VCLEFT_windowThermalModeLR 0 "SNA" 1 "NORMAL" 2 "ALERT" 3 "CRITICAL" ;
VAL_ 706 VCLEFT_windowStopReasonLR 0 "NONE" 1 "DOOR_OPEN_TRIM_PROTECT" 2 "NEW_REQUEST" 3 "TARGET_REACHED" 4 "STOP_REQUEST" 5 "FULL_OPEN_SOFT_STOP" 6 "STATE_TIMEOUT" ;
VAL_ 706 VCLEFT_windowStopReqReasonLR 0 "NONE" 1 "SWITCH_CANCEL_AUTO_MOVEMENT" 2 "SWITCH_RELEASED" 3 "REAR_LOCKOUT" 4 "THERMAL" 5 "STALL" 6 "STATE_TIMEOUT" 7 "FULL_OPEN_SOFT_STOP" 8 "EXTERNAL_REQUEST" ;
VAL_ 706 VCLEFT_windowStateLR 0 "STOPPED" 1 "MOVING_UP" 2 "MOVING_DOWN" 3 "BACKOFF" 4 "SHORT_DROP" 5 "SHORT_DROP_REVERSE" 6 "MOVING_AUTO_UP" 7 "MOVING_AUTO_DOWN" 8 "BACKDRIVE" ;
VAL_ 706 VCLEFT_windowControlStateLF 0 "IDLE" 1 "CLOSING" 2 "GOING_TO_POSITION" ;
VAL_ 706 VCLEFT_windowCtrlUnavailableLF 0 "NONE" 1 "UNEXPECTED" 2 "SWITCH_PRESSED" 3 "PINCH" 4 "THERMAL_LIMIT" 5 "UNCALIBRATED" 6 "VEHICLE_IN_DRIVE" 7 "WINDOW_MOVING" ;
VAL_ 706 VCLEFT_windowControlStateLR 0 "IDLE" 1 "CLOSING" 2 "GOING_TO_POSITION" ;
VAL_ 706 VCLEFT_windowCtrlUnavailableLR 0 "NONE" 1 "UNEXPECTED" 2 "SWITCH_PRESSED" 3 "PINCH" 4 "THERMAL_LIMIT" 5 "UNCALIBRATED" 6 "VEHICLE_IN_DRIVE" 7 "WINDOW_MOVING" ;
VAL_ 706 VCLEFT_windowPositionStateLF 0 "UNKNOWN" 1 "CLOSED" 2 "CRACKED" 3 "VENT" 4 "PARTIAL_OPEN" 5 "FULL_OPEN" 6 "CLOSED_TRIM_CLEAR" ;
VAL_ 706 VCLEFT_windowPositionStateLR 0 "UNKNOWN" 1 "CLOSED" 2 "CRACKED" 3 "VENT" 4 "PARTIAL_OPEN" 5 "FULL_OPEN" 6 "CLOSED_TRIM_CLEAR" ;
VAL_ 707 VCRIGHT_windowStatusIndex 0 "Mux0" 1 "Mux1" ;
VAL_ 707 VCRIGHT_windowStateRF 0 "STOPPED" 1 "MOVING_UP" 2 "MOVING_DOWN" 3 "BACKOFF" 4 "SHORT_DROP" 5 "SHORT_DROP_REVERSE" 6 "MOVING_AUTO_UP" 7 "MOVING_AUTO_DOWN" 8 "BACKDRIVE" ;
VAL_ 707 VCRIGHT_windowThermalModeRF 0 "SNA" 1 "NORMAL" 2 "ALERT" 3 "CRITICAL" ;
VAL_ 707 VCRIGHT_windowStopReasonRF 0 "NONE" 1 "DOOR_OPEN_TRIM_PROTECT" 2 "NEW_REQUEST" 3 "TARGET_REACHED" 4 "STOP_REQUEST" 5 "FULL_OPEN_SOFT_STOP" 6 "STATE_TIMEOUT" ;
VAL_ 707 VCRIGHT_windowStopReqReasonRF 0 "NONE" 1 "SWITCH_CANCEL_AUTO_MOVEMENT" 2 "SWITCH_RELEASED" 3 "REAR_LOCKOUT" 4 "THERMAL" 5 "STALL" 6 "STATE_TIMEOUT" 7 "FULL_OPEN_SOFT_STOP" 8 "EXTERNAL_REQUEST" ;
VAL_ 707 VCRIGHT_windowThermalModeRR 0 "SNA" 1 "NORMAL" 2 "ALERT" 3 "CRITICAL" ;
VAL_ 707 VCRIGHT_windowStopReasonRR 0 "NONE" 1 "DOOR_OPEN_TRIM_PROTECT" 2 "NEW_REQUEST" 3 "TARGET_REACHED" 4 "STOP_REQUEST" 5 "FULL_OPEN_SOFT_STOP" 6 "STATE_TIMEOUT" ;
VAL_ 707 VCRIGHT_windowStopReqReasonRR 0 "NONE" 1 "SWITCH_CANCEL_AUTO_MOVEMENT" 2 "SWITCH_RELEASED" 3 "REAR_LOCKOUT" 4 "THERMAL" 5 "STALL" 6 "STATE_TIMEOUT" 7 "FULL_OPEN_SOFT_STOP" 8 "EXTERNAL_REQUEST" ;
VAL_ 707 VCRIGHT_windowStateRR 0 "STOPPED" 1 "MOVING_UP" 2 "MOVING_DOWN" 3 "BACKOFF" 4 "SHORT_DROP" 5 "SHORT_DROP_REVERSE" 6 "MOVING_AUTO_UP" 7 "MOVING_AUTO_DOWN" 8 "BACKDRIVE" ;
VAL_ 707 VCRIGHT_windowControlStateRF 0 "IDLE" 1 "CLOSING" 2 "GOING_TO_POSITION" ;
VAL_ 707 VCRIGHT_windowCtrlUnavailableRF 0 "NONE" 1 "UNEXPECTED" 2 "SWITCH_PRESSED" 3 "PINCH" 4 "THERMAL_LIMIT" 5 "UNCALIBRATED" 6 "VEHICLE_IN_DRIVE" 7 "WINDOW_MOVING" ;
VAL_ 707 VCRIGHT_windowControlStateRR 0 "IDLE" 1 "CLOSING" 2 "GOING_TO_POSITION" ;
VAL_ 707 VCRIGHT_windowCtrlUnavailableRR 0 "NONE" 1 "UNEXPECTED" 2 "SWITCH_PRESSED" 3 "PINCH" 4 "THERMAL_LIMIT" 5 "UNCALIBRATED" 6 "VEHICLE_IN_DRIVE" 7 "WINDOW_MOVING" ;
VAL_ 707 VCRIGHT_windowPositionStateRF 0 "UNKNOWN" 1 "CLOSED" 2 "CRACKED" 3 "VENT" 4 "PARTIAL_OPEN" 5 "FULL_OPEN" 6 "CLOSED_TRIM_CLEAR" ;
VAL_ 707 VCRIGHT_windowPositionStateRR 0 "UNKNOWN" 1 "CLOSED" 2 "CRACKED" 3 "VENT" 4 "PARTIAL_OPEN" 5 "FULL_OPEN" 6 "CLOSED_TRIM_CLEAR" ;
VAL_ 708 PCS_logMessageSelect 0 "PHA_1" 1 "PHB_1" 2 "PHC_1" 3 "CHG_1" 4 "CHG_2" 5 "CHG_3" 6 "DCDC_1" 7 "DCDC_2" 8 "DCDC_3" 9 "SYSTEM_1" 10 "PHA_2" 11 "PHB_2" 12 "PHC_2" 13 "CHG_4" 14 "DLOG_1" 15 "DLOG_2" 16 "DLOG_3" 17 "DLOG_4" 18 "DCDC_4" 19 "DCDC_5" 20 "CHG_NO_FLOW" 21 "CHG_LINE_OFFSET" 22 "DCDC_STATISTICS" 23 "CHG_MACHINEMODEL" 24 "DCDC_HVBUS_PCHG_DATA" 25 "DCDC_IMPEDANCE_EST" 26 "PROCESSOR_DIE_ID" 27 "NUM_MSGS" ;
VAL_ 708 PCS_chgInputFrequencyL1N 0 "FREQUENCY_UNKNOWN" ;
VAL_ 708 PCS_chgPhAState 0 "INIT" 1 "IDLE" 2 "PRECHARGE" 3 "ENABLE" 4 "FAULT" 5 "CLEAR_FAULTS" 6 "SHUTTING_DOWN" ;
VAL_ 708 PCS_cpu2BootState 0 "BOOTROM" 1 "BOOTLOADER" 2 "APPLICATION" 3 "ERROR" ;
VAL_ 708 PCS_acChargeSelfTestState 0 "IDLE" 1 "STARTED" ;
VAL_ 708 PCS_chgPhBState 0 "INIT" 1 "IDLE" 2 "PRECHARGE" 3 "ENABLE" 4 "FAULT" 5 "CLEAR_FAULTS" 6 "SHUTTING_DOWN" ;
VAL_ 708 PCS_chgPhCState 0 "INIT" 1 "IDLE" 2 "PRECHARGE" 3 "ENABLE" 4 "FAULT" 5 "CLEAR_FAULTS" 6 "SHUTTING_DOWN" ;
VAL_ 708 PCS_chgInputFrequencyL2N 0 "FREQUENCY_UNKNOWN" ;
VAL_ 708 PCS_chgPhALastShutdownReason 0 "REASON_NONE" 1 "SW_ENABLE" 2 "HW_ENABLE" 3 "SW_FAULT" 4 "HW_FAULT" 5 "PLL_NOT_LOCKED" 6 "INPUT_UV" 7 "INPUT_OV" 8 "OUTPUT_UV" 9 "OUTPUT_OV" 10 "PRECHARGE_TIMEOUT" 11 "INT_BUS_UV" 12 "CONTROL_REGULATION_FAULT" 13 "OVER_TEMPERATURE" 14 "TEMP_IRRATIONAL" 15 "SENSOR_IRRATIONAL" 16 "FREQ_OUT_OF_RANGE" 17 "LINE_TRANSIENT_FAULT" ;
VAL_ 708 PCS_chgPhBLastShutdownReason 0 "REASON_NONE" 1 "SW_ENABLE" 2 "HW_ENABLE" 3 "SW_FAULT" 4 "HW_FAULT" 5 "PLL_NOT_LOCKED" 6 "INPUT_UV" 7 "INPUT_OV" 8 "OUTPUT_UV" 9 "OUTPUT_OV" 10 "PRECHARGE_TIMEOUT" 11 "INT_BUS_UV" 12 "CONTROL_REGULATION_FAULT" 13 "OVER_TEMPERATURE" 14 "TEMP_IRRATIONAL" 15 "SENSOR_IRRATIONAL" 16 "FREQ_OUT_OF_RANGE" 17 "LINE_TRANSIENT_FAULT" ;
VAL_ 708 PCS_dcdcTankVoltage 4294966272 "TANK_VOLTAGE_SNA" ;
VAL_ 708 PCS_chgPhCLastShutdownReason 0 "REASON_NONE" 1 "SW_ENABLE" 2 "HW_ENABLE" 3 "SW_FAULT" 4 "HW_FAULT" 5 "PLL_NOT_LOCKED" 6 "INPUT_UV" 7 "INPUT_OV" 8 "OUTPUT_UV" 9 "OUTPUT_OV" 10 "PRECHARGE_TIMEOUT" 11 "INT_BUS_UV" 12 "CONTROL_REGULATION_FAULT" 13 "OVER_TEMPERATURE" 14 "TEMP_IRRATIONAL" 15 "SENSOR_IRRATIONAL" 16 "FREQ_OUT_OF_RANGE" 17 "LINE_TRANSIENT_FAULT" ;
VAL_ 708 PCS_chgInputFrequencyL3N 0 "FREQUENCY_UNKNOWN" ;
VAL_ 708 PCS_chgPhAInputCurrentLimitReason 0 "NONE" 1 "RIPPLE_RELAXED" 2 "OUTPUT_POWER" 3 "INPUT_POWER" 4 "PHASE_THERMAL_LIMIT" 5 "PHASE_MACHINE_MODEL" ;
VAL_ 708 PCS_chgPhBInputCurrentLimitReason 0 "NONE" 1 "RIPPLE_RELAXED" 2 "OUTPUT_POWER" 3 "INPUT_POWER" 4 "PHASE_THERMAL_LIMIT" 5 "PHASE_MACHINE_MODEL" ;
VAL_ 708 PCS_chgPhCInputCurrentLimitReason 0 "NONE" 1 "RIPPLE_RELAXED" 2 "OUTPUT_POWER" 3 "INPUT_POWER" 4 "PHASE_THERMAL_LIMIT" 5 "PHASE_MACHINE_MODEL" ;
VAL_ 708 PCS_chgInternalPhaseConfig 0 "SNA" 1 "SINGLE_PHASE" 2 "THREE_PHASE" 3 "THREE_PHASE_DELTA" 4 "SINGLE_PHASE_IEC_GB" 5 "MFG_TEST_CONFIG_1" 6 "MFG_TEST_CONFIG_2" 7 "SINGLE_PHASE_BRIDGED_HARNESS" 8 "SINGLE_PHASE_EVSE_PARALLEL" 9 "TOTAL_NUM" ;
VAL_ 708 PCS_chgAcpwHeartbeatState 0 "UNKNOWN" 1 "NOT_DETECTED" 2 "DETECTED_OFFGRID" 3 "DETECTED_ONGRID" 4 "NUM" ;
VAL_ 708 PCS_chgPhasesPriority 0 "UNDEFINED_PHASES_PRIORITY" 6 "PHASES_PRIORITY_CBA" 9 "PHASES_PRIORITY_BCA" 18 "PHASES_PRIORITY_CAB" 24 "PHASES_PRIORITY_ACB" 33 "PHASES_PRIORITY_BAC" 36 "PHASES_PRIORITY_ABC" ;
VAL_ 723 UI_solarAzimuthAngle 4294934528 "SNA" ;
VAL_ 723 UI_solarAzimuthAngleCarRef 255 "SNA" ;
VAL_ 723 UI_isSunUp 0 "DOWN" 1 "UP" 3 "SNA" ;
VAL_ 723 UI_solarElevationAngle 127 "SNA" ;
VAL_ 723 UI_screenPCBTemperature 2047 "GTW_I2C_TEMP_SNA" ;
VAL_ 727 VCLEFT_pitchEstimate 4294967232 "SNA" ;
VAL_ 728 ICR_nmKeepAwakeReason 0 "NONE_SNA" 1 "CTRS_CLOSED" 2 "CRITICAL_ALERT" 3 "FC_CTR_CLEANING" 4 "HVP_ACTIVE" 5 "BMS_ACTIVE" 6 "CP_ACTIVE" ;
VAL_ 728 ICR_nmWakeUpReason 0 "NONE" 1 "CAN_VEH" 2 "CAN_HVS" 3 "WANTTOCHARGE" 4 "CRITICALALERT" 5 "WANTTOWARM" ;
VAL_ 737 VCFRONT_statusIndex 0 "BODY_CONTROLS" 1 "VEHICLE_STATE" 2 "HOMELINK" 3 "REFRIGERANT_SYSTEM" 4 "SYSTEM_HEALTH" 5 "INVALID" ;
VAL_ 737 VCFRONT_frunkLatchStatus 0 "SNA" 1 "OPENED" 2 "CLOSED" 3 "CLOSING" 4 "OPENING" 5 "AJAR" 6 "TIMEOUT" 7 "DEFAULT" 8 "FAULT" ;
VAL_ 737 VCFRONT_iBoosterStateDBG 0 "OFF" 1 "ON" 2 "GOING_DOWN" 3 "WRITING_DATA_SHUTDOWN" 4 "FORCE_OFF" ;
VAL_ 737 VCFRONT_vehicleStatusDBG 0 "INIT" 1 "LOW_POWER_AWAKE" 2 "CONDITIONING" 3 "ACCESSORY" 4 "ACCESSORY_PLUS" 5 "DRIVE" 6 "OTA" 7 "WAIT_FOR_HIGH_POWER" 8 "TURN_ON_LV" 9 "SYSTEM_CHECKS" 10 "LV_ON" 11 "JUMP_START" 12 "LV_SHUTDOWN" 13 "GO_QUIET" 14 "SLEEP_SHUTDOWN" 15 "LOW_POWER_STANDBY" 16 "RESET" ;
VAL_ 737 VCFRONT_wiperSpeed 0 "SNA" 1 "OFF" 2 "1" 3 "2" 4 "3" 5 "4" 6 "5" 7 "LOW" 8 "HIGH" ;
VAL_ 737 VCFRONT_wiperPosition 0 "SNA" 1 "SERVICE" 2 "DEPRESSED_PARK" 3 "DELAYED_REST" 4 "WIPING" ;
VAL_ 737 VCFRONT_vbatMonitorVoltage 4095 "SNA" ;
VAL_ 737 VCFRONT_wiperState 0 "SNA" 1 "SERVICE" 2 "FAULT" 3 "DELAYED_REST" 4 "PARK" 5 "WASH" 6 "MOMENTARY_WIPE" 7 "INTERMITTENT_HIGH" 8 "INTERMITTENT_LOW" 9 "CONT_FAST" 10 "CONT_SLOW" 11 "INT_AUTO_LOW" 12 "INT_AUTO_HIGH" ;
VAL_ 737 VCFRONT_crashDetectedType 0 "NONE" 1 "MINOR_1" 2 "MINOR_2" 3 "SEVERE" ;
VAL_ 737 VCFRONT_crashState 0 "IDLE" 1 "MINOR_1" 2 "MINOR_2" 3 "SEVERE" ;
VAL_ 737 VCFRONT_sleepCurrent 4095 "SNA" ;
VAL_ 737 VCFRONT_AS8510Voltage 4095 "SNA" ;
VAL_ 737 VCFRONT_pressureRefrigSuction 127 "SNA" ;
VAL_ 737 VCFRONT_hibernationState 0 "INIT" 1 "NOT_ACTIVE" 2 "ACTIVE" 3 "RECOVERY" 4 "EXIT" 5 "PREP" ;
VAL_ 737 VCFRONT_pressureRefrigDischarge 511 "SNA" ;
VAL_ 737 VCFRONT_closureEasterEggState 0 "IDLE" 1 "ISOTP_RX" 2 "WAITING_FOR_ACTIVE_LOCK" 3 "SHOW_SETUP" 4 "WAITING_FOR_SYNC_PULSE" 5 "PLAY" 6 "SHOW_CLEANUP" ;
VAL_ 737 VCFRONT_hvacPerfTestCommand 0 "NOT_STARTED" 1 "INIT" 2 "BLOW" 3 "BLOW_BILEVEL" 4 "STOP" ;
VAL_ 737 VCFRONT_coolantFillRoutineStatus 0 "NOT_READY" 1 "MOVING_TO_FILL_POSITION" 2 "READY_TO_FILL" 3 "FAULTED" ;
VAL_ 737 VCFRONT_radarHeaterState 0 "SNA" 1 "ON" 2 "OFF" 3 "OFF_UNAVAILABLE" 4 "FAULT" ;
VAL_ 737 VCFRONT_refrigFillRoutineStatus 0 "NOT_READY" 1 "MOVING_TO_FILL_POSITION" 2 "READY_TO_FILL" 3 "FAULTED" ;
VAL_ 737 VCFRONT_closeValvesRoutineStatus 0 "NOT_READY" 1 "MOVING_TO_FILL_POSITION" 2 "READY_TO_FILL" 3 "FAULTED" ;
VAL_ 737 VCFRONT_passengerBuckleStatus 0 "UNBUCKLED" 1 "BUCKLED" ;
VAL_ 737 VCFRONT_frunkLatchType 0 "UNKNOWN" 1 "DOUBLE_ACTUATOR" 2 "DOUBLE_PULL" ;
VAL_ 738 VCLEFT_seatStatus2Index 0 "SEAT_HEAT_FRONT" 1 "SEAT_HEAT_REARL_BACKREST" 2 "OCCUPANCY" 3 "SEAT_HEAT_REARL" 4 "SEAT_HEAT_REARC" 5 "SEAT_HEAT_REARR_CUSHION" 6 "SEAT_2ROW_ACTUATOR" 7 "SEAT_SWITCH_VOLTAGES_1" 8 "SEAT_SWITCH_VOLTAGES_2" 9 "SEAT_2ROW_EASY_ENTRY" 10 "SEAT_STATUS_2_INDEX_COUNT" ;
VAL_ 738 VCLEFT_frontSeatHeatTmp 0 "SNA" ;
VAL_ 738 VCLEFT_frontSeatHeatTmpTarget 0 "OFF" ;
VAL_ 739 VCRIGHT_seatStatus2Index 0 "SEAT_HEAT_FRONT" 1 "SEAT_HEAT_REARL_CUSHION" 2 "SEAT_HEAT_REARC" 3 "SEAT_HEAT_REARR" 4 "OCCUPANCY" 5 "SEAT_HEAT_REARR_BACKREST" 6 "SEAT_2ROW_ACTUATOR" 7 "SEAT_SWITCH_VOLTAGES_1" 8 "SEAT_SWITCH_VOLTAGES_2" 9 "SEAT_2ROW_EASY_ENTRY" 10 "OCS_IEE" 11 "SEAT_STATUS_2_INDEX_COUNT" ;
VAL_ 739 VCRIGHT_frontSeatHeatTmp 0 "SNA" ;
VAL_ 739 VCRIGHT_frontSeatHeatTmpTarget 0 "OFF" ;
VAL_ 740 PCS2_logMessageSelect 0 "PHA_1" 1 "PHB_1" 2 "PHC_1" 3 "CHG_1" 4 "CHG_2" 5 "CHG_3" 6 "DCDC_1" 7 "DCDC_2" 8 "DCDC_3" 9 "SYSTEM_1" 10 "PHA_2" 11 "PHB_2" 12 "PHC_2" 13 "CHG_4" 14 "DLOG_1" 15 "DLOG_2" 16 "DLOG_3" 17 "DLOG_4" 18 "DCDC_4" 19 "DCDC_5" 20 "CHG_NO_FLOW" 21 "CHG_LINE_OFFSET" 22 "DCDC_STATISTICS" 23 "CHG_MACHINEMODEL" 24 "DCDC_HVBUS_PCHG_DATA" 25 "DCDC_IMPEDANCE_EST" 26 "PROCESSOR_DIE_ID" 27 "NUM_MSGS" ;
VAL_ 740 PCS2_lite_ambientTemp 4294966273 "SNA" ;
VAL_ 740 PCS2_lite_boost_duty 127 "SNA" ;
VAL_ 740 PCS2_ambientTemp 4294966273 "SNA" ;
VAL_ 740 PCS2_lite_buck_duty 127 "SNA" ;
VAL_ 741 DIF_elecPower 4294966272 "SNA" ;
VAL_ 741 DIF_drivePowerMax 511 "SNA" ;
VAL_ 744 EPBR_systemStatus 0 "UNKNOWN" 1 "RELEASED" 2 "PARKED" 3 "DYNAMIC" 4 "PARKING" 5 "RELEASING" 6 "FAULT" 7 "FAULT_SECURE" 8 "MISMATCH" ;
VAL_ 744 EPBR_freeRollModeStatus 0 "UNAVAILABLE" 1 "AVAILABLE" 2 "ENABLED" ;
VAL_ 744 EPBR_telltale 0 "LAMP_OFF" 1 "LAMP_RED_ON" 2 "LAMP_AMBER_ON" 3 "LAMP_RED_FLASH" 7 "SNA" ;
VAL_ 744 EPBR_cdpRequest 0 "NOT_REQUESTED" 1 "REQUESTED" ;
VAL_ 744 EPBR_brakeDiscWipeRequest 0 "NONE" 1 "LIGHT" 2 "STRONG" 3 "SNA" ;
VAL_ 753 VCFRONT_eFuseDebugStatusIndex 0 "VCRIGHT" 1 "PCS" 2 "IBOOSTER" 3 "EPAS3S" 4 "UNUSED_1" 5 "UNUSED_2" 6 "DRIVE_INVERTER" 7 "AUTOPILOT_2" 8 "MCU" 9 "HEADLAMP" 10 "VBAT_FUSED_HIGH_CURRENT" 11 "THERMALS_AND_MOTORS" 12 "RAILS_A_B" 13 "MISC_RAILS" 14 "STEERING_FEEDBACK" 15 "BRIDGE" 16 "INVALID" ;
VAL_ 753 VCFRONT_EPAS3PState 0 "OFF" 1 "ON" 2 "LOCKED_OUT" ;
VAL_ 753 VCFRONT_EPAS3SState 0 "OFF" 1 "ON" 2 "LOCKED_OUT" ;
VAL_ 753 VCFRONT_ESPMotorState 0 "OFF" 1 "ON" 2 "LOCKED_OUT" ;
VAL_ 753 VCFRONT_ESPValveState 0 "OFF" 1 "ON" 2 "LOCKED_OUT" ;
VAL_ 753 VCFRONT_PCSState 0 "OFF" 1 "ON" 2 "LOCKED_OUT" ;
VAL_ 753 VCFRONT_autopilot1State 0 "OFF" 1 "ON" 2 "LOCKED_OUT" ;
VAL_ 753 VCFRONT_autopilot2State 0 "OFF" 1 "ON" 2 "LOCKED_OUT" ;
VAL_ 753 VCFRONT_iBoosterState 0 "OFF" 1 "ON" 2 "LOCKED_OUT" ;
VAL_ 753 VCFRONT_leftControllerState 0 "OFF" 1 "ON" 2 "LOCKED_OUT" ;
VAL_ 753 VCFRONT_vbatFusedSelfTestResult 0 "NOT_RUN" 1 "RUNNING" 2 "PASSED" 3 "FAILED_RAILS_UNSTABLE" 4 "FAILED_EFUSE_OUTPUT_SHORT" 5 "FAILED_POWER_FET_STUCK_ON" 6 "FAILED_ENABLE_LOW_MALFUNCTION" 7 "FAILED_POWER_FET_CHANNEL_OPEN" 8 "FAILED_ENABLE_HIGH_MALFUNCTION" 9 "FAILED_TURN_OFF_PATH_TOO_SLOW" 10 "FAILED_NOT_LATCHED" 11 "SKIPPED" ;
VAL_ 753 VCFRONT_EPAS3PSelfTestResult 0 "NOT_RUN" 1 "RUNNING" 2 "PASSED" 3 "FAILED_RAILS_UNSTABLE" 4 "FAILED_EFUSE_OUTPUT_SHORT" 5 "FAILED_POWER_FET_STUCK_ON" 6 "FAILED_ENABLE_LOW_MALFUNCTION" 7 "FAILED_POWER_FET_CHANNEL_OPEN" 8 "FAILED_ENABLE_HIGH_MALFUNCTION" 9 "FAILED_TURN_OFF_PATH_TOO_SLOW" 10 "FAILED_NOT_LATCHED" 11 "SKIPPED" ;
VAL_ 753 VCFRONT_EPAS3SSelfTestResult 0 "NOT_RUN" 1 "RUNNING" 2 "PASSED" 3 "FAILED_RAILS_UNSTABLE" 4 "FAILED_EFUSE_OUTPUT_SHORT" 5 "FAILED_POWER_FET_STUCK_ON" 6 "FAILED_ENABLE_LOW_MALFUNCTION" 7 "FAILED_POWER_FET_CHANNEL_OPEN" 8 "FAILED_ENABLE_HIGH_MALFUNCTION" 9 "FAILED_TURN_OFF_PATH_TOO_SLOW" 10 "FAILED_NOT_LATCHED" 11 "SKIPPED" ;
VAL_ 753 VCFRONT_ESPMotorSelfTestResult 0 "NOT_RUN" 1 "RUNNING" 2 "PASSED" 3 "FAILED_RAILS_UNSTABLE" 4 "FAILED_EFUSE_OUTPUT_SHORT" 5 "FAILED_POWER_FET_STUCK_ON" 6 "FAILED_ENABLE_LOW_MALFUNCTION" 7 "FAILED_POWER_FET_CHANNEL_OPEN" 8 "FAILED_ENABLE_HIGH_MALFUNCTION" 9 "FAILED_TURN_OFF_PATH_TOO_SLOW" 10 "FAILED_NOT_LATCHED" 11 "SKIPPED" ;
VAL_ 753 VCFRONT_iBoosterSelfTestResult 0 "NOT_RUN" 1 "RUNNING" 2 "PASSED" 3 "FAILED_RAILS_UNSTABLE" 4 "FAILED_EFUSE_OUTPUT_SHORT" 5 "FAILED_POWER_FET_STUCK_ON" 6 "FAILED_ENABLE_LOW_MALFUNCTION" 7 "FAILED_POWER_FET_CHANNEL_OPEN" 8 "FAILED_ENABLE_HIGH_MALFUNCTION" 9 "FAILED_TURN_OFF_PATH_TOO_SLOW" 10 "FAILED_NOT_LATCHED" 11 "SKIPPED" ;
VAL_ 753 VCFRONT_pcsSelfTestResult 0 "NOT_RUN" 1 "RUNNING" 2 "PASSED" 3 "FAILED_RAILS_UNSTABLE" 4 "FAILED_EFUSE_OUTPUT_SHORT" 5 "FAILED_POWER_FET_STUCK_ON" 6 "FAILED_ENABLE_LOW_MALFUNCTION" 7 "FAILED_POWER_FET_CHANNEL_OPEN" 8 "FAILED_ENABLE_HIGH_MALFUNCTION" 9 "FAILED_TURN_OFF_PATH_TOO_SLOW" 10 "FAILED_NOT_LATCHED" 11 "SKIPPED" ;
VAL_ 753 VCFRONT_vcleftSelfTestResult 0 "NOT_RUN" 1 "RUNNING" 2 "PASSED" 3 "FAILED_RAILS_UNSTABLE" 4 "FAILED_EFUSE_OUTPUT_SHORT" 5 "FAILED_POWER_FET_STUCK_ON" 6 "FAILED_ENABLE_LOW_MALFUNCTION" 7 "FAILED_POWER_FET_CHANNEL_OPEN" 8 "FAILED_ENABLE_HIGH_MALFUNCTION" 9 "FAILED_TURN_OFF_PATH_TOO_SLOW" 10 "FAILED_NOT_LATCHED" 11 "SKIPPED" ;
VAL_ 753 VCFRONT_vcrightSelfTestResult 0 "NOT_RUN" 1 "RUNNING" 2 "PASSED" 3 "FAILED_RAILS_UNSTABLE" 4 "FAILED_EFUSE_OUTPUT_SHORT" 5 "FAILED_POWER_FET_STUCK_ON" 6 "FAILED_ENABLE_LOW_MALFUNCTION" 7 "FAILED_POWER_FET_CHANNEL_OPEN" 8 "FAILED_ENABLE_HIGH_MALFUNCTION" 9 "FAILED_TURN_OFF_PATH_TOO_SLOW" 10 "FAILED_NOT_LATCHED" 11 "SKIPPED" ;
VAL_ 754 BMS_nmKeepAwakeReason 0 "NONE_SNA" 1 "CTRS_CLOSED" 2 "CRITICAL_ALERT" 3 "FC_CTR_CLEANING" 4 "HVP_ACTIVE" 5 "BMS_ACTIVE" 6 "CP_ACTIVE" ;
VAL_ 754 BMS_nmWakeUpReason 0 "NONE" 1 "CAN_VEH" 2 "CAN_HVS" 3 "WANTTOCHARGE" 4 "CRITICALALERT" 5 "WANTTOWARM" ;
VAL_ 755 UI_hvacReqTempSetpointLeft 0 "LO" 26 "HI" ;
VAL_ 755 UI_hvacReqTempSetpointRight 0 "LO" 26 "HI" ;
VAL_ 755 UI_hvacReqAirDistributionMode 0 "AUTO" 1 "MANUAL_FLOOR" 2 "MANUAL_PANEL" 3 "MANUAL_PANEL_FLOOR" 4 "MANUAL_DEFROST" 5 "MANUAL_DEFROST_FLOOR" 6 "MANUAL_DEFROST_PANEL" 7 "MANUAL_DEFROST_PANEL_FLOOR" ;
VAL_ 755 UI_hvacReqBlowerSegment 0 "OFF" 1 "1" 2 "2" 3 "3" 4 "4" 5 "5" 6 "6" 7 "7" 8 "8" 9 "9" 10 "10" 11 "AUTO" ;
VAL_ 755 UI_hvacReqRecirc 0 "AUTO" 1 "RECIRC" 2 "FRESH" ;
VAL_ 755 UI_hvacReqACDisable 0 "AUTO" 1 "OFF" 2 "ON" ;
VAL_ 755 UI_hvacReqUserPowerState 0 "OFF" 1 "ON" 2 "PRECONDITION" 3 "OVERHEAT_PROTECT_FANONLY" 4 "OVERHEAT_PROTECT" ;
VAL_ 755 UI_hvacReqSecondRowState 0 "AUTO" 1 "OFF" 2 "LOW" 3 "MED" 4 "HIGH" ;
VAL_ 755 UI_hvacReqKeepClimateOn 0 "OFF" 1 "ON" 2 "DOG" 3 "PARTY" ;
VAL_ 761 VCSEC_bleDisconnectionReason 0 "UNKNOWN_REASON_0" 5 "AUTHENTICATION_FAILURE" 8 "CONNECTION_SUPERVISION_TIMEOUT" 19 "REMOTE_USER_TERMINATED" 20 "REMOTE_DEVICE_LOW_RESOURCES" 21 "REMOTE_DEVICE_POWER_OFF" 22 "HOST_REQUESTED_TERMINATION" 26 "UNSUPPORTED_REMOTE_FEATURE" 34 "CONTROL_PACKET_TIMEOUT" 40 "CONTROL_PACKET_INSTANT_PASSED" 41 "KEY_PAIRING_NOT_SUPPORTED" 59 "UNACCEPTABLE_CONNECTION_INTERVAL" 61 "MIC_FAILURE" 62 "CONNECTION_FAILED_TO_ESTABLISH" 255 "UNKNOWN_REASON_FF" ;
VAL_ 761 VCSEC_activeKeyReason 0 "NONE" 1 "NFC_AUTH" 2 "RKE_AUTH" 3 "BLE_DEVICE_CLOSEST_TO_DOOR" 4 "RKE_ACTION" 5 "ONLY_AUTHED_DEVICE" 6 "AUTO_PRESENT_DOOR_COMMAND" ;
VAL_ 761 VCSEC_AdditionalAuthInfoIndex 0 "ACTIVE_KEY_SHA1" 1 "KEY_WITH_IN_SUMMON_RANGE_0" 2 "KEY_WITH_IN_SUMMON_RANGE_1" 3 "KEY_WITH_IN_SUMMON_RANGE_2" 4 "UNKNOWN_BLE_DEVICE_WITH_IN_SUMMON_RANGE" 5 "WALKUP_UNLOCK_BEHAVIOR" ;
VAL_ 768 BMS_infoIndex 0 "DEPRECATED_0" 1 "DEPRECATED_1" 2 "DEPRECATED_2" 3 "DEPRECATED_3" 4 "DEPRECATED_4" 5 "DEPRECATED_5" 6 "DEPRECATED_6" 7 "DEPRECATED_7" 8 "DEPRECATED_8" 9 "DEPRECATED_9" 10 "BUILD_HWID_COMPONENTID" 11 "PCBAID_ASSYID_USAGEID" 13 "APP_CRC" 14 "BOOTLOADER_SVN" 15 "BOOTLOADER_CRC" 16 "SUBCOMPONENT" 17 "APP_GITHASH" 18 "BOOTLOADER_GITHASH" 19 "VERSION_DEPRECATED" 20 "UDS_PROTOCOL_BOOTCRC" 22 "VARIANTCRC" 25 "PACKAGE_PN_1_7" 26 "PACKAGE_PN_8_14" 27 "PACKAGE_PN_15_20" 29 "PACKAGE_SN_1_7" 30 "PACKAGE_SN_8_14" 31 "SUBCOMPONENT_GITHASH" 255 "END" ;
VAL_ 768 BMS_buildType 0 "UNKNOWN_BUILD" 1 "PLATFORM_BUILD" 2 "LOCAL_BUILD" 3 "TRACEABLE_CI_BUILD" 4 "MFG_BUILD" ;
VAL_ 768 BMS_platformType 0 "UNKNOWN" 3 "MODEL3" 255 "END" ;
VAL_ 768 BMS_hardwareId 252 "CONFIGURABLE_HWID_PLACEHOLDER" ;
VAL_ 769 VCFRONT_infoIndex 0 "DEPRECATED_0" 1 "DEPRECATED_1" 2 "DEPRECATED_2" 3 "DEPRECATED_3" 4 "DEPRECATED_4" 5 "DEPRECATED_5" 6 "DEPRECATED_6" 7 "DEPRECATED_7" 8 "DEPRECATED_8" 9 "DEPRECATED_9" 10 "BUILD_HWID_COMPONENTID" 11 "PCBAID_ASSYID_USAGEID" 13 "APP_CRC" 14 "BOOTLOADER_SVN" 15 "BOOTLOADER_CRC" 16 "SUBCOMPONENT1" 17 "APP_GITHASH" 18 "BOOTLOADER_GITHASH" 19 "VERSION_DEPRECATED" 20 "UDS_PROTOCOL_BOOTCRC" 23 "SUBCOMPONENT2" 24 "SUBCOMPONENT3" 31 "SUBCOMPONENT4" 32 "SUBCOMPONENT5" 33 "SUBCOMPONENT6" 34 "SUBCOMPONENT7" 35 "SUBCOMPONENT8" 36 "SUBCOMPONENT9" 37 "SUBCOMPONENT10" 38 "SUBCOMPONENT11" 39 "SUBCOMPONENT12" 40 "SUBCOMPONENT13" 41 "SUBCOMPONENT14" 255 "END" ;
VAL_ 769 VCFRONT_infoBuildType 0 "UNKNOWN_BUILD" 1 "PLATFORM_BUILD" 2 "LOCAL_BUILD" 3 "TRACEABLE_CI_BUILD" 4 "MFG_BUILD" ;
VAL_ 769 VCFRONT_infoAssemblyId 1 "ASSEMBLY1" 255 "ASSEMBLY_SNA" ;
VAL_ 770 VCLEFT_infoIndex 0 "DEPRECATED_0" 1 "DEPRECATED_1" 2 "DEPRECATED_2" 3 "DEPRECATED_3" 4 "DEPRECATED_4" 5 "DEPRECATED_5" 6 "DEPRECATED_6" 7 "DEPRECATED_7" 8 "DEPRECATED_8" 9 "DEPRECATED_9" 10 "BUILD_HWID_COMPONENTID" 11 "PCBAID_ASSYID_USAGEID" 13 "APP_CRC" 14 "BOOTLOADER_SVN" 15 "BOOTLOADER_CRC" 16 "SUBCOMPONENT1" 17 "APP_GITHASH" 18 "BOOTLOADER_GITHASH" 19 "VERSION_DEPRECATED" 20 "UDS_PROTOCOL_BOOTCRC" 23 "SUBCOMPONENT2" 24 "SUBCOMPONENT3" 31 "SUBCOMPONENT4" 32 "SUBCOMPONENT5" 33 "SUBCOMPONENT6" 34 "SUBCOMPONENT7" 35 "SUBCOMPONENT8" 36 "SUBCOMPONENT9" 37 "SUBCOMPONENT10" 38 "SUBCOMPONENT11" 39 "SUBCOMPONENT12" 40 "SUBCOMPONENT13" 41 "SUBCOMPONENT14" 255 "END" ;
VAL_ 770 VCLEFT_infoBuildType 0 "UNKNOWN_BUILD" 1 "PLATFORM_BUILD" 2 "LOCAL_BUILD" 3 "TRACEABLE_CI_BUILD" 4 "MFG_BUILD" ;
VAL_ 770 VCLEFT_infoAssemblyId 1 "ASSEMBLY1" 255 "ASSEMBLY_SNA" ;
VAL_ 771 VCRIGHT_infoIndex 0 "DEPRECATED_0" 1 "DEPRECATED_1" 2 "DEPRECATED_2" 3 "DEPRECATED_3" 4 "DEPRECATED_4" 5 "DEPRECATED_5" 6 "DEPRECATED_6" 7 "DEPRECATED_7" 8 "DEPRECATED_8" 9 "DEPRECATED_9" 10 "BUILD_HWID_COMPONENTID" 11 "PCBAID_ASSYID_USAGEID" 13 "APP_CRC" 14 "BOOTLOADER_SVN" 15 "BOOTLOADER_CRC" 16 "SUBCOMPONENT1" 17 "APP_GITHASH" 18 "BOOTLOADER_GITHASH" 19 "VERSION_DEPRECATED" 20 "UDS_PROTOCOL_BOOTCRC" 23 "SUBCOMPONENT2" 24 "SUBCOMPONENT3" 31 "SUBCOMPONENT4" 32 "SUBCOMPONENT5" 33 "SUBCOMPONENT6" 34 "SUBCOMPONENT7" 35 "SUBCOMPONENT8" 36 "SUBCOMPONENT9" 37 "SUBCOMPONENT10" 38 "SUBCOMPONENT11" 39 "SUBCOMPONENT12" 40 "SUBCOMPONENT13" 41 "SUBCOMPONENT14" 255 "END" ;
VAL_ 771 VCRIGHT_infoBuildType 0 "UNKNOWN_BUILD" 1 "PLATFORM_BUILD" 2 "LOCAL_BUILD" 3 "TRACEABLE_CI_BUILD" 4 "MFG_BUILD" ;
VAL_ 771 VCRIGHT_infoAssemblyId 1 "ASSEMBLY1" 255 "ASSEMBLY_SNA" ;
VAL_ 776 OCS1P_occupantClassification 0 "EMPTY" 1 "INHIBIT" 2 "SMALL" 3 "LARGE" 4 "INIT" 5 "NOT_CONFIGURED" 7 "SNA" ;
VAL_ 776 OCS1P_occupantClassificationQF 0 "FAULTED" 1 "NOT_FAULTED" ;
VAL_ 784 HVP_infoIndex 0 "DEPRECATED_0" 1 "DEPRECATED_1" 2 "DEPRECATED_2" 3 "DEPRECATED_3" 4 "DEPRECATED_4" 5 "DEPRECATED_5" 6 "DEPRECATED_6" 7 "DEPRECATED_7" 8 "DEPRECATED_8" 9 "DEPRECATED_9" 10 "BUILD_HWID_COMPONENTID" 11 "PCBAID_ASSYID_USAGEID" 13 "APP_CRC" 14 "BOOTLOADER_SVN" 15 "BOOTLOADER_CRC" 16 "SUBCOMPONENT" 17 "APP_GITHASH" 18 "BOOTLOADER_GITHASH" 19 "VERSION_DEPRECATED" 20 "UDS_PROTOCOL_BOOTCRC" 22 "VARIANTCRC" 25 "PACKAGE_PN_1_7" 26 "PACKAGE_PN_8_14" 27 "PACKAGE_PN_15_20" 29 "PACKAGE_SN_1_7" 30 "PACKAGE_SN_8_14" 31 "SUBCOMPONENT_GITHASH" 255 "END" ;
VAL_ 784 HVP_buildType 0 "UNKNOWN_BUILD" 1 "PLATFORM_BUILD" 2 "LOCAL_BUILD" 3 "TRACEABLE_CI_BUILD" 4 "MFG_BUILD" ;
VAL_ 784 HVP_platformType 0 "UNKNOWN" 3 "MODEL3" 255 "END" ;
VAL_ 784 HVP_hardwareId 252 "CONFIGURABLE_HWID_PLACEHOLDER" ;
VAL_ 787 UI_trackModeRequest 0 "IDLE" 1 "ON" 2 "OFF" ;
VAL_ 787 UI_trackPostCooling 0 "OFF" 1 "ON" ;
VAL_ 787 UI_trackCmpOverclock 0 "OFF" 1 "ON" ;
VAL_ 787 UI_trackModeBrakeTemps 0 "OFF" 1 "ON" ;
VAL_ 789 DIR_tempIndex 0 "Mux0" 1 "Mux1" 2 "Mux2" ;
VAL_ 789 DIR_inverterTQF 0 "INIT" 1 "IRRATIONAL" 2 "RATIONAL" 3 "UNKNOWN" ;
VAL_ 789 DIR_normalFetBurnIn 65535 "SNA" ;
VAL_ 789 DIR_additionalFetBurnIn 65535 "SNA" ;
VAL_ 790 PMF_infoIndex 0 "DEPRECATED_0" 1 "DEPRECATED_1" 2 "DEPRECATED_2" 3 "DEPRECATED_3" 4 "DEPRECATED_4" 5 "DEPRECATED_5" 6 "DEPRECATED_6" 7 "DEPRECATED_7" 8 "DEPRECATED_8" 9 "DEPRECATED_9" 10 "BUILD_HWID_COMPONENTID" 11 "PCBAID_ASSYID_USAGEID" 13 "APP_CRC" 14 "BOOTLOADER_SVN" 15 "BOOTLOADER_CRC" 16 "SUBCOMPONENT" 17 "APP_GITHASH" 18 "BOOTLOADER_GITHASH" 19 "VERSION_DEPRECATED" 20 "UDS_PROTOCOL_BOOTCRC" 21 "DI_BUILD_DATA" 255 "END" ;
VAL_ 790 PMF_buildType 0 "UNKNOWN_BUILD" 1 "PLATFORM_BUILD" 2 "LOCAL_BUILD" 3 "TRACEABLE_CI_BUILD" 4 "MFG_BUILD" ;
VAL_ 790 PMF_hardwareId 252 "CONFIGURABLE_HWID_PLACEHOLDER" ;
VAL_ 793 VCSEC_infoIndex 0 "DEPRECATED_0" 1 "DEPRECATED_1" 2 "DEPRECATED_2" 3 "DEPRECATED_3" 4 "DEPRECATED_4" 5 "DEPRECATED_5" 6 "DEPRECATED_6" 7 "DEPRECATED_7" 8 "DEPRECATED_8" 9 "DEPRECATED_9" 10 "BUILD_HWID_COMPONENTID" 11 "PCBAID_ASSYID_USAGEID" 13 "APP_CRC" 14 "BOOTLOADER_SVN" 15 "BOOTLOADER_CRC" 16 "SUBCOMPONENT1" 17 "APP_GITHASH" 18 "BOOTLOADER_GITHASH" 19 "VERSION_DEPRECATED" 20 "UDS_PROTOCOL_BOOTCRC" 23 "SUBCOMPONENT2" 24 "SUBCOMPONENT3" 31 "SUBCOMPONENT4" 32 "SUBCOMPONENT5" 33 "SUBCOMPONENT6" 34 "SUBCOMPONENT7" 35 "SUBCOMPONENT8" 36 "SUBCOMPONENT9" 37 "SUBCOMPONENT10" 38 "SUBCOMPONENT11" 39 "SUBCOMPONENT12" 40 "SUBCOMPONENT13" 41 "SUBCOMPONENT14" 255 "END" ;
VAL_ 793 VCSEC_infoBuildType 0 "UNKNOWN_BUILD" 1 "PLATFORM_BUILD" 2 "LOCAL_BUILD" 3 "TRACEABLE_CI_BUILD" 4 "MFG_BUILD" ;
VAL_ 793 VCSEC_infoAssemblyId 1 "ASSEMBLY1" 255 "ASSEMBLY_SNA" ;
VAL_ 794 VCRIGHT_frontOccupancyStatus 0 "UNOCCUPIED" 1 "OCCUPIED" 2 "OCCUPANCY_FAULTED" 3 "NOT_CONFIGURED" 7 "OCCUPANCY_SNA" ;
VAL_ 794 VCRIGHT_frontBuckleStatus 0 "UNLATCHED" 1 "LATCHED" 2 "FAULTED" 3 "SNA" ;
VAL_ 794 VCRIGHT_rearCenterBuckleStatus 0 "UNLATCHED" 1 "LATCHED" 2 "FAULTED" 3 "SNA" ;
VAL_ 794 VCRIGHT_rearRightBuckleStatus 0 "UNLATCHED" 1 "LATCHED" 2 "FAULTED" 3 "SNA" ;
VAL_ 794 VCRIGHT_rearRightOccupancyStatus 0 "UNOCCUPIED" 1 "OCCUPIED" 2 "OCCUPANCY_FAULTED" 3 "OCCUPANCY_SNA" ;
VAL_ 794 VCRIGHT_3RowLeftBuckleStatus 0 "UNLATCHED" 1 "LATCHED" 2 "FAULTED" 3 "SNA" ;
VAL_ 794 VCRIGHT_3RowRightBuckleStatus 0 "UNLATCHED" 1 "LATCHED" 2 "FAULTED" 3 "SNA" ;
VAL_ 794 VCRIGHT_3RowLeftOccupancyStatus 0 "UNOCCUPIED" 1 "OCCUPIED" 2 "OCCUPANCY_FAULTED" 3 "OCCUPANCY_SNA" ;
VAL_ 794 VCRIGHT_3RowRightOccupancyStatus 0 "UNOCCUPIED" 1 "OCCUPIED" 2 "OCCUPANCY_FAULTED" 3 "OCCUPANCY_SNA" ;
VAL_ 794 VCRIGHT_seatTrackPosition 0 "FORWARD" 1 "REARWARD" 2 "NOT_CONFIGURED" 3 "FAULTED" 7 "SNA" ;
VAL_ 794 VCRIGHT_occupantClassification 0 "EMPTY" 1 "INHIBIT" 2 "SMALL" 3 "LARGE" 4 "INIT" 5 "NOT_CONFIGURED" 7 "SNA" ;
VAL_ 794 VCRIGHT_occupantClassificationQF 0 "FAULTED" 1 "NOT_FAULTED" ;
VAL_ 796 CC_currentLimit 255 "SNA" ;
VAL_ 796 CC_pilotState 0 "READY" 1 "IDLE" 2 "FAULTED" 3 "SNA" ;
VAL_ 796 CC_numPhases 0 "SNA" ;
VAL_ 796 CC_line1Voltage 511 "SNA" ;
VAL_ 796 CC_gridGrounding 0 "TN_TT" 1 "IT_SplitPhase" 2 "SNA" ;
VAL_ 796 CC_line2Voltage 511 "SNA" ;
VAL_ 796 CC_line3Voltage 511 "SNA" ;
VAL_ 797 CC_chgStatus2Index 0 "Mux0" ;
VAL_ 797 CC_buttonState 0 "RELEASED" 1 "PRESSED" ;
VAL_ 798 CP_matrixIndex 0 "AlertMatrix0" 1 "AlertMatrix1" 2 "AlertMatrix2" ;
VAL_ 799 TPMS_pressureFL 255 "TPMS_PRESSURE_SNA" ;
VAL_ 799 TPMS_temperatureFL 255 "TPMS_TEMPERATURE_SNA" ;
VAL_ 799 TPMS_pressureFR 255 "TPMS_PRESSURE_SNA" ;
VAL_ 799 TPMS_temperatureFR 255 "TPMS_TEMPERATURE_SNA" ;
VAL_ 799 TPMS_pressureRL 255 "TPMS_PRESSURE_SNA" ;
VAL_ 799 TPMS_temperatureRL 255 "TPMS_TEMPERATURE_SNA" ;
VAL_ 799 TPMS_pressureRR 255 "TPMS_PRESSURE_SNA" ;
VAL_ 799 TPMS_temperatureRR 255 "TPMS_TEMPERATURE_SNA" ;
